VERSION "created by canmatrix"

NS_ :

BS_:

BU_:

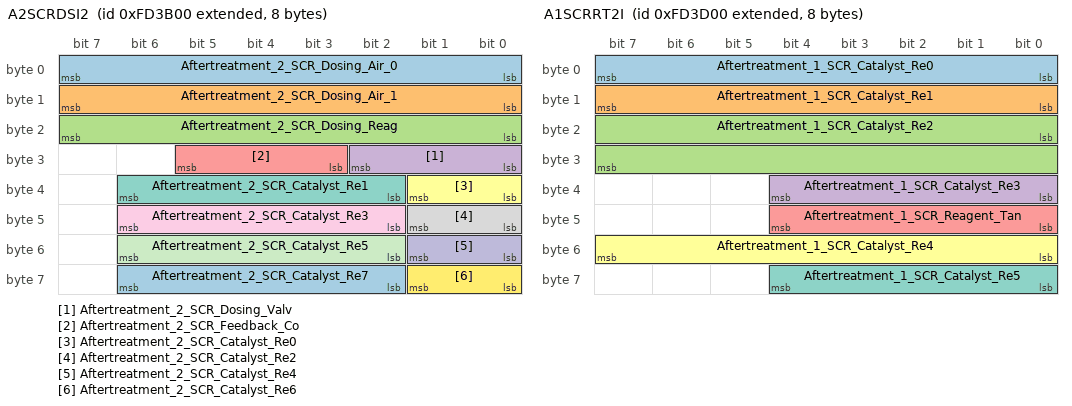
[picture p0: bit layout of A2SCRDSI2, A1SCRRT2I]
BO_ 2164079360 A2SCRDSI2: 8 Vector__XXX
 SG_ Aftertreatment_2_SCR_Dosing_Air_0 : 0|8@1+ (1,0) [0|255] "" Vector__XXX
 SG_ Aftertreatment_2_SCR_Dosing_Air_1 : 8|8@1+ (1,0) [0|255] "" Vector__XXX
 SG_ Aftertreatment_2_SCR_Dosing_Reag : 16|8@1+ (1,0) [0|255] "" Vector__XXX
 SG_ Aftertreatment_2_SCR_Dosing_Valv : 24|3@1+ (1,0) [0|7] "" Vector__XXX
 SG_ Aftertreatment_2_SCR_Feedback_Co : 27|3@1+ (1,0) [0|7] "" Vector__XXX
 SG_ Aftertreatment_2_SCR_Catalyst_Re0 : 32|2@1+ (1,0) [0|3] "" Vector__XXX
 SG_ Aftertreatment_2_SCR_Catalyst_Re1 : 34|5@1+ (1,0) [0|31] "" Vector__XXX
 SG_ Aftertreatment_2_SCR_Catalyst_Re2 : 40|2@1+ (1,0) [0|3] "" Vector__XXX
 SG_ Aftertreatment_2_SCR_Catalyst_Re3 : 42|5@1+ (1,0) [0|31] "" Vector__XXX
 SG_ Aftertreatment_2_SCR_Catalyst_Re4 : 48|2@1+ (1,0) [0|3] "" Vector__XXX
 SG_ Aftertreatment_2_SCR_Catalyst_Re5 : 50|5@1+ (1,0) [0|31] "" Vector__XXX
 SG_ Aftertreatment_2_SCR_Catalyst_Re6 : 56|2@1+ (1,0) [0|3] "" Vector__XXX
 SG_ Aftertreatment_2_SCR_Catalyst_Re7 : 58|5@1+ (1,0) [0|31] "" Vector__XXX

BO_ 2164079616 A1SCRRSI: 8 Vector__XXX
 SG_ Aftertreatment_1_SCR_Catalyst_Re0 : 0|16@1+ (1,0) [0|65535] "" Vector__XXX
 SG_ Aftertreatment_1_SCR_Catalyst_Re1 : 16|8@1+ (1,0) [0|255] "" Vector__XXX
 SG_ Aftertreatment_1_SCR_Catalyst_Re2 : 24|8@1+ (1,0) [0|255] "" Vector__XXX

BO_ 2164079872 A1SCRRT2I: 8 Vector__XXX
 SG_ Aftertreatment_1_SCR_Catalyst_Re0 : 0|8@1+ (1,0) [0|255] "" Vector__XXX
 SG_ Aftertreatment_1_SCR_Catalyst_Re1 : 8|8@1+ (1,0) [0|255] "" Vector__XXX
 SG_ Aftertreatment_1_SCR_Catalyst_Re2 : 16|16@1+ (1,0) [0|65535] "" Vector__XXX
 SG_ Aftertreatment_1_SCR_Catalyst_Re3 : 32|5@1+ (1,0) [0|31] "" Vector__XXX
 SG_ Aftertreatment_1_SCR_Reagent_Tan : 40|5@1+ (1,0) [0|31] "" Vector__XXX
 SG_ Aftertreatment_1_SCR_Catalyst_Re4 : 48|8@1+ (1,0) [0|255] "" Vector__XXX
 SG_ Aftertreatment_1_SCR_Catalyst_Re5 : 56|5@1+ (1,0) [0|31] "" Vector__XXX

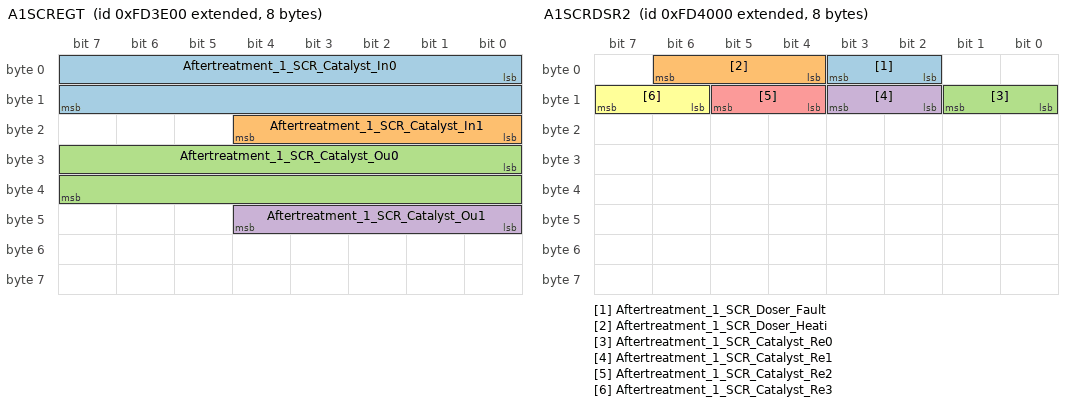
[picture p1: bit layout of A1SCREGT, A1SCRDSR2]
BO_ 2164080128 A1SCREGT: 8 Vector__XXX
 SG_ Aftertreatment_1_SCR_Catalyst_In0 : 0|16@1+ (1,0) [0|65535] "" Vector__XXX
 SG_ Aftertreatment_1_SCR_Catalyst_In1 : 16|5@1+ (1,0) [0|31] "" Vector__XXX
 SG_ Aftertreatment_1_SCR_Catalyst_Ou0 : 24|16@1+ (1,0) [0|65535] "" Vector__XXX
 SG_ Aftertreatment_1_SCR_Catalyst_Ou1 : 40|5@1+ (1,0) [0|31] "" Vector__XXX

BO_ 2164080384 A1SCREGP: 8 Vector__XXX
 SG_ Aftertreatment_1_SCR_Catalyst_Ex0 : 0|16@1+ (1,0) [0|65535] "" Vector__XXX
 SG_ Aftertreatment_1_SCR_Catalyst_Ex1 : 16|5@1+ (1,0) [0|31] "" Vector__XXX

BO_ 2164080640 A1SCRDSR2: 8 Vector__XXX
 SG_ Aftertreatment_1_SCR_Doser_Fault : 2|2@1+ (1,0) [0|3] "" Vector__XXX
 SG_ Aftertreatment_1_SCR_Doser_Heati : 4|3@1+ (1,0) [0|7] "" Vector__XXX
 SG_ Aftertreatment_1_SCR_Catalyst_Re0 : 8|2@1+ (1,0) [0|3] "" Vector__XXX
 SG_ Aftertreatment_1_SCR_Catalyst_Re1 : 10|2@1+ (1,0) [0|3] "" Vector__XXX
 SG_ Aftertreatment_1_SCR_Catalyst_Re2 : 12|2@1+ (1,0) [0|3] "" Vector__XXX
 SG_ Aftertreatment_1_SCR_Catalyst_Re3 : 14|2@1+ (1,0) [0|3] "" Vector__XXX

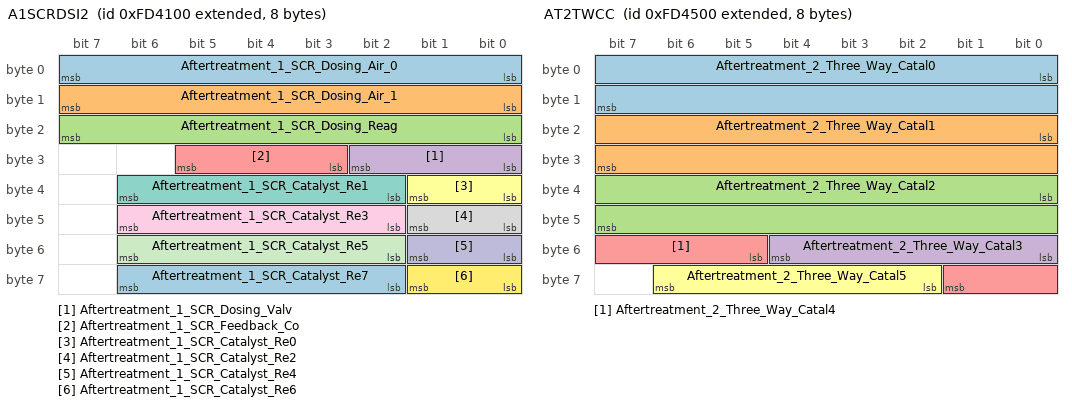
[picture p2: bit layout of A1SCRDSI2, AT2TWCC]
BO_ 2164080896 A1SCRDSI2: 8 Vector__XXX
 SG_ Aftertreatment_1_SCR_Dosing_Air_0 : 0|8@1+ (1,0) [0|255] "" Vector__XXX
 SG_ Aftertreatment_1_SCR_Dosing_Air_1 : 8|8@1+ (1,0) [0|255] "" Vector__XXX
 SG_ Aftertreatment_1_SCR_Dosing_Reag : 16|8@1+ (1,0) [0|255] "" Vector__XXX
 SG_ Aftertreatment_1_SCR_Dosing_Valv : 24|3@1+ (1,0) [0|7] "" Vector__XXX
 SG_ Aftertreatment_1_SCR_Feedback_Co : 27|3@1+ (1,0) [0|7] "" Vector__XXX
 SG_ Aftertreatment_1_SCR_Catalyst_Re0 : 32|2@1+ (1,0) [0|3] "" Vector__XXX
 SG_ Aftertreatment_1_SCR_Catalyst_Re1 : 34|5@1+ (1,0) [0|31] "" Vector__XXX
 SG_ Aftertreatment_1_SCR_Catalyst_Re2 : 40|2@1+ (1,0) [0|3] "" Vector__XXX
 SG_ Aftertreatment_1_SCR_Catalyst_Re3 : 42|5@1+ (1,0) [0|31] "" Vector__XXX
 SG_ Aftertreatment_1_SCR_Catalyst_Re4 : 48|2@1+ (1,0) [0|3] "" Vector__XXX
 SG_ Aftertreatment_1_SCR_Catalyst_Re5 : 50|5@1+ (1,0) [0|31] "" Vector__XXX
 SG_ Aftertreatment_1_SCR_Catalyst_Re6 : 56|2@1+ (1,0) [0|3] "" Vector__XXX
 SG_ Aftertreatment_1_SCR_Catalyst_Re7 : 58|5@1+ (1,0) [0|31] "" Vector__XXX

BO_ 2164081664 AT2FC2: 8 Vector__XXX
 SG_ Aftertreatment_2_Fuel_Pressure_2 : 0|16@1+ (1,0) [0|65535] "" Vector__XXX

BO_ 2164081920 AT2TWCC: 8 Vector__XXX
 SG_ Aftertreatment_2_Three_Way_Catal0 : 0|16@1+ (1,0) [0|65535] "" Vector__XXX
 SG_ Aftertreatment_2_Three_Way_Catal1 : 16|16@1+ (1,0) [0|65535] "" Vector__XXX
 SG_ Aftertreatment_2_Three_Way_Catal2 : 32|16@1+ (1,0) [0|65535] "" Vector__XXX
 SG_ Aftertreatment_2_Three_Way_Catal3 : 48|5@1+ (1,0) [0|31] "" Vector__XXX
 SG_ Aftertreatment_2_Three_Way_Catal4 : 53|5@1+ (1,0) [0|31] "" Vector__XXX
 SG_ Aftertreatment_2_Three_Way_Catal5 : 58|5@1+ (1,0) [0|31] "" Vector__XXX

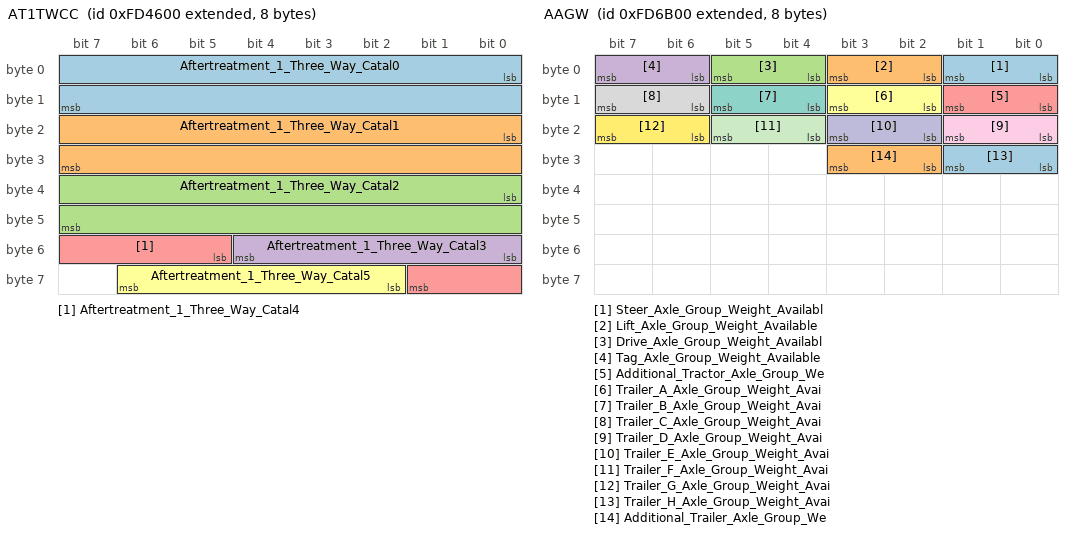
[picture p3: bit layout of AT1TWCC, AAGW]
BO_ 2164082176 AT1TWCC: 8 Vector__XXX
 SG_ Aftertreatment_1_Three_Way_Catal0 : 0|16@1+ (1,0) [0|65535] "" Vector__XXX
 SG_ Aftertreatment_1_Three_Way_Catal1 : 16|16@1+ (1,0) [0|65535] "" Vector__XXX
 SG_ Aftertreatment_1_Three_Way_Catal2 : 32|16@1+ (1,0) [0|65535] "" Vector__XXX
 SG_ Aftertreatment_1_Three_Way_Catal3 : 48|5@1+ (1,0) [0|31] "" Vector__XXX
 SG_ Aftertreatment_1_Three_Way_Catal4 : 53|5@1+ (1,0) [0|31] "" Vector__XXX
 SG_ Aftertreatment_1_Three_Way_Catal5 : 58|5@1+ (1,0) [0|31] "" Vector__XXX

BO_ 2164082432 TML: 8 Vector__XXX
 SG_ Transmission_Mode_Label : 0|200@1+ (1,0) [0|1.606938044258990275541962092E+060] "" Vector__XXX

BO_ 2164082688 O2FT2: 8 Vector__XXX
 SG_ Long_term_Fuel_Trim___Bank_2 : 0|16@1+ (1,0) [0|65535] "" Vector__XXX
 SG_ Short_term_Fuel_Trim___Bank_2 : 16|16@1+ (1,0) [0|65535] "" Vector__XXX
 SG_ Engine_Exhaust_Gas_Oxygen_Sensor : 32|4@1+ (1,0) [0|15] "" Vector__XXX

BO_ 2164082944 O2FT1: 8 Vector__XXX
 SG_ Long_term_Fuel_Trim___Bank_1 : 0|16@1+ (1,0) [0|65535] "" Vector__XXX
 SG_ Short_term_Fuel_Trim___Bank_1 : 16|16@1+ (1,0) [0|65535] "" Vector__XXX
 SG_ Engine_Exhaust_Gas_Oxygen_Sensor : 32|4@1+ (1,0) [0|15] "" Vector__XXX

BO_ 2164084992 ACCVC: 8 Vector__XXX
 SG_ Aftercooler_Coolant_Thermostat_M : 0|2@1+ (1,0) [0|3] "" Vector__XXX
 SG_ Desired_Aftercooler_Coolant_Inle : 8|8@1+ (1,0) [0|255] "" Vector__XXX
 SG_ Desired_Aftercooler_Coolant_Ther : 16|8@1+ (1,0) [0|255] "" Vector__XXX

BO_ 2164085248 ECCVC: 8 Vector__XXX
 SG_ Engine_Coolant_Thermostat_Mode : 0|2@1+ (1,0) [0|3] "" Vector__XXX
 SG_ Desired_Engine_Coolant_Pump_Outl : 8|8@1+ (1,0) [0|255] "" Vector__XXX
 SG_ Desired_Engine_Coolant_Thermosta : 16|8@1+ (1,0) [0|255] "" Vector__XXX

BO_ 2164085504 EAI: 8 Vector__XXX
 SG_ Engine_Exhaust_Gas_Temperature_A0 : 0|16@1+ (1,0) [0|65535] "" Vector__XXX
 SG_ Engine_Exhaust_Gas_Temperature_A1 : 16|16@1+ (1,0) [0|65535] "" Vector__XXX
 SG_ Engine_Exhaust_Gas_Temperature_A2 : 32|16@1+ (1,0) [0|65535] "" Vector__XXX

BO_ 2164090112 AT1FC2: 8 Vector__XXX
 SG_ Aftertreatment_1_Fuel_Pressure_2 : 0|16@1+ (1,0) [0|65535] "" Vector__XXX

BO_ 2164090368 ET4: 8 Vector__XXX
 SG_ Engine_Coolant_Temperature_2 : 0|8@1+ (1,0) [0|255] "" Vector__XXX
 SG_ Engine_Coolant_Pump_Outlet_Tempe : 8|8@1+ (1,0) [0|255] "" Vector__XXX
 SG_ Engine_Coolant_Thermostat_Openin : 16|8@1+ (1,0) [0|255] "" Vector__XXX
 SG_ Engine_Exhaust_Valve_Actuation_S : 24|16@1+ (1,0) [0|65535] "" Vector__XXX

BO_ 2164090624 ZNVW: 8 Vector__XXX
 SG_ Zero_Net_Vehicle_Weight_Change : 0|2@1+ (1,0) [0|3] "" Vector__XXX

BO_ 2164090880 GCVW: 8 Vector__XXX
 SG_ Gross_Combination_Weight : 0|24@1+ (1,0) [0|16777215] "" Vector__XXX
 SG_ Net_Vehicle_Weight_Change : 24|24@1+ (1,0) [0|16777215] "" Vector__XXX

BO_ 2164091136 AGCW: 8 Vector__XXX
 SG_ Axle_Group_Location : 0|4@1+ (1,0) [0|15] "" Vector__XXX
 SG_ Axle_Group_Empty_Weight_Calibrat : 8|16@1+ (1,0) [0|65535] "" Vector__XXX
 SG_ Axle_Group_Full_Weight_Calibrati : 24|16@1+ (1,0) [0|65535] "" Vector__XXX

BO_ 2164091392 AGW: 8 Vector__XXX
 SG_ Axle_Group_Location : 0|4@1+ (1,0) [0|15] "" Vector__XXX
 SG_ Axle_Group_Weight : 8|16@1+ (1,0) [0|65535] "" Vector__XXX

BO_ 2164091648 AAGW: 8 Vector__XXX
 SG_ Steer_Axle_Group_Weight_Availabl : 0|2@1+ (1,0) [0|3] "" Vector__XXX
 SG_ Lift_Axle_Group_Weight_Available : 2|2@1+ (1,0) [0|3] "" Vector__XXX
 SG_ Drive_Axle_Group_Weight_Availabl : 4|2@1+ (1,0) [0|3] "" Vector__XXX
 SG_ Tag_Axle_Group_Weight_Available : 6|2@1+ (1,0) [0|3] "" Vector__XXX
 SG_ Additional_Tractor_Axle_Group_We : 8|2@1+ (1,0) [0|3] "" Vector__XXX
 SG_ Trailer_A_Axle_Group_Weight_Avai : 10|2@1+ (1,0) [0|3] "" Vector__XXX
 SG_ Trailer_B_Axle_Group_Weight_Avai : 12|2@1+ (1,0) [0|3] "" Vector__XXX
 SG_ Trailer_C_Axle_Group_Weight_Avai : 14|2@1+ (1,0) [0|3] "" Vector__XXX
 SG_ Trailer_D_Axle_Group_Weight_Avai : 16|2@1+ (1,0) [0|3] "" Vector__XXX
 SG_ Trailer_E_Axle_Group_Weight_Avai : 18|2@1+ (1,0) [0|3] "" Vector__XXX
 SG_ Trailer_F_Axle_Group_Weight_Avai : 20|2@1+ (1,0) [0|3] "" Vector__XXX
 SG_ Trailer_G_Axle_Group_Weight_Avai : 22|2@1+ (1,0) [0|3] "" Vector__XXX
 SG_ Trailer_H_Axle_Group_Weight_Avai : 24|2@1+ (1,0) [0|3] "" Vector__XXX
 SG_ Additional_Trailer_Axle_Group_We : 26|2@1+ (1,0) [0|3] "" Vector__XXX

BO_ 2164091904 AT2AC2: 8 Vector__XXX
 SG_ Aftertreatment_2_Secondary_Air_D : 0|16@1+ (1,0) [0|65535] "" Vector__XXX
 SG_ Aftertreatment_2_Secondary_Air_T : 16|16@1+ (1,0) [0|65535] "" Vector__XXX
 SG_ Aftertreatment_2_Secondary_Air_M : 32|16@1+ (1,0) [0|65535] "" Vector__XXX
 SG_ Aftertreatment_2_Secondary_Air_P : 48|16@1+ (1,0) [0|65535] "" Vector__XXX

BO_ 2164092160 AT1AC2: 8 Vector__XXX
 SG_ Aftertreatment_1_Secondary_Air_D : 0|16@1+ (1,0) [0|65535] "" Vector__XXX
 SG_ Aftertreatment_1_Secondary_Air_T : 16|16@1+ (1,0) [0|65535] "" Vector__XXX
 SG_ Aftertreatment_1_Secondary_Air_M : 32|16@1+ (1,0) [0|65535] "" Vector__XXX
 SG_ Aftertreatment_1_Secondary_Air_P : 48|16@1+ (1,0) [0|65535] "" Vector__XXX

BO_ 2164092416 SCR1: 8 Vector__XXX
 SG_ Aftertreatment_1_SCR_Average_Cat : 0|16@1+ (1,0) [0|65535] "" Vector__XXX
 SG_ Aftertreatment_1_SCR_Commanded_C : 16|16@1+ (1,0) [0|65535] "" Vector__XXX
 SG_ Aftertreatment_1_SCR_Catalyst_Co : 32|8@1+ (1,0) [0|255] "" Vector__XXX

BO_ 2164092672 EEC8: 8 Vector__XXX
 SG_ Engine_Exhaust_Gas_Recirculation : 0|16@1+ (1,0) [0|65535] "" Vector__XXX

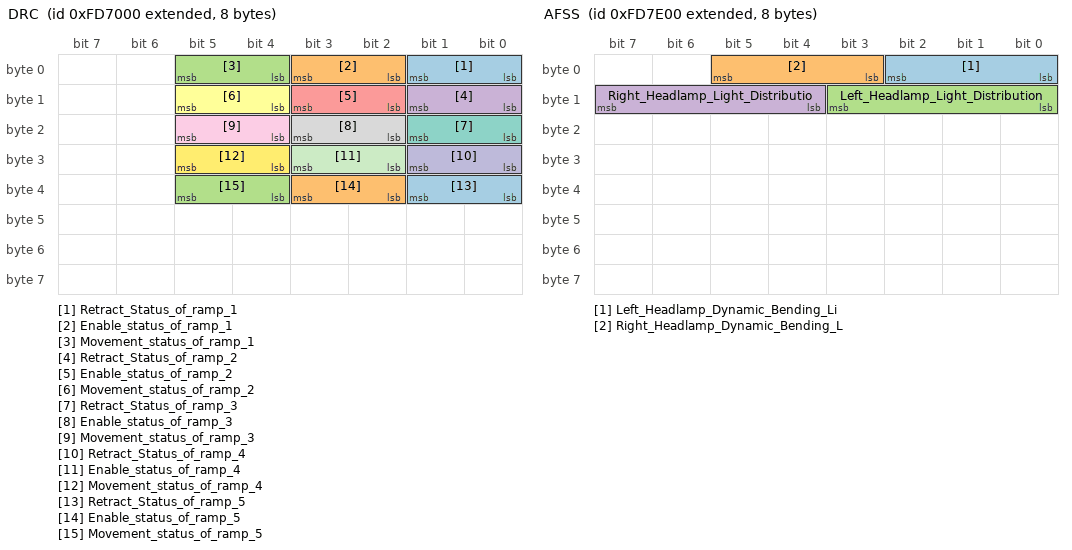
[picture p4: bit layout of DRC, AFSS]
BO_ 2164092928 DRC: 8 Vector__XXX
 SG_ Retract_Status_of_ramp_1 : 0|2@1+ (1,0) [0|3] "" Vector__XXX
 SG_ Enable_status_of_ramp_1 : 2|2@1+ (1,0) [0|3] "" Vector__XXX
 SG_ Movement_status_of_ramp_1 : 4|2@1+ (1,0) [0|3] "" Vector__XXX
 SG_ Retract_Status_of_ramp_2 : 8|2@1+ (1,0) [0|3] "" Vector__XXX
 SG_ Enable_status_of_ramp_2 : 10|2@1+ (1,0) [0|3] "" Vector__XXX
 SG_ Movement_status_of_ramp_2 : 12|2@1+ (1,0) [0|3] "" Vector__XXX
 SG_ Retract_Status_of_ramp_3 : 16|2@1+ (1,0) [0|3] "" Vector__XXX
 SG_ Enable_status_of_ramp_3 : 18|2@1+ (1,0) [0|3] "" Vector__XXX
 SG_ Movement_status_of_ramp_3 : 20|2@1+ (1,0) [0|3] "" Vector__XXX
 SG_ Retract_Status_of_ramp_4 : 24|2@1+ (1,0) [0|3] "" Vector__XXX
 SG_ Enable_status_of_ramp_4 : 26|2@1+ (1,0) [0|3] "" Vector__XXX
 SG_ Movement_status_of_ramp_4 : 28|2@1+ (1,0) [0|3] "" Vector__XXX
 SG_ Retract_Status_of_ramp_5 : 32|2@1+ (1,0) [0|3] "" Vector__XXX
 SG_ Enable_status_of_ramp_5 : 34|2@1+ (1,0) [0|3] "" Vector__XXX
 SG_ Movement_status_of_ramp_5 : 36|2@1+ (1,0) [0|3] "" Vector__XXX

BO_ 2164093184 BSA: 8 Vector__XXX
 SG_ Tractor_Brake_Stroke_Axle_1_Left : 0|3@1+ (1,0) [0|7] "" Vector__XXX
 SG_ Tractor_Brake_Stroke_Axle_1_Righ : 3|3@1+ (1,0) [0|7] "" Vector__XXX
 SG_ Tractor_Brake_Stroke_Axle_2_Left : 6|3@1+ (1,0) [0|7] "" Vector__XXX
 SG_ Tractor_Brake_Stroke_Axle_2_Righ : 9|3@1+ (1,0) [0|7] "" Vector__XXX
 SG_ Tractor_Brake_Stroke_Axle_3_Left : 12|3@1+ (1,0) [0|7] "" Vector__XXX
 SG_ Tractor_Brake_Stroke_Axle_3_Righ : 15|3@1+ (1,0) [0|7] "" Vector__XXX
 SG_ Tractor_Brake_Stroke_Axle_4_Left : 18|3@1+ (1,0) [0|7] "" Vector__XXX
 SG_ Tractor_Brake_Stroke_Axle_4_Righ : 21|3@1+ (1,0) [0|7] "" Vector__XXX
 SG_ Tractor_Brake_Stroke_Axle_5_Left : 24|3@1+ (1,0) [0|7] "" Vector__XXX
 SG_ Tractor_Brake_Stroke_Axle_5_Righ : 27|3@1+ (1,0) [0|7] "" Vector__XXX
 SG_ Trailer_Brake_Stroke_Axle_1_Left : 30|3@1+ (1,0) [0|7] "" Vector__XXX
 SG_ Trailer_Brake_Stroke_Axle_1_Righ : 33|3@1+ (1,0) [0|7] "" Vector__XXX
 SG_ Trailer_Brake_Stroke_Axle_2_Left : 36|3@1+ (1,0) [0|7] "" Vector__XXX
 SG_ Trailer_Brake_Stroke_Axle_2_Righ : 39|3@1+ (1,0) [0|7] "" Vector__XXX
 SG_ Trailer_Brake_Stroke_Axle_3_Left : 42|3@1+ (1,0) [0|7] "" Vector__XXX
 SG_ Trailer_Brake_Stroke_Axle_3_Righ : 45|3@1+ (1,0) [0|7] "" Vector__XXX
 SG_ Trailer_Brake_Stroke_Axle_4_Left : 48|3@1+ (1,0) [0|7] "" Vector__XXX
 SG_ Trailer_Brake_Stroke_Axle_4_Righ : 51|3@1+ (1,0) [0|7] "" Vector__XXX
 SG_ Trailer_Brake_Stroke_Axle_5_Left : 54|3@1+ (1,0) [0|7] "" Vector__XXX
 SG_ Trailer_Brake_Stroke_Axle_5_Righ : 57|3@1+ (1,0) [0|7] "" Vector__XXX

BO_ 2164093440 ESV6: 8 Vector__XXX
 SG_ Engine_Spark_Plug_21 : 0|16@1+ (1,0) [0|65535] "" Vector__XXX
 SG_ Engine_Spark_Plug_22 : 16|16@1+ (1,0) [0|65535] "" Vector__XXX
 SG_ Engine_Spark_Plug_23 : 32|16@1+ (1,0) [0|65535] "" Vector__XXX
 SG_ Engine_Spark_Plug_24 : 48|16@1+ (1,0) [0|65535] "" Vector__XXX

BO_ 2164093696 ESV5: 8 Vector__XXX
 SG_ Engine_Spark_Plug_17 : 0|16@1+ (1,0) [0|65535] "" Vector__XXX
 SG_ Engine_Spark_Plug_18 : 16|16@1+ (1,0) [0|65535] "" Vector__XXX
 SG_ Engine_Spark_Plug_19 : 32|16@1+ (1,0) [0|65535] "" Vector__XXX
 SG_ Engine_Spark_Plug_20 : 48|16@1+ (1,0) [0|65535] "" Vector__XXX

BO_ 2164093952 ESV4: 8 Vector__XXX
 SG_ Engine_Spark_Plug_13 : 0|16@1+ (1,0) [0|65535] "" Vector__XXX
 SG_ Engine_Spark_Plug_14 : 16|16@1+ (1,0) [0|65535] "" Vector__XXX
 SG_ Engine_Spark_Plug_15 : 32|16@1+ (1,0) [0|65535] "" Vector__XXX
 SG_ Engine_Spark_Plug_16 : 48|16@1+ (1,0) [0|65535] "" Vector__XXX

BO_ 2164094208 ESV3: 8 Vector__XXX
 SG_ Engine_Spark_Plug_9 : 0|16@1+ (1,0) [0|65535] "" Vector__XXX
 SG_ Engine_Spark_Plug_10 : 16|16@1+ (1,0) [0|65535] "" Vector__XXX
 SG_ Engine_Spark_Plug_11 : 32|16@1+ (1,0) [0|65535] "" Vector__XXX
 SG_ Engine_Spark_Plug_12 : 48|16@1+ (1,0) [0|65535] "" Vector__XXX

BO_ 2164094464 ESV2: 8 Vector__XXX
 SG_ Engine_Spark_Plug_5 : 0|16@1+ (1,0) [0|65535] "" Vector__XXX
 SG_ Engine_Spark_Plug_6 : 16|16@1+ (1,0) [0|65535] "" Vector__XXX
 SG_ Engine_Spark_Plug_7 : 32|16@1+ (1,0) [0|65535] "" Vector__XXX
 SG_ Engine_Spark_Plug_8 : 48|16@1+ (1,0) [0|65535] "" Vector__XXX

BO_ 2164094720 ESV1: 8 Vector__XXX
 SG_ Engine_Spark_Plug_1 : 0|16@1+ (1,0) [0|65535] "" Vector__XXX
 SG_ Engine_Spark_Plug_2 : 16|16@1+ (1,0) [0|65535] "" Vector__XXX
 SG_ Engine_Spark_Plug_3 : 32|16@1+ (1,0) [0|65535] "" Vector__XXX
 SG_ Engine_Spark_Plug_4 : 48|16@1+ (1,0) [0|65535] "" Vector__XXX

BO_ 2164094976 AT2TI: 32 Vector__XXX
 SG_ Aftertreatment_2_Trip_Fuel_Used : 0|32@1+ (1,0) [0|4294967295] "" Vector__XXX
 SG_ Aftertreatment_2_Trip_Active_Reg : 32|32@1+ (1,0) [0|4294967295] "" Vector__XXX
 SG_ Aftertreatment_2_Trip_Disabled_T : 64|32@1+ (1,0) [0|4294967295] "" Vector__XXX
 SG_ Aftertreatment_2_Trip_Number_of_0 : 96|32@1+ (1,0) [0|4294967295] "" Vector__XXX
 SG_ Aftertreatment_2_Trip_Passive_Re : 128|32@1+ (1,0) [0|4294967295] "" Vector__XXX
 SG_ Aftertreatment_2_Trip_Number_of_1 : 160|32@1+ (1,0) [0|4294967295] "" Vector__XXX
 SG_ Aftertreatment_2_Trip_Number_of_2 : 192|32@1+ (1,0) [0|4294967295] "" Vector__XXX
 SG_ Aftertreatment_2_Trip_Number_of_3 : 224|32@1+ (1,0) [0|4294967295] "" Vector__XXX

BO_ 2164095232 AT1TI: 32 Vector__XXX
 SG_ Aftertreatment_1_Trip_Fuel_Used : 0|32@1+ (1,0) [0|4294967295] "" Vector__XXX
 SG_ Aftertreatment_1_Trip_Active_Reg : 32|32@1+ (1,0) [0|4294967295] "" Vector__XXX
 SG_ Aftertreatment_1_Trip_Disabled_T : 64|32@1+ (1,0) [0|4294967295] "" Vector__XXX
 SG_ Aftertreatment_1_Trip_Number_of_0 : 96|32@1+ (1,0) [0|4294967295] "" Vector__XXX
 SG_ Aftertreatment_1_Trip_Passive_Re : 128|32@1+ (1,0) [0|4294967295] "" Vector__XXX
 SG_ Aftertreatment_1_Trip_Number_of_1 : 160|32@1+ (1,0) [0|4294967295] "" Vector__XXX
 SG_ Aftertreatment_1_Trip_Number_of_2 : 192|32@1+ (1,0) [0|4294967295] "" Vector__XXX
 SG_ Aftertreatment_1_Trip_Number_of_3 : 224|32@1+ (1,0) [0|4294967295] "" Vector__XXX

BO_ 2164095488 AT2S: 8 Vector__XXX
 SG_ Diesel_Particulate_Filter_2_Soot : 0|8@1+ (1,0) [0|255] "" Vector__XXX
 SG_ Diesel_Particulate_Filter_2_Ash_ : 8|8@1+ (1,0) [0|255] "" Vector__XXX
 SG_ Diesel_Particulate_Filter_2_Time : 16|32@1+ (1,0) [0|4294967295] "" Vector__XXX

BO_ 2164095744 AT1S: 8 Vector__XXX
 SG_ Diesel_Particulate_Filter_1_Soot : 0|8@1+ (1,0) [0|255] "" Vector__XXX
 SG_ Diesel_Particulate_Filter_1_Ash_ : 8|8@1+ (1,0) [0|255] "" Vector__XXX
 SG_ Diesel_Particulate_Filter_1_Time : 16|32@1+ (1,0) [0|4294967295] "" Vector__XXX

BO_ 2164096000 DPFC1: 8 Vector__XXX
 SG_ Diesel_Particulate_Filter_Lamp_C : 0|3@1+ (1,0) [0|7] "" Vector__XXX
 SG_ Diesel_Particulate_Filter_Passiv : 8|2@1+ (1,0) [0|3] "" Vector__XXX
 SG_ Diesel_Particulate_Filter_Active0 : 10|2@1+ (1,0) [0|3] "" Vector__XXX
 SG_ Diesel_Particulate_Filter_Status : 12|3@1+ (1,0) [0|7] "" Vector__XXX
 SG_ Diesel_Particulate_Filter_Active1 : 16|2@1+ (1,0) [0|3] "" Vector__XXX
 SG_ Diesel_Particulate_Filter_Active2 : 18|2@1+ (1,0) [0|3] "" Vector__XXX
 SG_ Diesel_Particulate_Filter_Active3 : 20|2@1+ (1,0) [0|3] "" Vector__XXX
 SG_ Diesel_Particulate_Filter_Active4 : 22|2@1+ (1,0) [0|3] "" Vector__XXX
 SG_ Diesel_Particulate_Filter_Active5 : 24|2@1+ (1,0) [0|3] "" Vector__XXX
 SG_ Diesel_Particulate_Filter_Active6 : 26|2@1+ (1,0) [0|3] "" Vector__XXX
 SG_ Diesel_Particulate_Filter_Active7 : 28|2@1+ (1,0) [0|3] "" Vector__XXX
 SG_ Diesel_Particulate_Filter_Active8 : 30|2@1+ (1,0) [0|3] "" Vector__XXX
 SG_ Diesel_Particulate_Filter_Active9 : 32|2@1+ (1,0) [0|3] "" Vector__XXX
 SG_ Diesel_Particulate_Filter_Active10 : 34|2@1+ (1,0) [0|3] "" Vector__XXX
 SG_ Diesel_Particulate_Filter_Active11 : 36|2@1+ (1,0) [0|3] "" Vector__XXX
 SG_ Diesel_Particulate_Filter_Active12 : 38|2@1+ (1,0) [0|3] "" Vector__XXX
 SG_ Diesel_Particulate_Filter_Active13 : 40|2@1+ (1,0) [0|3] "" Vector__XXX
 SG_ Diesel_Particulate_Filter_Active14 : 42|2@1+ (1,0) [0|3] "" Vector__XXX
 SG_ Diesel_Particulate_Filter_Active15 : 44|2@1+ (1,0) [0|3] "" Vector__XXX
 SG_ Diesel_Particulate_Filter_Active16 : 46|2@1+ (1,0) [0|3] "" Vector__XXX
 SG_ Diesel_Particulate_Filter_Automa : 48|2@1+ (1,0) [0|3] "" Vector__XXX
 SG_ Exhaust_System_High_Temperature_ : 50|3@1+ (1,0) [0|7] "" Vector__XXX
 SG_ Diesel_Particulate_Filter_Active17 : 53|3@1+ (1,0) [0|7] "" Vector__XXX

BO_ 2164096512 AFSS: 8 Vector__XXX
 SG_ Left_Headlamp_Dynamic_Bending_Li : 0|3@1+ (1,0) [0|7] "" Vector__XXX
 SG_ Right_Headlamp_Dynamic_Bending_L : 3|3@1+ (1,0) [0|7] "" Vector__XXX
 SG_ Left_Headlamp_Light_Distribution : 8|4@1+ (1,0) [0|15] "" Vector__XXX
 SG_ Right_Headlamp_Light_Distributio : 12|4@1+ (1,0) [0|15] "" Vector__XXX

BO_ 2164096768 EC2: 8 Vector__XXX
 SG_ Maximum_Crank_Attempts_per_Start : 0|8@1+ (1,0) [0|255] "" Vector__XXX

BO_ 2164097280 EGRBV: 8 Vector__XXX
 SG_ EGR_Cooler_Bypass_Actuator_Posti : 0|8@1+ (1,0) [0|255] "" Vector__XXX

BO_ 2164097792 TCI: 8 Vector__XXX
 SG_ Transfer_case_status : 0|3@1+ (1,0) [0|7] "" Vector__XXX

BO_ 2164098048 EFL_P9: 8 Vector__XXX
 SG_ Engine_Intake_Valve_Actuation_Oi0 : 0|16@1+ (1,0) [0|65535] "" Vector__XXX
 SG_ Engine_Intake_Valve_Actuation_Oi1 : 16|16@1+ (1,0) [0|65535] "" Vector__XXX
 SG_ Engine_Intake_Valve_Actuation_Oi2 : 32|16@1+ (1,0) [0|65535] "" Vector__XXX
 SG_ Engine_Intake_Valve_Actuation_Oi3 : 48|16@1+ (1,0) [0|65535] "" Vector__XXX

BO_ 2164098304 EFL_P8: 8 Vector__XXX
 SG_ Engine_Intake_Valve_Actuation_Oi0 : 0|16@1+ (1,0) [0|65535] "" Vector__XXX
 SG_ Engine_Intake_Valve_Actuation_Oi1 : 16|16@1+ (1,0) [0|65535] "" Vector__XXX
 SG_ Engine_Intake_Valve_Actuation_Oi2 : 32|16@1+ (1,0) [0|65535] "" Vector__XXX
 SG_ Engine_Intake_Valve_Actuation_Oi3 : 48|16@1+ (1,0) [0|65535] "" Vector__XXX

BO_ 2164098560 EFL_P7: 8 Vector__XXX
 SG_ Engine_Intake_Valve_Actuation_Oi0 : 0|16@1+ (1,0) [0|65535] "" Vector__XXX
 SG_ Engine_Intake_Valve_Actuation_Oi1 : 16|16@1+ (1,0) [0|65535] "" Vector__XXX
 SG_ Engine_Intake_Valve_Actuation_Oi2 : 32|16@1+ (1,0) [0|65535] "" Vector__XXX
 SG_ Engine_Intake_Valve_Actuation_Oi3 : 48|16@1+ (1,0) [0|65535] "" Vector__XXX

BO_ 2164098816 EFL_P6: 8 Vector__XXX
 SG_ Engine_Intake_Valve_Actuation_Oi0 : 0|16@1+ (1,0) [0|65535] "" Vector__XXX
 SG_ Engine_Intake_Valve_Actuation_Oi1 : 16|16@1+ (1,0) [0|65535] "" Vector__XXX
 SG_ Engine_Intake_Valve_Actuation_Oi2 : 32|16@1+ (1,0) [0|65535] "" Vector__XXX
 SG_ Engine_Intake_Valve_Actuation_Oi3 : 48|16@1+ (1,0) [0|65535] "" Vector__XXX

BO_ 2164099072 EFL_P5: 8 Vector__XXX
 SG_ Engine_Intake_Valve_Actuation_Oi0 : 0|16@1+ (1,0) [0|65535] "" Vector__XXX
 SG_ Engine_Intake_Valve_Actuation_Oi1 : 16|16@1+ (1,0) [0|65535] "" Vector__XXX
 SG_ Engine_Intake_Valve_Actuation_Oi2 : 32|16@1+ (1,0) [0|65535] "" Vector__XXX
 SG_ Engine_Intake_Valve_Actuation_Oi3 : 48|16@1+ (1,0) [0|65535] "" Vector__XXX

BO_ 2164099328 VDS2: 8 Vector__XXX
 SG_ Vehicle_Roll : 0|16@1+ (1,0) [0|65535] "" Vector__XXX

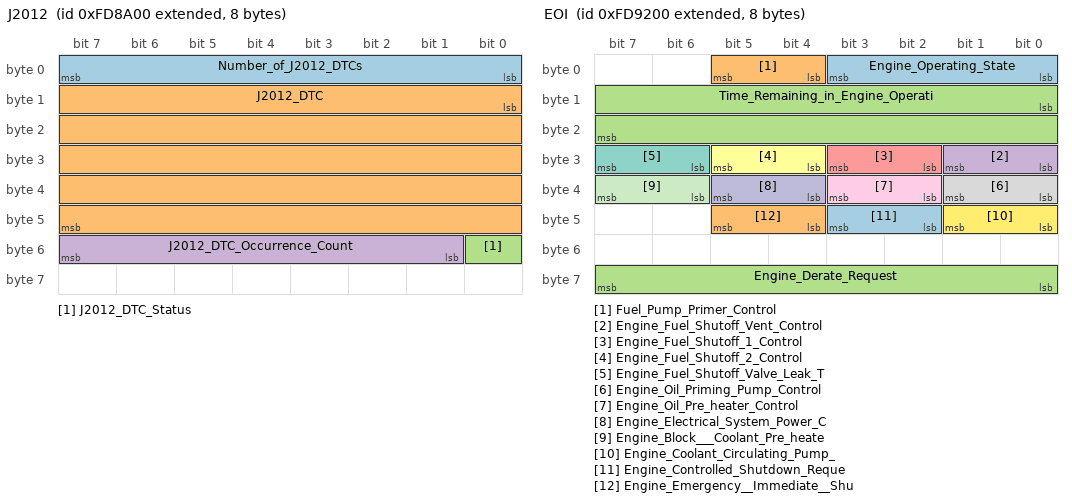
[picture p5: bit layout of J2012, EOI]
BO_ 2164099584 J2012: 8 Vector__XXX
 SG_ Number_of_J2012_DTCs : 0|8@1+ (1,0) [0|255] "" Vector__XXX
 SG_ J2012_DTC : 8|40@1+ (1,0) [0|1099511627775] "" Vector__XXX
 SG_ J2012_DTC_Status : 48|1@1+ (1,0) [0|1] "" Vector__XXX
 SG_ J2012_DTC_Occurrence_Count : 49|7@1+ (1,0) [0|127] "" Vector__XXX

BO_ 2164099840 AT2GP: 8 Vector__XXX
 SG_ Diesel_Particulate_Filter_Intake : 0|16@1+ (1,0) [0|65535] "" Vector__XXX
 SG_ Diesel_Particulate_Filter_Outlet : 16|16@1+ (1,0) [0|65535] "" Vector__XXX

BO_ 2164100096 AT1GP: 8 Vector__XXX
 SG_ Diesel_Particulate_Filter_Intake : 0|16@1+ (1,0) [0|65535] "" Vector__XXX
 SG_ Diesel_Particulate_Filter_Outlet : 16|16@1+ (1,0) [0|65535] "" Vector__XXX

BO_ 2164101120 AETC: 8 Vector__XXX
 SG_ AETC_Data_Collection_Standard : 0|4@1+ (1,0) [0|15] "" Vector__XXX
 SG_ Number_of_AETC_data_points : 4|4@1+ (1,0) [0|15] "" Vector__XXX
 SG_ AETC_Speed_Value : 0|16@1+ (1,0) [0|65535] "" Vector__XXX
 SG_ AETC_Torque_value : 0|16@1+ (1,0) [0|65535] "" Vector__XXX

BO_ 2164101632 EOI: 8 Vector__XXX
 SG_ Engine_Operating_State : 0|4@1+ (1,0) [0|15] "" Vector__XXX
 SG_ Fuel_Pump_Primer_Control : 4|2@1+ (1,0) [0|3] "" Vector__XXX
 SG_ Time_Remaining_in_Engine_Operati : 8|16@1+ (1,0) [0|65535] "" Vector__XXX
 SG_ Engine_Fuel_Shutoff_Vent_Control : 24|2@1+ (1,0) [0|3] "" Vector__XXX
 SG_ Engine_Fuel_Shutoff_1_Control : 26|2@1+ (1,0) [0|3] "" Vector__XXX
 SG_ Engine_Fuel_Shutoff_2_Control : 28|2@1+ (1,0) [0|3] "" Vector__XXX
 SG_ Engine_Fuel_Shutoff_Valve_Leak_T : 30|2@1+ (1,0) [0|3] "" Vector__XXX
 SG_ Engine_Oil_Priming_Pump_Control : 32|2@1+ (1,0) [0|3] "" Vector__XXX
 SG_ Engine_Oil_Pre_heater_Control : 34|2@1+ (1,0) [0|3] "" Vector__XXX
 SG_ Engine_Electrical_System_Power_C : 36|2@1+ (1,0) [0|3] "" Vector__XXX
 SG_ Engine_Block___Coolant_Pre_heate : 38|2@1+ (1,0) [0|3] "" Vector__XXX
 SG_ Engine_Coolant_Circulating_Pump_ : 40|2@1+ (1,0) [0|3] "" Vector__XXX
 SG_ Engine_Controlled_Shutdown_Reque : 42|2@1+ (1,0) [0|3] "" Vector__XXX
 SG_ Engine_Emergency__Immediate__Shu : 44|2@1+ (1,0) [0|3] "" Vector__XXX
 SG_ Engine_Derate_Request : 56|8@1+ (1,0) [0|255] "" Vector__XXX

BO_ 2164102144 EEC7: 8 Vector__XXX
 SG_ Engine_Exhaust_Gas_Recirculation0 : 0|16@1+ (1,0) [0|65535] "" Vector__XXX
 SG_ Engine_Exhaust_Gas_Recirculation1 : 16|16@1+ (1,0) [0|65535] "" Vector__XXX

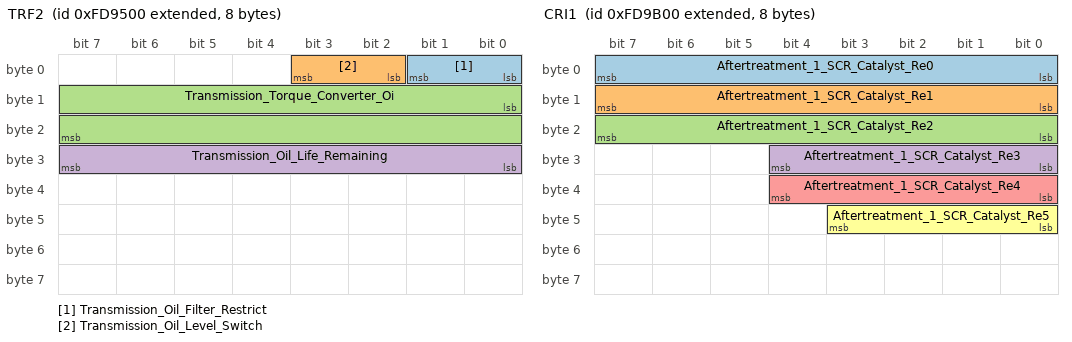
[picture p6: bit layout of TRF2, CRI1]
BO_ 2164102400 TRF2: 8 Vector__XXX
 SG_ Transmission_Oil_Filter_Restrict : 0|2@1+ (1,0) [0|3] "" Vector__XXX
 SG_ Transmission_Oil_Level_Switch : 2|2@1+ (1,0) [0|3] "" Vector__XXX
 SG_ Transmission_Torque_Converter_Oi : 8|16@1+ (1,0) [0|65535] "" Vector__XXX
 SG_ Transmission_Oil_Life_Remaining : 24|8@1+ (1,0) [0|255] "" Vector__XXX

BO_ 2164103168 AT1HI: 32 Vector__XXX
 SG_ Aftertreatment_1_Total_Fuel_Used : 0|32@1+ (1,0) [0|4294967295] "" Vector__XXX
 SG_ Aftertreatment_1_Total_Regenerat : 32|32@1+ (1,0) [0|4294967295] "" Vector__XXX
 SG_ Aftertreatment_1_Total_Disabled_ : 64|32@1+ (1,0) [0|4294967295] "" Vector__XXX
 SG_ Aftertreatment_1_Total_Number_of0 : 96|32@1+ (1,0) [0|4294967295] "" Vector__XXX
 SG_ Aftertreatment_1_Total_Passive_R : 128|32@1+ (1,0) [0|4294967295] "" Vector__XXX
 SG_ Aftertreatment_1_Total_Number_of1 : 160|32@1+ (1,0) [0|4294967295] "" Vector__XXX
 SG_ Aftertreatment_1_Total_Number_of2 : 192|32@1+ (1,0) [0|4294967295] "" Vector__XXX
 SG_ Aftertreatment_1_Total_Number_of3 : 224|32@1+ (1,0) [0|4294967295] "" Vector__XXX

BO_ 2164103424 AT2HI: 32 Vector__XXX
 SG_ Aftertreatment_2_Total_Fuel_Used : 0|32@1+ (1,0) [0|4294967295] "" Vector__XXX
 SG_ Aftertreatment_2_Total_Regenerat : 32|32@1+ (1,0) [0|4294967295] "" Vector__XXX
 SG_ Aftertreatment_2_Total_Disabled_ : 64|32@1+ (1,0) [0|4294967295] "" Vector__XXX
 SG_ Aftertreatment_2_Total_Number_of0 : 96|32@1+ (1,0) [0|4294967295] "" Vector__XXX
 SG_ Aftertreatment_2_Total_Passive_R : 128|32@1+ (1,0) [0|4294967295] "" Vector__XXX
 SG_ Aftertreatment_2_Total_Number_of1 : 160|32@1+ (1,0) [0|4294967295] "" Vector__XXX
 SG_ Aftertreatment_2_Total_Number_of2 : 192|32@1+ (1,0) [0|4294967295] "" Vector__XXX
 SG_ Aftertreatment_2_Total_Number_of3 : 224|32@1+ (1,0) [0|4294967295] "" Vector__XXX

BO_ 2164103936 CRI1: 8 Vector__XXX
 SG_ Aftertreatment_1_SCR_Catalyst_Re0 : 0|8@1+ (1,0) [0|255] "" Vector__XXX
 SG_ Aftertreatment_1_SCR_Catalyst_Re1 : 8|8@1+ (1,0) [0|255] "" Vector__XXX
 SG_ Aftertreatment_1_SCR_Catalyst_Re2 : 16|8@1+ (1,0) [0|255] "" Vector__XXX
 SG_ Aftertreatment_1_SCR_Catalyst_Re3 : 24|5@1+ (1,0) [0|31] "" Vector__XXX
 SG_ Aftertreatment_1_SCR_Catalyst_Re4 : 32|5@1+ (1,0) [0|31] "" Vector__XXX
 SG_ Aftertreatment_1_SCR_Catalyst_Re5 : 40|4@1+ (1,0) [0|15] "" Vector__XXX

BO_ 2164104192 SEP2: 8 Vector__XXX
 SG_ Sensor_supply_voltage_5 : 0|16@1+ (1,0) [0|65535] "" Vector__XXX
 SG_ Sensor_supply_voltage_6 : 16|16@1+ (1,0) [0|65535] "" Vector__XXX

BO_ 2164104448 SEP1: 8 Vector__XXX
 SG_ Sensor_supply_voltage_1 : 0|16@1+ (1,0) [0|65535] "" Vector__XXX
 SG_ Sensor_supply_voltage_2 : 16|16@1+ (1,0) [0|65535] "" Vector__XXX
 SG_ Sensor_supply_voltage_3 : 32|16@1+ (1,0) [0|65535] "" Vector__XXX
 SG_ Sensor_supply_voltage_4 : 48|16@1+ (1,0) [0|65535] "" Vector__XXX

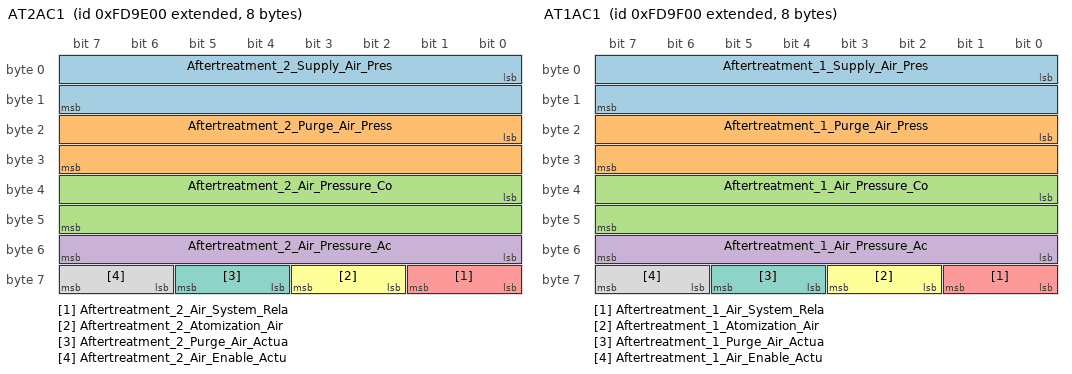
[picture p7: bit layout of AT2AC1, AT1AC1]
BO_ 2164104704 AT2AC1: 8 Vector__XXX
 SG_ Aftertreatment_2_Supply_Air_Pres : 0|16@1+ (1,0) [0|65535] "" Vector__XXX
 SG_ Aftertreatment_2_Purge_Air_Press : 16|16@1+ (1,0) [0|65535] "" Vector__XXX
 SG_ Aftertreatment_2_Air_Pressure_Co : 32|16@1+ (1,0) [0|65535] "" Vector__XXX
 SG_ Aftertreatment_2_Air_Pressure_Ac : 48|8@1+ (1,0) [0|255] "" Vector__XXX
 SG_ Aftertreatment_2_Air_System_Rela : 56|2@1+ (1,0) [0|3] "" Vector__XXX
 SG_ Aftertreatment_2_Atomization_Air : 58|2@1+ (1,0) [0|3] "" Vector__XXX
 SG_ Aftertreatment_2_Purge_Air_Actua : 60|2@1+ (1,0) [0|3] "" Vector__XXX
 SG_ Aftertreatment_2_Air_Enable_Actu : 62|2@1+ (1,0) [0|3] "" Vector__XXX

BO_ 2164104960 AT1AC1: 8 Vector__XXX
 SG_ Aftertreatment_1_Supply_Air_Pres : 0|16@1+ (1,0) [0|65535] "" Vector__XXX
 SG_ Aftertreatment_1_Purge_Air_Press : 16|16@1+ (1,0) [0|65535] "" Vector__XXX
 SG_ Aftertreatment_1_Air_Pressure_Co : 32|16@1+ (1,0) [0|65535] "" Vector__XXX
 SG_ Aftertreatment_1_Air_Pressure_Ac : 48|8@1+ (1,0) [0|255] "" Vector__XXX
 SG_ Aftertreatment_1_Air_System_Rela : 56|2@1+ (1,0) [0|3] "" Vector__XXX
 SG_ Aftertreatment_1_Atomization_Air : 58|2@1+ (1,0) [0|3] "" Vector__XXX
 SG_ Aftertreatment_1_Purge_Air_Actua : 60|2@1+ (1,0) [0|3] "" Vector__XXX
 SG_ Aftertreatment_1_Air_Enable_Actu : 62|2@1+ (1,0) [0|3] "" Vector__XXX

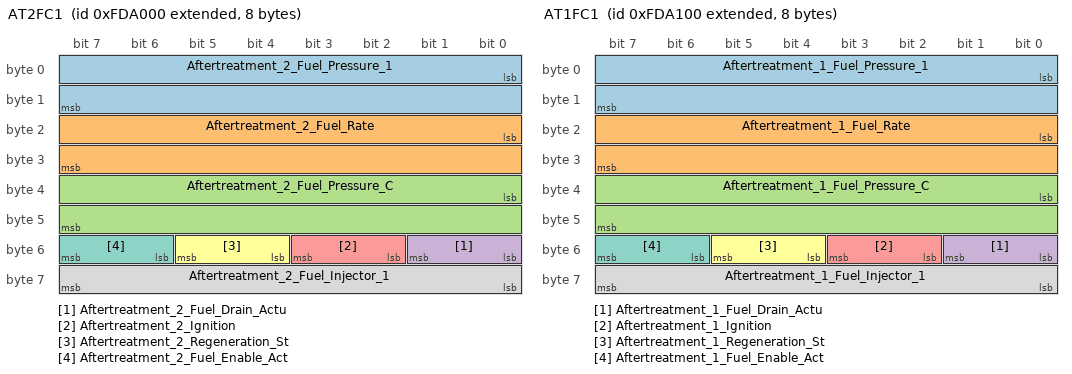
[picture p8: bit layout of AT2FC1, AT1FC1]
BO_ 2164105216 AT2FC1: 8 Vector__XXX
 SG_ Aftertreatment_2_Fuel_Pressure_1 : 0|16@1+ (1,0) [0|65535] "" Vector__XXX
 SG_ Aftertreatment_2_Fuel_Rate : 16|16@1+ (1,0) [0|65535] "" Vector__XXX
 SG_ Aftertreatment_2_Fuel_Pressure_C : 32|16@1+ (1,0) [0|65535] "" Vector__XXX
 SG_ Aftertreatment_2_Fuel_Drain_Actu : 48|2@1+ (1,0) [0|3] "" Vector__XXX
 SG_ Aftertreatment_2_Ignition : 50|2@1+ (1,0) [0|3] "" Vector__XXX
 SG_ Aftertreatment_2_Regeneration_St : 52|2@1+ (1,0) [0|3] "" Vector__XXX
 SG_ Aftertreatment_2_Fuel_Enable_Act : 54|2@1+ (1,0) [0|3] "" Vector__XXX
 SG_ Aftertreatment_2_Fuel_Injector_1 : 56|8@1+ (1,0) [0|255] "" Vector__XXX

BO_ 2164105472 AT1FC1: 8 Vector__XXX
 SG_ Aftertreatment_1_Fuel_Pressure_1 : 0|16@1+ (1,0) [0|65535] "" Vector__XXX
 SG_ Aftertreatment_1_Fuel_Rate : 16|16@1+ (1,0) [0|65535] "" Vector__XXX
 SG_ Aftertreatment_1_Fuel_Pressure_C : 32|16@1+ (1,0) [0|65535] "" Vector__XXX
 SG_ Aftertreatment_1_Fuel_Drain_Actu : 48|2@1+ (1,0) [0|3] "" Vector__XXX
 SG_ Aftertreatment_1_Ignition : 50|2@1+ (1,0) [0|3] "" Vector__XXX
 SG_ Aftertreatment_1_Regeneration_St : 52|2@1+ (1,0) [0|3] "" Vector__XXX
 SG_ Aftertreatment_1_Fuel_Enable_Act : 54|2@1+ (1,0) [0|3] "" Vector__XXX
 SG_ Aftertreatment_1_Fuel_Injector_1 : 56|8@1+ (1,0) [0|255] "" Vector__XXX

BO_ 2164105728 GFI3: 8 Vector__XXX
 SG_ Engine_Fuel_Valve_2_Inlet_Absolu : 0|16@1+ (1,0) [0|65535] "" Vector__XXX
 SG_ Engine_Gas_2_Mass_Flow_Rate : 16|16@1+ (1,0) [0|65535] "" Vector__XXX
 SG_ Engine_Fuel_Temperature_2 : 32|8@1+ (1,0) [0|255] "" Vector__XXX
 SG_ Engine_Fuel_Valve_2_Outlet_Abso : 48|16@1+ (1,0) [0|65535] "" Vector__XXX

BO_ 2164105984 EEC6: 8 Vector__XXX
 SG_ Engine_Turbocharger_Compressor_C : 0|16@1+ (1,0) [0|65535] "" Vector__XXX
 SG_ Engine_Variable_Geometry_Turboch : 16|8@1+ (1,0) [0|255] "" Vector__XXX
 SG_ Engine_Turbocharger_Compressor_B : 24|8@1+ (1,0) [0|255] "" Vector__XXX

BO_ 2164106240 PTODE: 8 Vector__XXX
 SG_ Enable_Switch___Transfer_case_ou : 0|2@1+ (1,0) [0|3] "" Vector__XXX
 SG_ Enable_Switch___Transmission_out : 2|2@1+ (1,0) [0|3] "" Vector__XXX
 SG_ Enable_Switch___Transmission_inp : 4|2@1+ (1,0) [0|3] "" Vector__XXX
 SG_ Enable_Switch___Transmission_inp : 6|2@1+ (1,0) [0|3] "" Vector__XXX
 SG_ Enable_Switch___PTO_Engine_Flywh : 8|2@1+ (1,0) [0|3] "" Vector__XXX
 SG_ Enable_Switch___PTO_Engine_Acces : 10|2@1+ (1,0) [0|3] "" Vector__XXX
 SG_ Enable_Switch___PTO_Engine_Acces : 12|2@1+ (1,0) [0|3] "" Vector__XXX
 SG_ Engagement_Consent___Transfer_ca : 16|2@1+ (1,0) [0|3] "" Vector__XXX
 SG_ Engagement_Consent___Transmissio0 : 18|2@1+ (1,0) [0|3] "" Vector__XXX
 SG_ Engagement_Consent___Transmissio1 : 20|2@1+ (1,0) [0|3] "" Vector__XXX
 SG_ Engagement_Consent___Transmissio2 : 22|2@1+ (1,0) [0|3] "" Vector__XXX
 SG_ Engagement_Consent___PTO_Engine_0 : 24|2@1+ (1,0) [0|3] "" Vector__XXX
 SG_ Engagement_Consent___PTO_Engine_1 : 26|2@1+ (1,0) [0|3] "" Vector__XXX
 SG_ Engagement_Consent___PTO_Engine_2 : 28|2@1+ (1,0) [0|3] "" Vector__XXX
 SG_ Engagement_Status___Transfer_cas : 32|2@1+ (1,0) [0|3] "" Vector__XXX
 SG_ Engagement_Status___Transmission0 : 34|2@1+ (1,0) [0|3] "" Vector__XXX
 SG_ Engagement_Status___Transmission1 : 36|2@1+ (1,0) [0|3] "" Vector__XXX
 SG_ Engagement_Status___Transmission2 : 38|2@1+ (1,0) [0|3] "" Vector__XXX
 SG_ Engagement_Status___PTO_Engine_F : 40|2@1+ (1,0) [0|3] "" Vector__XXX
 SG_ Engagement_Status___PTO_Engine_A : 42|2@1+ (1,0) [0|3] "" Vector__XXX
 SG_ Engagement_Status___PTO_Engine_A : 44|2@1+ (1,0) [0|3] "" Vector__XXX
 SG_ At_least_one_PTO_engaged : 48|2@1+ (1,0) [0|3] "" Vector__XXX

BO_ 2164106496 DC2: 8 Vector__XXX
 SG_ Lock_Status_of_Door_1 : 0|2@1+ (1,0) [0|3] "" Vector__XXX
 SG_ Open_Status_of_Door_1 : 2|2@1+ (1,0) [0|3] "" Vector__XXX
 SG_ Enable_Status_of_Door_1 : 4|2@1+ (1,0) [0|3] "" Vector__XXX
 SG_ Lock_Status_of_Door_2 : 6|2@1+ (1,0) [0|3] "" Vector__XXX
 SG_ Open_Status_of_Door_2 : 8|2@1+ (1,0) [0|3] "" Vector__XXX
 SG_ Enable_Status_of_Door_2 : 10|2@1+ (1,0) [0|3] "" Vector__XXX
 SG_ Lock_Status_of_Door_3 : 12|2@1+ (1,0) [0|3] "" Vector__XXX
 SG_ Open_Status_of_Door_3 : 14|2@1+ (1,0) [0|3] "" Vector__XXX
 SG_ Enable_Status_of_Door_3 : 16|2@1+ (1,0) [0|3] "" Vector__XXX
 SG_ Lock_Status_of_Door_4 : 18|2@1+ (1,0) [0|3] "" Vector__XXX
 SG_ Open_Status_of_Door_4 : 20|2@1+ (1,0) [0|3] "" Vector__XXX
 SG_ Enable_Status_of_Door_4 : 22|2@1+ (1,0) [0|3] "" Vector__XXX
 SG_ Lock_Status_of_Door_5 : 24|2@1+ (1,0) [0|3] "" Vector__XXX
 SG_ Open_Status_of_Door_5 : 26|2@1+ (1,0) [0|3] "" Vector__XXX
 SG_ Enable_Status_of_Door_5 : 28|2@1+ (1,0) [0|3] "" Vector__XXX
 SG_ Lock_Status_of_Door_6 : 30|2@1+ (1,0) [0|3] "" Vector__XXX
 SG_ Open_Status_of_Door_6 : 32|2@1+ (1,0) [0|3] "" Vector__XXX
 SG_ Enable_Status_of_Door_6 : 34|2@1+ (1,0) [0|3] "" Vector__XXX
 SG_ Lock_Status_of_Door_7 : 36|2@1+ (1,0) [0|3] "" Vector__XXX
 SG_ Open_Status_of_Door_7 : 38|2@1+ (1,0) [0|3] "" Vector__XXX
 SG_ Enable_Status_of_Door_7 : 40|2@1+ (1,0) [0|3] "" Vector__XXX
 SG_ Lock_Status_of_Door_8 : 42|2@1+ (1,0) [0|3] "" Vector__XXX
 SG_ Open_Status_of_Door_8 : 44|2@1+ (1,0) [0|3] "" Vector__XXX
 SG_ Enable_Status_of_Door_8 : 46|2@1+ (1,0) [0|3] "" Vector__XXX
 SG_ Lock_Status_of_Door_9 : 48|2@1+ (1,0) [0|3] "" Vector__XXX
 SG_ Open_Status_of_Door_9 : 50|2@1+ (1,0) [0|3] "" Vector__XXX
 SG_ Enable_Status_of_Door_9 : 52|2@1+ (1,0) [0|3] "" Vector__XXX
 SG_ Lock_Status_of_Door_10 : 54|2@1+ (1,0) [0|3] "" Vector__XXX
 SG_ Open_Status_of_Door_10 : 56|2@1+ (1,0) [0|3] "" Vector__XXX
 SG_ Enable_Status_of_Door_10 : 58|2@1+ (1,0) [0|3] "" Vector__XXX

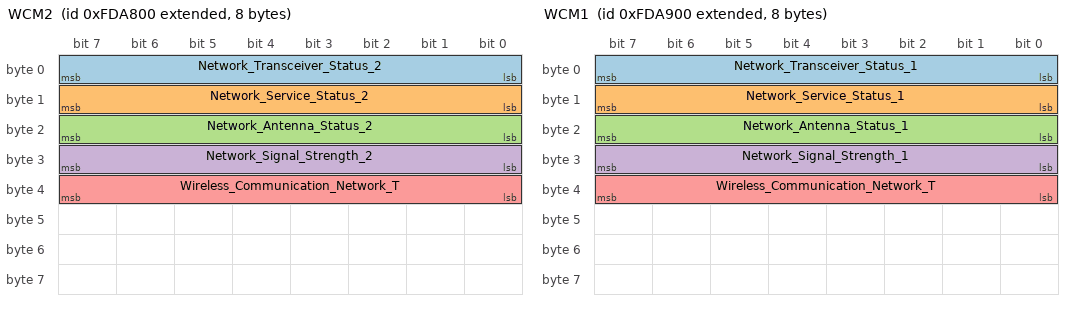
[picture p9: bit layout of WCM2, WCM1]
BO_ 2164107264 WCM2: 8 Vector__XXX
 SG_ Network_Transceiver_Status_2 : 0|8@1+ (1,0) [0|255] "" Vector__XXX
 SG_ Network_Service_Status_2 : 8|8@1+ (1,0) [0|255] "" Vector__XXX
 SG_ Network_Antenna_Status_2 : 16|8@1+ (1,0) [0|255] "" Vector__XXX
 SG_ Network_Signal_Strength_2 : 24|8@1+ (1,0) [0|255] "" Vector__XXX
 SG_ Wireless_Communication_Network_T : 32|8@1+ (1,0) [0|255] "" Vector__XXX

BO_ 2164107520 WCM1: 8 Vector__XXX
 SG_ Network_Transceiver_Status_1 : 0|8@1+ (1,0) [0|255] "" Vector__XXX
 SG_ Network_Service_Status_1 : 8|8@1+ (1,0) [0|255] "" Vector__XXX
 SG_ Network_Antenna_Status_1 : 16|8@1+ (1,0) [0|255] "" Vector__XXX
 SG_ Network_Signal_Strength_1 : 24|8@1+ (1,0) [0|255] "" Vector__XXX
 SG_ Wireless_Communication_Network_T : 32|8@1+ (1,0) [0|255] "" Vector__XXX

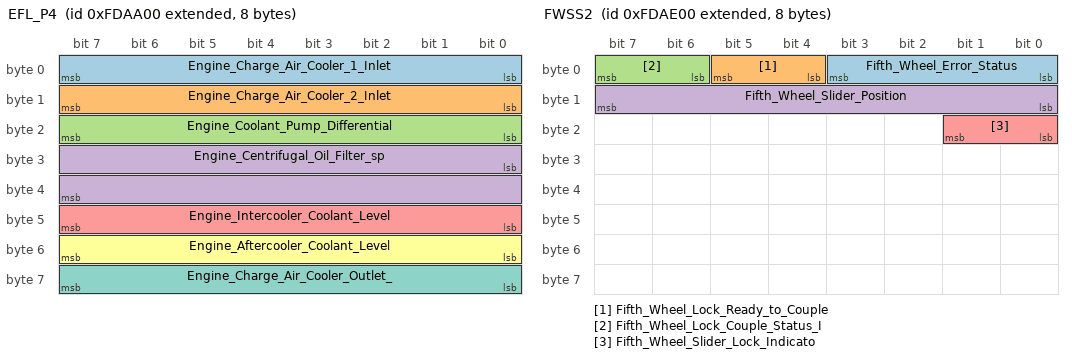
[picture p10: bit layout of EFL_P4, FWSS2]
BO_ 2164107776 EFL_P4: 8 Vector__XXX
 SG_ Engine_Charge_Air_Cooler_1_Inlet : 0|8@1+ (1,0) [0|255] "" Vector__XXX
 SG_ Engine_Charge_Air_Cooler_2_Inlet : 8|8@1+ (1,0) [0|255] "" Vector__XXX
 SG_ Engine_Coolant_Pump_Differential : 16|8@1+ (1,0) [0|255] "" Vector__XXX
 SG_ Engine_Centrifugal_Oil_Filter_sp : 24|16@1+ (1,0) [0|65535] "" Vector__XXX
 SG_ Engine_Intercooler_Coolant_Level : 40|8@1+ (1,0) [0|255] "" Vector__XXX
 SG_ Engine_Aftercooler_Coolant_Level : 48|8@1+ (1,0) [0|255] "" Vector__XXX
 SG_ Engine_Charge_Air_Cooler_Outlet_ : 56|8@1+ (1,0) [0|255] "" Vector__XXX

BO_ 2164108800 FWSS2: 8 Vector__XXX
 SG_ Fifth_Wheel_Error_Status : 0|4@1+ (1,0) [0|15] "" Vector__XXX
 SG_ Fifth_Wheel_Lock_Ready_to_Couple : 4|2@1+ (1,0) [0|3] "" Vector__XXX
 SG_ Fifth_Wheel_Lock_Couple_Status_I : 6|2@1+ (1,0) [0|3] "" Vector__XXX
 SG_ Fifth_Wheel_Slider_Position : 8|8@1+ (1,0) [0|255] "" Vector__XXX
 SG_ Fifth_Wheel_Slider_Lock_Indicato : 16|2@1+ (1,0) [0|3] "" Vector__XXX

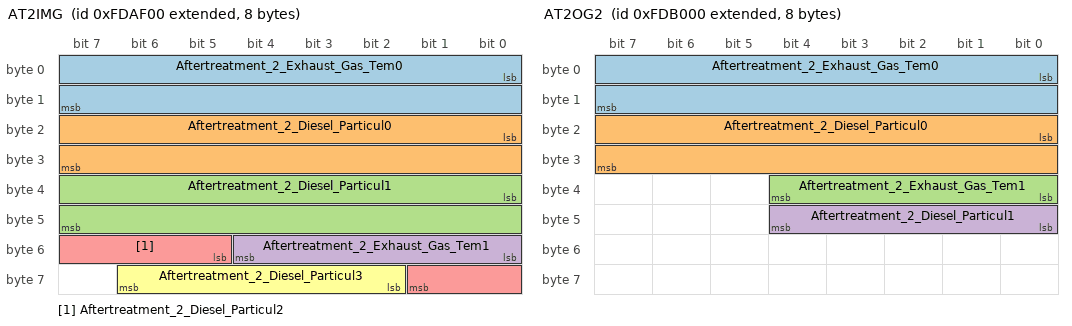
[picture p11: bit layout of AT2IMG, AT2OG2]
BO_ 2164109056 AT2IMG: 8 Vector__XXX
 SG_ Aftertreatment_2_Exhaust_Gas_Tem0 : 0|16@1+ (1,0) [0|65535] "" Vector__XXX
 SG_ Aftertreatment_2_Diesel_Particul0 : 16|16@1+ (1,0) [0|65535] "" Vector__XXX
 SG_ Aftertreatment_2_Diesel_Particul1 : 32|16@1+ (1,0) [0|65535] "" Vector__XXX
 SG_ Aftertreatment_2_Exhaust_Gas_Tem1 : 48|5@1+ (1,0) [0|31] "" Vector__XXX
 SG_ Aftertreatment_2_Diesel_Particul2 : 53|5@1+ (1,0) [0|31] "" Vector__XXX
 SG_ Aftertreatment_2_Diesel_Particul3 : 58|5@1+ (1,0) [0|31] "" Vector__XXX

BO_ 2164109312 AT2OG2: 8 Vector__XXX
 SG_ Aftertreatment_2_Exhaust_Gas_Tem0 : 0|16@1+ (1,0) [0|65535] "" Vector__XXX
 SG_ Aftertreatment_2_Diesel_Particul0 : 16|16@1+ (1,0) [0|65535] "" Vector__XXX
 SG_ Aftertreatment_2_Exhaust_Gas_Tem1 : 32|5@1+ (1,0) [0|31] "" Vector__XXX
 SG_ Aftertreatment_2_Diesel_Particul1 : 40|5@1+ (1,0) [0|31] "" Vector__XXX

BO_ 2164109568 AT2IG2: 8 Vector__XXX
 SG_ Aftertreatment_2_Exhaust_Gas_Tem0 : 0|16@1+ (1,0) [0|65535] "" Vector__XXX
 SG_ Aftertreatment_2_Diesel_Particul0 : 16|16@1+ (1,0) [0|65535] "" Vector__XXX
 SG_ Aftertreatment_2_Exhaust_Gas_Tem1 : 32|5@1+ (1,0) [0|31] "" Vector__XXX
 SG_ Aftertreatment_2_Diesel_Particul1 : 40|5@1+ (1,0) [0|31] "" Vector__XXX

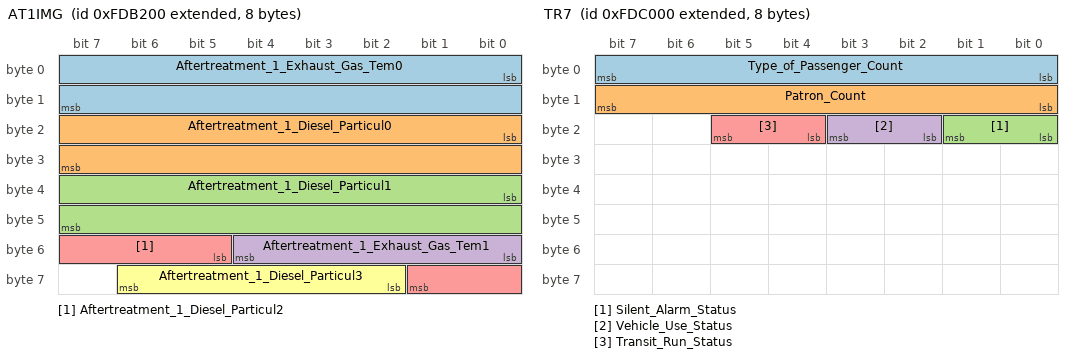
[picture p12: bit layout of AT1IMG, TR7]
BO_ 2164109824 AT1IMG: 8 Vector__XXX
 SG_ Aftertreatment_1_Exhaust_Gas_Tem0 : 0|16@1+ (1,0) [0|65535] "" Vector__XXX
 SG_ Aftertreatment_1_Diesel_Particul0 : 16|16@1+ (1,0) [0|65535] "" Vector__XXX
 SG_ Aftertreatment_1_Diesel_Particul1 : 32|16@1+ (1,0) [0|65535] "" Vector__XXX
 SG_ Aftertreatment_1_Exhaust_Gas_Tem1 : 48|5@1+ (1,0) [0|31] "" Vector__XXX
 SG_ Aftertreatment_1_Diesel_Particul2 : 53|5@1+ (1,0) [0|31] "" Vector__XXX
 SG_ Aftertreatment_1_Diesel_Particul3 : 58|5@1+ (1,0) [0|31] "" Vector__XXX

BO_ 2164110080 AT1OG2: 8 Vector__XXX
 SG_ Aftertreatment_1_Exhaust_Gas_Tem0 : 0|16@1+ (1,0) [0|65535] "" Vector__XXX
 SG_ Aftertreatment_1_Diesel_Particul0 : 16|16@1+ (1,0) [0|65535] "" Vector__XXX
 SG_ Aftertreatment_1_Exhaust_Gas_Tem1 : 32|5@1+ (1,0) [0|31] "" Vector__XXX
 SG_ Aftertreatment_1_Diesel_Particul1 : 40|5@1+ (1,0) [0|31] "" Vector__XXX

BO_ 2164110336 AT1IG2: 8 Vector__XXX
 SG_ Aftertreatment_1_Exhaust_Gas_Tem0 : 0|16@1+ (1,0) [0|65535] "" Vector__XXX
 SG_ Aftertreatment_1_Diesel_Particul0 : 16|16@1+ (1,0) [0|65535] "" Vector__XXX
 SG_ Aftertreatment_1_Exhaust_Gas_Tem1 : 32|5@1+ (1,0) [0|31] "" Vector__XXX
 SG_ Aftertreatment_1_Diesel_Particul1 : 40|5@1+ (1,0) [0|31] "" Vector__XXX

BO_ 2164111616 TPRI: 8 Vector__XXX
 SG_ Tire_Location : 0|8@1+ (1,0) [0|255] "" Vector__XXX
 SG_ Reference_Tire_Pressure : 8|8@1+ (1,0) [0|255] "" Vector__XXX

BO_ 2164111872 TR6: 8 Vector__XXX
 SG_ Farebox_Emergency_Status : 0|2@1+ (1,0) [0|3] "" Vector__XXX
 SG_ Farebox_Alarm_Identifier : 8|7@1+ (1,0) [0|127] "" Vector__XXX

BO_ 2164112128 TR5: 8 Vector__XXX
 SG_ Transaction_Type : 0|4@1+ (1,0) [0|15] "" Vector__XXX
 SG_ Passenger_Type : 4|4@1+ (1,0) [0|15] "" Vector__XXX
 SG_ Type_of_Fare : 8|4@1+ (1,0) [0|15] "" Vector__XXX
 SG_ Payment_Details : 12|4@1+ (1,0) [0|15] "" Vector__XXX
 SG_ Fare_Validity : 16|4@1+ (1,0) [0|15] "" Vector__XXX
 SG_ Pass_Category : 20|4@1+ (1,0) [0|15] "" Vector__XXX
 SG_ Initial_Fare_Agency : 24|5@1+ (1,0) [0|31] "" Vector__XXX
 SG_ Type_of_Service : 32|3@1+ (1,0) [0|7] "" Vector__XXX
 SG_ Transfer_Type : 35|5@1+ (1,0) [0|31] "" Vector__XXX
 SG_ Route_Number : 0|12@1+ (1,0) [0|4095] "" Vector__XXX
 SG_ Transfer_Sold : 56|8@1+ (1,0) [0|255] "" Vector__XXX

BO_ 2164112384 TR4: 15 Vector__XXX
 SG_ Farebox_Service_Status : 0|2@1+ (1,0) [0|3] "" Vector__XXX
 SG_ Trip_Status : 2|3@1+ (1,0) [0|7] "" Vector__XXX
 SG_ Trip_Direction : 8|4@1+ (1,0) [0|15] "" Vector__XXX
 SG_ Fare_Presets : 16|8@1+ (1,0) [0|255] "" Vector__XXX
 SG_ Trip_Number : 24|16@1+ (1,0) [0|65535] "" Vector__XXX
 SG_ Pattern_Number_ : 40|16@1+ (1,0) [0|65535] "" Vector__XXX
 SG_ Assigned_Route : 56|16@1+ (1,0) [0|65535] "" Vector__XXX
 SG_ Assigned_Run : 72|16@1+ (1,0) [0|65535] "" Vector__XXX
 SG_ Assigned_Block : 88|16@1+ (1,0) [0|65535] "" Vector__XXX
 SG_ Driver_s_farebox_security_code : 104|16@1+ (1,0) [0|65535] "" Vector__XXX

BO_ 2164112640 TR3: 8 Vector__XXX
 SG_ Range_Code_Enable : 2|2@1+ (1,0) [0|3] "" Vector__XXX
 SG_ Transit_Route_ID_Usage : 4|2@1+ (1,0) [0|3] "" Vector__XXX
 SG_ Intersection_Preemption_Request_ : 6|2@1+ (1,0) [0|3] "" Vector__XXX
 SG_ Priority_of_Response_Sent_by_Emi : 8|4@1+ (1,0) [0|15] "" Vector__XXX
 SG_ Transit_Door_Enable : 12|2@1+ (1,0) [0|3] "" Vector__XXX
 SG_ Strobe_Activation_Control_Status : 14|2@1+ (1,0) [0|3] "" Vector__XXX
 SG_ Vehicle_ID : 0|16@1+ (1,0) [0|65535] "" Vector__XXX

BO_ 2164112896 TR1: 8 Vector__XXX
 SG_ Agency : 0|8@1+ (1,0) [0|255] "" Vector__XXX
 SG_ Number_of_bytes_in_the_Transit_A0 : 8|8@1+ (1,0) [0|255] "" Vector__XXX
 SG_ Number_of_bytes_in_the_Transit_A1 : 16|8@1+ (1,0) [0|255] "" Vector__XXX
 SG_ Number_of_bytes_in_the_Transit_A2 : 24|8@1+ (1,0) [0|255] "" Vector__XXX
 SG_ Transit_Assigned_Route_Identity : 32|800@1+ (1,0) [0|6.668014432879854274079851791E+240] "" Vector__XXX
 SG_ Transit_Assigned_Run_Identity : 0|800@1+ (1,0) [0|6.668014432879854274079851791E+240] "" Vector__XXX
 SG_ Transit_Assigned_Block_Identity : 0|800@1+ (1,0) [0|6.668014432879854274079851791E+240] "" Vector__XXX

BO_ 2164113152 TR2: 8 Vector__XXX
 SG_ Number_of_bytes_in_the_Milepost_ : 0|8@1+ (1,0) [0|255] "" Vector__XXX
 SG_ Milepost_Identification : 8|800@1+ (1,0) [0|6.668014432879854274079851791E+240] "" Vector__XXX

BO_ 2164113408 TR7: 8 Vector__XXX
 SG_ Type_of_Passenger_Count : 0|8@1+ (1,0) [0|255] "" Vector__XXX
 SG_ Patron_Count : 8|8@1+ (1,0) [0|255] "" Vector__XXX
 SG_ Silent_Alarm_Status : 16|2@1+ (1,0) [0|3] "" Vector__XXX
 SG_ Vehicle_Use_Status : 18|2@1+ (1,0) [0|3] "" Vector__XXX
 SG_ Transit_Run_Status : 20|2@1+ (1,0) [0|3] "" Vector__XXX

BO_ 2164113664 EFL_P3: 8 Vector__XXX
 SG_ Engine_Intake_Valve_Actuation_Sy : 0|16@1+ (1,0) [0|65535] "" Vector__XXX
 SG_ Engine_Exhaust_Gas_Recirculation : 16|8@1+ (1,0) [0|255] "" Vector__XXX
 SG_ Engine_Exhaust_Valve_Actuation_S : 24|16@1+ (1,0) [0|65535] "" Vector__XXX

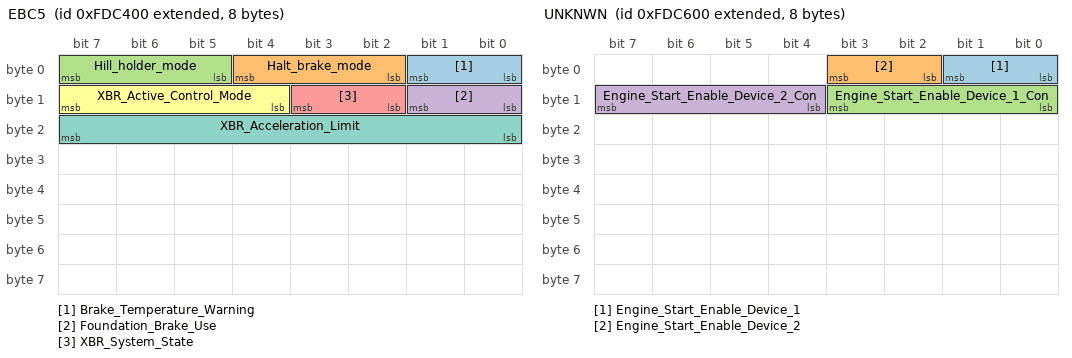
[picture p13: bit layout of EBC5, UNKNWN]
BO_ 2164114432 EBC5: 8 Vector__XXX
 SG_ Brake_Temperature_Warning : 0|2@1+ (1,0) [0|3] "" Vector__XXX
 SG_ Halt_brake_mode : 2|3@1+ (1,0) [0|7] "" Vector__XXX
 SG_ Hill_holder_mode : 5|3@1+ (1,0) [0|7] "" Vector__XXX
 SG_ Foundation_Brake_Use : 8|2@1+ (1,0) [0|3] "" Vector__XXX
 SG_ XBR_System_State : 10|2@1+ (1,0) [0|3] "" Vector__XXX
 SG_ XBR_Active_Control_Mode : 12|4@1+ (1,0) [0|15] "" Vector__XXX
 SG_ XBR_Acceleration_Limit : 16|8@1+ (1,0) [0|255] "" Vector__XXX

BO_ 2164114688 ECUID: 8 Vector__XXX
 SG_ ECU_Part_Number : 0|1600@1+ (1,0) [0|4.446241647709404462001681407E+481] "" Vector__XXX
 SG_ ECU_Serial_Number : 0|1600@1+ (1,0) [0|4.446241647709404462001681407E+481] "" Vector__XXX
 SG_ ECU_Location : 0|1600@1+ (1,0) [0|4.446241647709404462001681407E+481] "" Vector__XXX
 SG_ ECU_Type : 0|1600@1+ (1,0) [0|4.446241647709404462001681407E+481] "" Vector__XXX
 SG_ ECU_Manufacturer_Name : 0|1600@1+ (1,0) [0|4.446241647709404462001681407E+481] "" Vector__XXX

BO_ 2164114944 UNKNWN: 8 Vector__XXX
 SG_ Engine_Start_Enable_Device_1 : 0|2@1+ (1,0) [0|3] "" Vector__XXX
 SG_ Engine_Start_Enable_Device_2 : 2|2@1+ (1,0) [0|3] "" Vector__XXX
 SG_ Engine_Start_Enable_Device_1_Con : 8|4@1+ (1,0) [0|15] "" Vector__XXX
 SG_ Engine_Start_Enable_Device_2_Con : 12|4@1+ (1,0) [0|15] "" Vector__XXX

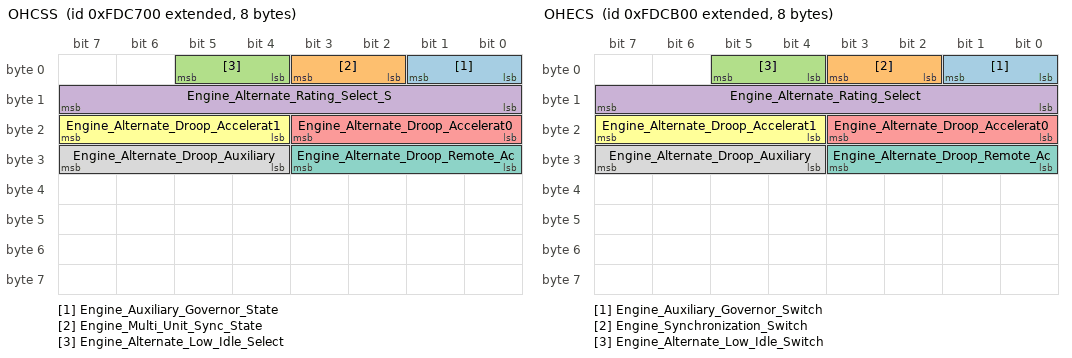
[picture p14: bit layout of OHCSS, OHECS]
BO_ 2164115200 OHCSS: 8 Vector__XXX
 SG_ Engine_Auxiliary_Governor_State : 0|2@1+ (1,0) [0|3] "" Vector__XXX
 SG_ Engine_Multi_Unit_Sync_State : 2|2@1+ (1,0) [0|3] "" Vector__XXX
 SG_ Engine_Alternate_Low_Idle_Select : 4|2@1+ (1,0) [0|3] "" Vector__XXX
 SG_ Engine_Alternate_Rating_Select_S : 8|8@1+ (1,0) [0|255] "" Vector__XXX
 SG_ Engine_Alternate_Droop_Accelerat0 : 16|4@1+ (1,0) [0|15] "" Vector__XXX
 SG_ Engine_Alternate_Droop_Accelerat1 : 20|4@1+ (1,0) [0|15] "" Vector__XXX
 SG_ Engine_Alternate_Droop_Remote_Ac : 24|4@1+ (1,0) [0|15] "" Vector__XXX
 SG_ Engine_Alternate_Droop_Auxiliary : 28|4@1+ (1,0) [0|15] "" Vector__XXX

BO_ 2164115456 ISCS: 8 Vector__XXX
 SG_ Engine_Operator_Primary_Intermed : 0|4@1+ (1,0) [0|15] "" Vector__XXX

BO_ 2164115712 CMI: 8 Vector__XXX
 SG_ Total_Count_of_Configuration_Cha : 0|16@1+ (1,0) [0|65535] "" Vector__XXX

BO_ 2164115968 ISC: 8 Vector__XXX
 SG_ Engine_Operator_Primary_Intermed : 0|4@1+ (1,0) [0|15] "" Vector__XXX

BO_ 2164116224 OHECS: 8 Vector__XXX
 SG_ Engine_Auxiliary_Governor_Switch : 0|2@1+ (1,0) [0|3] "" Vector__XXX
 SG_ Engine_Synchronization_Switch : 2|2@1+ (1,0) [0|3] "" Vector__XXX
 SG_ Engine_Alternate_Low_Idle_Switch : 4|2@1+ (1,0) [0|3] "" Vector__XXX
 SG_ Engine_Alternate_Rating_Select : 8|8@1+ (1,0) [0|255] "" Vector__XXX
 SG_ Engine_Alternate_Droop_Accelerat0 : 16|4@1+ (1,0) [0|15] "" Vector__XXX
 SG_ Engine_Alternate_Droop_Accelerat1 : 20|4@1+ (1,0) [0|15] "" Vector__XXX
 SG_ Engine_Alternate_Droop_Remote_Ac : 24|4@1+ (1,0) [0|15] "" Vector__XXX
 SG_ Engine_Alternate_Droop_Auxiliary : 28|4@1+ (1,0) [0|15] "" Vector__XXX

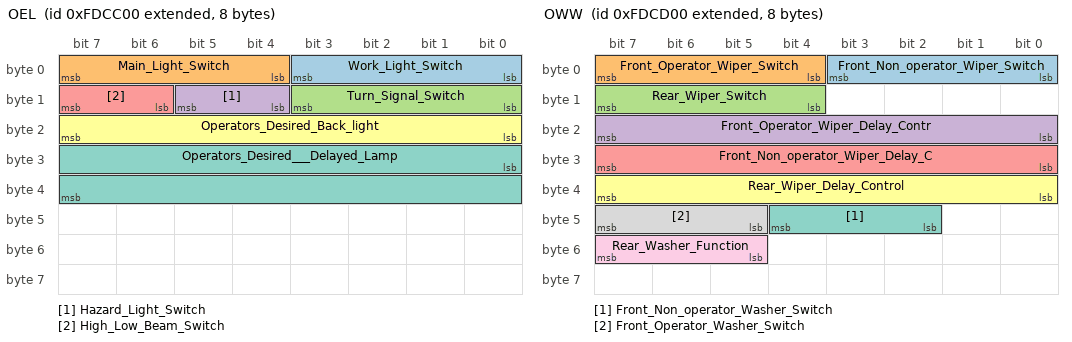
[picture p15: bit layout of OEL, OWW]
BO_ 2164116480 OEL: 8 Vector__XXX
 SG_ Work_Light_Switch : 0|4@1+ (1,0) [0|15] "" Vector__XXX
 SG_ Main_Light_Switch : 4|4@1+ (1,0) [0|15] "" Vector__XXX
 SG_ Turn_Signal_Switch : 8|4@1+ (1,0) [0|15] "" Vector__XXX
 SG_ Hazard_Light_Switch : 12|2@1+ (1,0) [0|3] "" Vector__XXX
 SG_ High_Low_Beam_Switch : 14|2@1+ (1,0) [0|3] "" Vector__XXX
 SG_ Operators_Desired_Back_light : 16|8@1+ (1,0) [0|255] "" Vector__XXX
 SG_ Operators_Desired___Delayed_Lamp : 24|16@1+ (1,0) [0|65535] "" Vector__XXX

BO_ 2164116736 OWW: 8 Vector__XXX
 SG_ Front_Non_operator_Wiper_Switch : 0|4@1+ (1,0) [0|15] "" Vector__XXX
 SG_ Front_Operator_Wiper_Switch : 4|4@1+ (1,0) [0|15] "" Vector__XXX
 SG_ Rear_Wiper_Switch : 12|4@1+ (1,0) [0|15] "" Vector__XXX
 SG_ Front_Operator_Wiper_Delay_Contr : 16|8@1+ (1,0) [0|255] "" Vector__XXX
 SG_ Front_Non_operator_Wiper_Delay_C : 24|8@1+ (1,0) [0|255] "" Vector__XXX
 SG_ Rear_Wiper_Delay_Control : 32|8@1+ (1,0) [0|255] "" Vector__XXX
 SG_ Front_Non_operator_Washer_Switch : 42|3@1+ (1,0) [0|7] "" Vector__XXX
 SG_ Front_Operator_Washer_Switch : 45|3@1+ (1,0) [0|7] "" Vector__XXX
 SG_ Rear_Washer_Function : 53|3@1+ (1,0) [0|7] "" Vector__XXX

BO_ 2164117504 IC2: 8 Vector__XXX
 SG_ Engine_Air_Filter_2_Differential : 0|8@1+ (1,0) [0|255] "" Vector__XXX
 SG_ Engine_Air_Filter_3_Differential : 8|8@1+ (1,0) [0|255] "" Vector__XXX
 SG_ Engine_Air_Filter_4_Differential : 16|8@1+ (1,0) [0|255] "" Vector__XXX
 SG_ Engine_Intake_Manifold__2_Pressu : 24|8@1+ (1,0) [0|255] "" Vector__XXX
 SG_ Engine_Intake_Manifold__1_Absolu : 32|8@1+ (1,0) [0|255] "" Vector__XXX

BO_ 2164117760 FMS: 8 Vector__XXX
 SG_ FMS_standard_Diagnostics_Support : 0|2@1+ (1,0) [0|3] "" Vector__XXX
 SG_ FMS_standard_Requests_Supported : 2|2@1+ (1,0) [0|3] "" Vector__XXX
 SG_ FMS_standard_SW_version_supporte : 8|32@1+ (1,0) [0|4294967295] "" Vector__XXX

BO_ 2164118016 EP: 8 Vector__XXX
 SG_ Keep_Alive_Battery_Consumption : 0|16@1+ (1,0) [0|65535] "" Vector__XXX
 SG_ Data_Memory_Usage : 16|8@1+ (1,0) [0|255] "" Vector__XXX

BO_ 2164118272 TCI6: 8 Vector__XXX
 SG_ Engine_Turbocharger_1_Compressor : 0|16@1+ (1,0) [0|65535] "" Vector__XXX
 SG_ Engine_Turbocharger_2_Compressor : 16|16@1+ (1,0) [0|65535] "" Vector__XXX
 SG_ Engine_Turbocharger_3_Compressor : 32|16@1+ (1,0) [0|65535] "" Vector__XXX
 SG_ Engine_Turbocharger_4_Compressor : 48|16@1+ (1,0) [0|65535] "" Vector__XXX

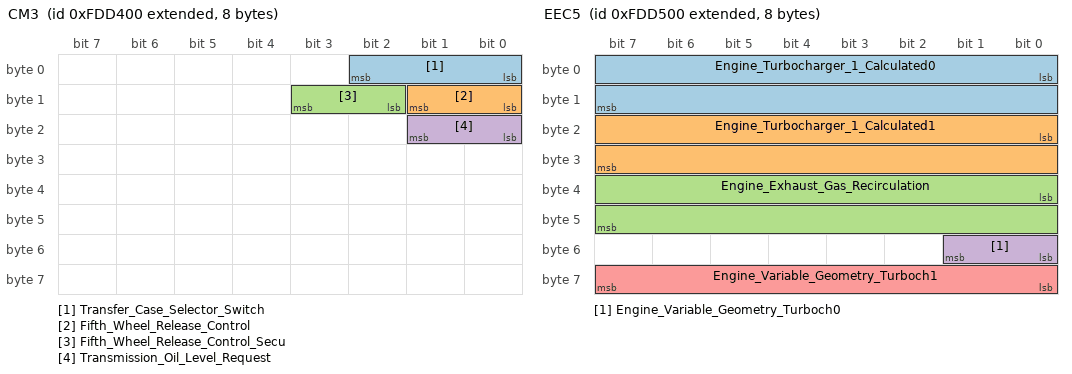
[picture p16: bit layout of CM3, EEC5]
BO_ 2164118528 CM3: 8 Vector__XXX
 SG_ Transfer_Case_Selector_Switch : 0|3@1+ (1,0) [0|7] "" Vector__XXX
 SG_ Fifth_Wheel_Release_Control : 8|2@1+ (1,0) [0|3] "" Vector__XXX
 SG_ Fifth_Wheel_Release_Control_Secu : 10|2@1+ (1,0) [0|3] "" Vector__XXX
 SG_ Transmission_Oil_Level_Request : 16|2@1+ (1,0) [0|3] "" Vector__XXX

BO_ 2164118784 EEC5: 8 Vector__XXX
 SG_ Engine_Turbocharger_1_Calculated0 : 0|16@1+ (1,0) [0|65535] "" Vector__XXX
 SG_ Engine_Turbocharger_1_Calculated1 : 16|16@1+ (1,0) [0|65535] "" Vector__XXX
 SG_ Engine_Exhaust_Gas_Recirculation : 32|16@1+ (1,0) [0|65535] "" Vector__XXX
 SG_ Engine_Variable_Geometry_Turboch0 : 48|2@1+ (1,0) [0|3] "" Vector__XXX
 SG_ Engine_Variable_Geometry_Turboch1 : 56|8@1+ (1,0) [0|255] "" Vector__XXX

BO_ 2164119040 BJM1: 8 Vector__XXX
 SG_ Joystick_1_X_Axis_Neutral_Positi : 0|2@1+ (1,0) [0|3] "" Vector__XXX
 SG_ Joystick_1_X_Axis_Lever_Left_Neg : 2|2@1+ (1,0) [0|3] "" Vector__XXX
 SG_ Joystick_1_X_Axis_Lever_Right_Po : 4|2@1+ (1,0) [0|3] "" Vector__XXX
 SG_ Joystick_1_X_Axis_Position : 6|10@1+ (1,0) [0|1023] "" Vector__XXX
 SG_ Joystick_1_Y_Axis_Neutral_Positi : 16|2@1+ (1,0) [0|3] "" Vector__XXX
 SG_ Joystick_1_Y_Axis_Lever_Back_Neg : 18|2@1+ (1,0) [0|3] "" Vector__XXX
 SG_ Joystick_1_Y_Axis_Lever_Forward_ : 20|2@1+ (1,0) [0|3] "" Vector__XXX
 SG_ Joystick_1_Y_Axis_Position : 22|10@1+ (1,0) [0|1023] "" Vector__XXX
 SG_ Joystick_1_Y_Axis_Detent_Positio : 36|2@1+ (1,0) [0|3] "" Vector__XXX
 SG_ Joystick_1_X_Axis_Detent_Positio : 38|2@1+ (1,0) [0|3] "" Vector__XXX
 SG_ Joystick_1_Button_4_Pressed_Stat : 40|2@1+ (1,0) [0|3] "" Vector__XXX
 SG_ Joystick_1_Button_3_Pressed_Stat : 42|2@1+ (1,0) [0|3] "" Vector__XXX
 SG_ Joystick_1_Button_2_Pressed_Stat : 44|2@1+ (1,0) [0|3] "" Vector__XXX
 SG_ Joystick_1_Button_1_Pressed_Stat : 46|2@1+ (1,0) [0|3] "" Vector__XXX
 SG_ Joystick_1_Button_8_Pressed_Stat : 48|2@1+ (1,0) [0|3] "" Vector__XXX
 SG_ Joystick_1_Button_7_Pressed_Stat : 50|2@1+ (1,0) [0|3] "" Vector__XXX
 SG_ Joystick_1_Button_6_Pressed_Stat : 52|2@1+ (1,0) [0|3] "" Vector__XXX
 SG_ Joystick_1_Button_5_Pressed_Stat : 54|2@1+ (1,0) [0|3] "" Vector__XXX
 SG_ Joystick_1_Button_12_Pressed_Sta : 56|2@1+ (1,0) [0|3] "" Vector__XXX
 SG_ Joystick_1_Button_11_Pressed_Sta : 58|2@1+ (1,0) [0|3] "" Vector__XXX
 SG_ Joystick_1_Button_10_Pressed_Sta : 60|2@1+ (1,0) [0|3] "" Vector__XXX
 SG_ Joystick_1_Button_9_Pressed_Stat : 62|2@1+ (1,0) [0|3] "" Vector__XXX

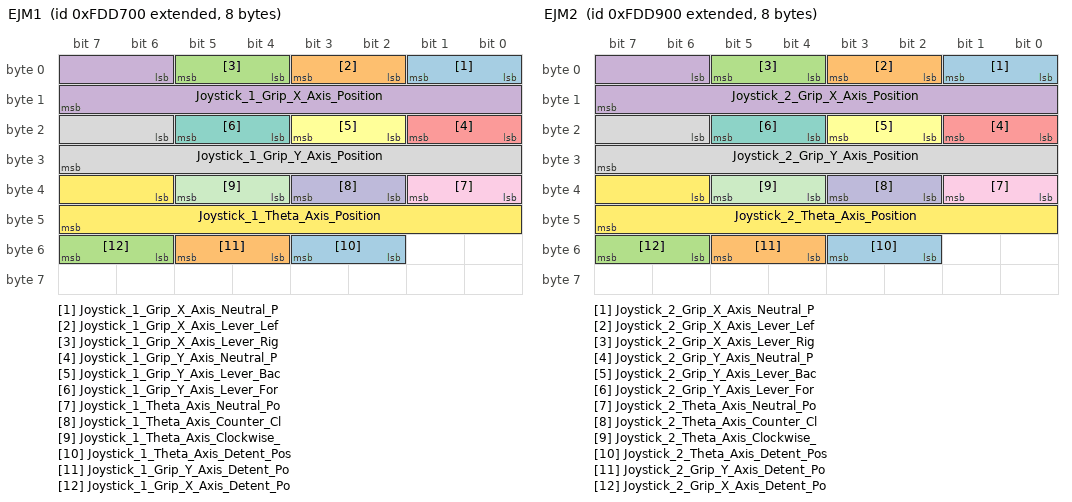
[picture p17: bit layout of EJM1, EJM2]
BO_ 2164119296 EJM1: 8 Vector__XXX
 SG_ Joystick_1_Grip_X_Axis_Neutral_P : 0|2@1+ (1,0) [0|3] "" Vector__XXX
 SG_ Joystick_1_Grip_X_Axis_Lever_Lef : 2|2@1+ (1,0) [0|3] "" Vector__XXX
 SG_ Joystick_1_Grip_X_Axis_Lever_Rig : 4|2@1+ (1,0) [0|3] "" Vector__XXX
 SG_ Joystick_1_Grip_X_Axis_Position : 6|10@1+ (1,0) [0|1023] "" Vector__XXX
 SG_ Joystick_1_Grip_Y_Axis_Neutral_P : 16|2@1+ (1,0) [0|3] "" Vector__XXX
 SG_ Joystick_1_Grip_Y_Axis_Lever_Bac : 18|2@1+ (1,0) [0|3] "" Vector__XXX
 SG_ Joystick_1_Grip_Y_Axis_Lever_For : 20|2@1+ (1,0) [0|3] "" Vector__XXX
 SG_ Joystick_1_Grip_Y_Axis_Position : 22|10@1+ (1,0) [0|1023] "" Vector__XXX
 SG_ Joystick_1_Theta_Axis_Neutral_Po : 32|2@1+ (1,0) [0|3] "" Vector__XXX
 SG_ Joystick_1_Theta_Axis_Counter_Cl : 34|2@1+ (1,0) [0|3] "" Vector__XXX
 SG_ Joystick_1_Theta_Axis_Clockwise_ : 36|2@1+ (1,0) [0|3] "" Vector__XXX
 SG_ Joystick_1_Theta_Axis_Position : 38|10@1+ (1,0) [0|1023] "" Vector__XXX
 SG_ Joystick_1_Theta_Axis_Detent_Pos : 50|2@1+ (1,0) [0|3] "" Vector__XXX
 SG_ Joystick_1_Grip_Y_Axis_Detent_Po : 52|2@1+ (1,0) [0|3] "" Vector__XXX
 SG_ Joystick_1_Grip_X_Axis_Detent_Po : 54|2@1+ (1,0) [0|3] "" Vector__XXX

BO_ 2164119552 BJM2: 8 Vector__XXX
 SG_ Joystick_2_X_Axis_Neutral_Positi : 0|2@1+ (1,0) [0|3] "" Vector__XXX
 SG_ Joystick_2_X_Axis_Lever_Left_Neg : 2|2@1+ (1,0) [0|3] "" Vector__XXX
 SG_ Joystick_2_X_Axis_Lever_Right_Po : 4|2@1+ (1,0) [0|3] "" Vector__XXX
 SG_ Joystick_2_X_Axis_Position : 6|10@1+ (1,0) [0|1023] "" Vector__XXX
 SG_ Joystick_2_Y_Axis_Neutral_Positi : 16|2@1+ (1,0) [0|3] "" Vector__XXX
 SG_ Joystick_2_Y_Axis_Lever_Back_Neg : 18|2@1+ (1,0) [0|3] "" Vector__XXX
 SG_ Joystick_2_Y_Axis_Lever_Forward_ : 20|2@1+ (1,0) [0|3] "" Vector__XXX
 SG_ Joystick_2_Y_Axis_Position : 22|10@1+ (1,0) [0|1023] "" Vector__XXX
 SG_ Joystick_2_Y_Axis_Detent_Positio : 36|2@1+ (1,0) [0|3] "" Vector__XXX
 SG_ Joystick_2_X_Axis_Detent_Positio : 38|2@1+ (1,0) [0|3] "" Vector__XXX
 SG_ Joystick_2_Button_4_Pressed_Stat : 40|2@1+ (1,0) [0|3] "" Vector__XXX
 SG_ Joystick_2_Button_3_Pressed_Stat : 42|2@1+ (1,0) [0|3] "" Vector__XXX
 SG_ Joystick_2_Button_2_Pressed_Stat : 44|2@1+ (1,0) [0|3] "" Vector__XXX
 SG_ Joystick_2_Button_1_Pressed_Stat : 46|2@1+ (1,0) [0|3] "" Vector__XXX
 SG_ Joystick_2_Button_8_Pressed_Stat : 48|2@1+ (1,0) [0|3] "" Vector__XXX
 SG_ Joystick_2_Button_7_Pressed_Stat : 50|2@1+ (1,0) [0|3] "" Vector__XXX
 SG_ Joystick_2_Button_6_Pressed_Stat : 52|2@1+ (1,0) [0|3] "" Vector__XXX
 SG_ Joystick_2_Button_5_Pressed_Stat : 54|2@1+ (1,0) [0|3] "" Vector__XXX
 SG_ Joystick_2_Button_12_Pressed_Sta : 56|2@1+ (1,0) [0|3] "" Vector__XXX
 SG_ Joystick_2_Button_11_Pressed_Sta : 58|2@1+ (1,0) [0|3] "" Vector__XXX
 SG_ Joystick_2_Button_10_Pressed_Sta : 60|2@1+ (1,0) [0|3] "" Vector__XXX
 SG_ Joystick_2_Button_9_Pressed_Stat : 62|2@1+ (1,0) [0|3] "" Vector__XXX

BO_ 2164119808 EJM2: 8 Vector__XXX
 SG_ Joystick_2_Grip_X_Axis_Neutral_P : 0|2@1+ (1,0) [0|3] "" Vector__XXX
 SG_ Joystick_2_Grip_X_Axis_Lever_Lef : 2|2@1+ (1,0) [0|3] "" Vector__XXX
 SG_ Joystick_2_Grip_X_Axis_Lever_Rig : 4|2@1+ (1,0) [0|3] "" Vector__XXX
 SG_ Joystick_2_Grip_X_Axis_Position : 6|10@1+ (1,0) [0|1023] "" Vector__XXX
 SG_ Joystick_2_Grip_Y_Axis_Neutral_P : 16|2@1+ (1,0) [0|3] "" Vector__XXX
 SG_ Joystick_2_Grip_Y_Axis_Lever_Bac : 18|2@1+ (1,0) [0|3] "" Vector__XXX
 SG_ Joystick_2_Grip_Y_Axis_Lever_For : 20|2@1+ (1,0) [0|3] "" Vector__XXX
 SG_ Joystick_2_Grip_Y_Axis_Position : 22|10@1+ (1,0) [0|1023] "" Vector__XXX
 SG_ Joystick_2_Theta_Axis_Neutral_Po : 32|2@1+ (1,0) [0|3] "" Vector__XXX
 SG_ Joystick_2_Theta_Axis_Counter_Cl : 34|2@1+ (1,0) [0|3] "" Vector__XXX
 SG_ Joystick_2_Theta_Axis_Clockwise_ : 36|2@1+ (1,0) [0|3] "" Vector__XXX
 SG_ Joystick_2_Theta_Axis_Position : 38|10@1+ (1,0) [0|1023] "" Vector__XXX
 SG_ Joystick_2_Theta_Axis_Detent_Pos : 50|2@1+ (1,0) [0|3] "" Vector__XXX
 SG_ Joystick_2_Grip_Y_Axis_Detent_Po : 52|2@1+ (1,0) [0|3] "" Vector__XXX
 SG_ Joystick_2_Grip_X_Axis_Detent_Po : 54|2@1+ (1,0) [0|3] "" Vector__XXX

BO_ 2164120064 BJM3: 8 Vector__XXX
 SG_ Joystick_3_X_Axis_Neutral_Positi : 0|2@1+ (1,0) [0|3] "" Vector__XXX
 SG_ Joystick_3_X_Axis_Lever_Left_Neg : 2|2@1+ (1,0) [0|3] "" Vector__XXX
 SG_ Joystick_3_X_Axis_Lever_Right_Po : 4|2@1+ (1,0) [0|3] "" Vector__XXX
 SG_ Joystick_3_X_Axis_Position : 6|10@1+ (1,0) [0|1023] "" Vector__XXX
 SG_ Joystick_3_Y_Axis_Neutral_Positi : 16|2@1+ (1,0) [0|3] "" Vector__XXX
 SG_ Joystick_3_Y_Axis_Lever_Back_Neg : 18|2@1+ (1,0) [0|3] "" Vector__XXX
 SG_ Joystick_3_Y_Axis_Lever_Forward_ : 20|2@1+ (1,0) [0|3] "" Vector__XXX
 SG_ Joystick_3_Y_Axis_Position : 22|10@1+ (1,0) [0|1023] "" Vector__XXX
 SG_ Joystick_3_Y_Axis_Detent_Positio : 36|2@1+ (1,0) [0|3] "" Vector__XXX
 SG_ Joystick_3_X_Axis_Detent_Positio : 38|2@1+ (1,0) [0|3] "" Vector__XXX
 SG_ Joystick_3_Button_4_Pressed_Stat : 40|2@1+ (1,0) [0|3] "" Vector__XXX
 SG_ Joystick_3_Button_3_Pressed_Stat : 42|2@1+ (1,0) [0|3] "" Vector__XXX
 SG_ Joystick_3_Button_2_Pressed_Stat : 44|2@1+ (1,0) [0|3] "" Vector__XXX
 SG_ Joystick_3_Button_1_Pressed_Stat : 46|2@1+ (1,0) [0|3] "" Vector__XXX
 SG_ Joystick_3_Button_8_Pressed_Stat : 48|2@1+ (1,0) [0|3] "" Vector__XXX
 SG_ Joystick_3_Button_7_Pressed_Stat : 50|2@1+ (1,0) [0|3] "" Vector__XXX
 SG_ Joystick_3_Button_6_Pressed_Stat : 52|2@1+ (1,0) [0|3] "" Vector__XXX
 SG_ Joystick_3_Button_5_Pressed_Stat : 54|2@1+ (1,0) [0|3] "" Vector__XXX
 SG_ Joystick_3_Button_12_Pressed_Sta : 56|2@1+ (1,0) [0|3] "" Vector__XXX
 SG_ Joystick_3_Button_11_Pressed_Sta : 58|2@1+ (1,0) [0|3] "" Vector__XXX
 SG_ Joystick_3_Button_10_Pressed_Sta : 60|2@1+ (1,0) [0|3] "" Vector__XXX
 SG_ Joystick_3_Button_9_Pressed_Stat : 62|2@1+ (1,0) [0|3] "" Vector__XXX

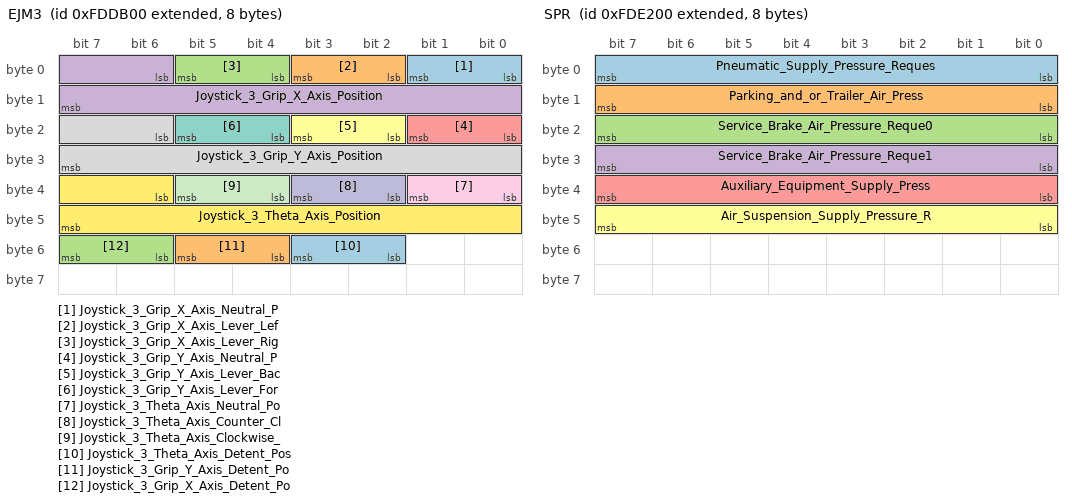
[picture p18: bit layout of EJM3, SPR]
BO_ 2164120320 EJM3: 8 Vector__XXX
 SG_ Joystick_3_Grip_X_Axis_Neutral_P : 0|2@1+ (1,0) [0|3] "" Vector__XXX
 SG_ Joystick_3_Grip_X_Axis_Lever_Lef : 2|2@1+ (1,0) [0|3] "" Vector__XXX
 SG_ Joystick_3_Grip_X_Axis_Lever_Rig : 4|2@1+ (1,0) [0|3] "" Vector__XXX
 SG_ Joystick_3_Grip_X_Axis_Position : 6|10@1+ (1,0) [0|1023] "" Vector__XXX
 SG_ Joystick_3_Grip_Y_Axis_Neutral_P : 16|2@1+ (1,0) [0|3] "" Vector__XXX
 SG_ Joystick_3_Grip_Y_Axis_Lever_Bac : 18|2@1+ (1,0) [0|3] "" Vector__XXX
 SG_ Joystick_3_Grip_Y_Axis_Lever_For : 20|2@1+ (1,0) [0|3] "" Vector__XXX
 SG_ Joystick_3_Grip_Y_Axis_Position : 22|10@1+ (1,0) [0|1023] "" Vector__XXX
 SG_ Joystick_3_Theta_Axis_Neutral_Po : 32|2@1+ (1,0) [0|3] "" Vector__XXX
 SG_ Joystick_3_Theta_Axis_Counter_Cl : 34|2@1+ (1,0) [0|3] "" Vector__XXX
 SG_ Joystick_3_Theta_Axis_Clockwise_ : 36|2@1+ (1,0) [0|3] "" Vector__XXX
 SG_ Joystick_3_Theta_Axis_Position : 38|10@1+ (1,0) [0|1023] "" Vector__XXX
 SG_ Joystick_3_Theta_Axis_Detent_Pos : 50|2@1+ (1,0) [0|3] "" Vector__XXX
 SG_ Joystick_3_Grip_Y_Axis_Detent_Po : 52|2@1+ (1,0) [0|3] "" Vector__XXX
 SG_ Joystick_3_Grip_X_Axis_Detent_Po : 54|2@1+ (1,0) [0|3] "" Vector__XXX

BO_ 2164120576 MCI: 8 Vector__XXX
 SG_ Engine_Throttle_Synchronization_ : 0|4@1+ (1,0) [0|15] "" Vector__XXX
 SG_ Trolling_Mode_Status : 4|2@1+ (1,0) [0|3] "" Vector__XXX
 SG_ Slow_Vessel_Mode_Status : 6|2@1+ (1,0) [0|3] "" Vector__XXX

BO_ 2164121344 FWD: 8 Vector__XXX
 SG_ Front_Wheel_Drive_Actuator_Statu : 0|2@1+ (1,0) [0|3] "" Vector__XXX

BO_ 2164121600 AMB2: 8 Vector__XXX
 SG_ Solar_Intensity_Percent : 0|8@1+ (1,0) [0|255] "" Vector__XXX
 SG_ Solar_Sensor_Maximum : 8|8@1+ (1,0) [0|255] "" Vector__XXX
 SG_ Specific_Humidity : 16|16@1+ (1,0) [0|65535] "" Vector__XXX

BO_ 2164121856 CACI: 8 Vector__XXX
 SG_ Cab_A_C_Refrigerant_Compressor_O : 0|8@1+ (1,0) [0|255] "" Vector__XXX

BO_ 2164122112 SPR: 8 Vector__XXX
 SG_ Pneumatic_Supply_Pressure_Reques : 0|8@1+ (1,0) [0|255] "" Vector__XXX
 SG_ Parking_and_or_Trailer_Air_Press : 8|8@1+ (1,0) [0|255] "" Vector__XXX
 SG_ Service_Brake_Air_Pressure_Reque0 : 16|8@1+ (1,0) [0|255] "" Vector__XXX
 SG_ Service_Brake_Air_Pressure_Reque1 : 24|8@1+ (1,0) [0|255] "" Vector__XXX
 SG_ Auxiliary_Equipment_Supply_Press : 32|8@1+ (1,0) [0|255] "" Vector__XXX
 SG_ Air_Suspension_Supply_Pressure_R : 40|8@1+ (1,0) [0|255] "" Vector__XXX

BO_ 2164122368 EOAC: 8 Vector__XXX
 SG_ Travel_Velocity_Control_Position : 0|8@1+ (1,0) [0|255] "" Vector__XXX

BO_ 2164122624 EPD: 8 Vector__XXX
 SG_ Payload_Percentage : 0|8@1+ (1,0) [0|255] "" Vector__XXX

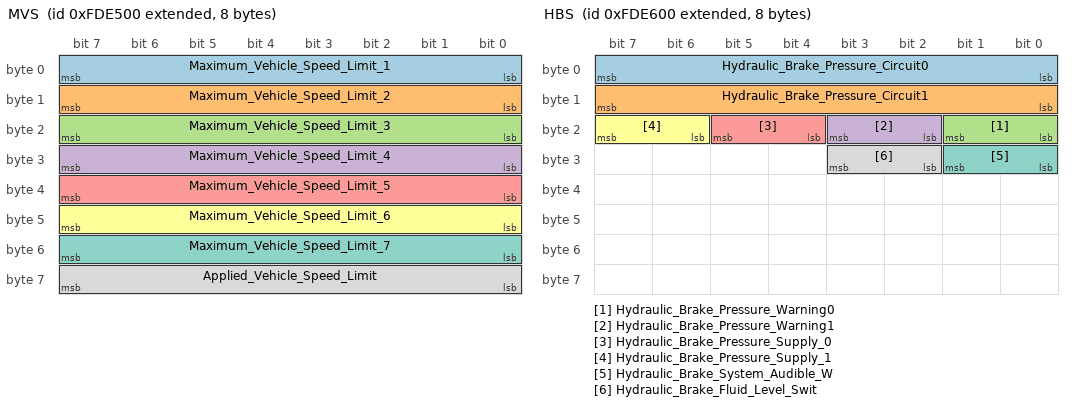
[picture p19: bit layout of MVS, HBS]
BO_ 2164122880 MVS: 8 Vector__XXX
 SG_ Maximum_Vehicle_Speed_Limit_1 : 0|8@1+ (1,0) [0|255] "" Vector__XXX
 SG_ Maximum_Vehicle_Speed_Limit_2 : 8|8@1+ (1,0) [0|255] "" Vector__XXX
 SG_ Maximum_Vehicle_Speed_Limit_3 : 16|8@1+ (1,0) [0|255] "" Vector__XXX
 SG_ Maximum_Vehicle_Speed_Limit_4 : 24|8@1+ (1,0) [0|255] "" Vector__XXX
 SG_ Maximum_Vehicle_Speed_Limit_5 : 32|8@1+ (1,0) [0|255] "" Vector__XXX
 SG_ Maximum_Vehicle_Speed_Limit_6 : 40|8@1+ (1,0) [0|255] "" Vector__XXX
 SG_ Maximum_Vehicle_Speed_Limit_7 : 48|8@1+ (1,0) [0|255] "" Vector__XXX
 SG_ Applied_Vehicle_Speed_Limit : 56|8@1+ (1,0) [0|255] "" Vector__XXX

BO_ 2164123136 HBS: 8 Vector__XXX
 SG_ Hydraulic_Brake_Pressure_Circuit0 : 0|8@1+ (1,0) [0|255] "" Vector__XXX
 SG_ Hydraulic_Brake_Pressure_Circuit1 : 8|8@1+ (1,0) [0|255] "" Vector__XXX
 SG_ Hydraulic_Brake_Pressure_Warning0 : 16|2@1+ (1,0) [0|3] "" Vector__XXX
 SG_ Hydraulic_Brake_Pressure_Warning1 : 18|2@1+ (1,0) [0|3] "" Vector__XXX
 SG_ Hydraulic_Brake_Pressure_Supply_0 : 20|2@1+ (1,0) [0|3] "" Vector__XXX
 SG_ Hydraulic_Brake_Pressure_Supply_1 : 22|2@1+ (1,0) [0|3] "" Vector__XXX
 SG_ Hydraulic_Brake_System_Audible_W : 24|2@1+ (1,0) [0|3] "" Vector__XXX
 SG_ Hydraulic_Brake_Fluid_Level_Swit : 26|2@1+ (1,0) [0|3] "" Vector__XXX

BO_ 2164131584 ET: 8 Vector__XXX
 SG_ Engine_Exhaust_Gas_Temperature__ : 0|16@1+ (1,0) [0|65535] "" Vector__XXX
 SG_ Engine_Exhaust_Gas_Temperature__ : 16|16@1+ (1,0) [0|65535] "" Vector__XXX

BO_ 2164146176 LD: 8 Vector__XXX
 SG_ Running_Light : 0|2@1+ (1,0) [0|3] "" Vector__XXX
 SG_ Alternate_Beam_Head_Light_Data : 2|2@1+ (1,0) [0|3] "" Vector__XXX
 SG_ Low_Beam_Head_Light_Data : 4|2@1+ (1,0) [0|3] "" Vector__XXX
 SG_ High_Beam_Head_Light_Data : 6|2@1+ (1,0) [0|3] "" Vector__XXX
 SG_ Tractor_Front_Fog_Lights : 8|2@1+ (1,0) [0|3] "" Vector__XXX
 SG_ Rotating_Beacon_Light : 10|2@1+ (1,0) [0|3] "" Vector__XXX
 SG_ Right_Turn_Signal_Lights : 12|2@1+ (1,0) [0|3] "" Vector__XXX
 SG_ Left_Turn_Signal_Lights : 14|2@1+ (1,0) [0|3] "" Vector__XXX
 SG_ Back_Up_Light_and_Alarm_Horn : 16|2@1+ (1,0) [0|3] "" Vector__XXX
 SG_ Center_Stop_Light : 18|2@1+ (1,0) [0|3] "" Vector__XXX
 SG_ Right_Stop_Light : 20|2@1+ (1,0) [0|3] "" Vector__XXX
 SG_ Left_Stop_Light : 22|2@1+ (1,0) [0|3] "" Vector__XXX
 SG_ Implement_Clearance_Light : 24|2@1+ (1,0) [0|3] "" Vector__XXX
 SG_ Tractor_Clearance_Light : 26|2@1+ (1,0) [0|3] "" Vector__XXX
 SG_ Implement_Marker_Light : 28|2@1+ (1,0) [0|3] "" Vector__XXX
 SG_ Tractor_Marker_Light : 30|2@1+ (1,0) [0|3] "" Vector__XXX
 SG_ Rear_Fog_Lights : 32|2@1+ (1,0) [0|3] "" Vector__XXX
 SG_ Tractor_Underside_Mounted_Work_L : 34|2@1+ (1,0) [0|3] "" Vector__XXX
 SG_ Tractor_Rear_Low_Mounted_Work_Li : 36|2@1+ (1,0) [0|3] "" Vector__XXX
 SG_ Tractor_Rear_High_Mounted_Work_L : 38|2@1+ (1,0) [0|3] "" Vector__XXX
 SG_ Tractor_Side_Low_Mounted_Work_Li : 40|2@1+ (1,0) [0|3] "" Vector__XXX
 SG_ Tractor_Side_High_Mounted_Work_L : 42|2@1+ (1,0) [0|3] "" Vector__XXX
 SG_ Tractor_Front_Low_Mounted_Work_L : 44|2@1+ (1,0) [0|3] "" Vector__XXX
 SG_ Tractor_Front_High_Mounted_Work_ : 46|2@1+ (1,0) [0|3] "" Vector__XXX
 SG_ Implement_OEM_Option_2_Light : 48|2@1+ (1,0) [0|3] "" Vector__XXX
 SG_ Implement_OEM_Option_1_Light : 50|2@1+ (1,0) [0|3] "" Vector__XXX
 SG_ Implement_Right_Facing_Work_Ligh : 52|2@1+ (1,0) [0|3] "" Vector__XXX
 SG_ Implement_Left_Facing_Work_Light : 54|2@1+ (1,0) [0|3] "" Vector__XXX
 SG_ Implement_Right_Forward_Work_Lig : 58|2@1+ (1,0) [0|3] "" Vector__XXX
 SG_ Implement_Left_Forward_Work_Ligh : 60|2@1+ (1,0) [0|3] "" Vector__XXX
 SG_ Implement_Rear_Work_Light : 62|2@1+ (1,0) [0|3] "" Vector__XXX

BA_DEF_ BO_ "VFrameFormat" ENUM "StandardCAN","ExtendedCAN","StandardCAN_FD","ExtendedCAN_FD","J1939PG";
BA_DEF_ SG_ "SPN" INT 0 524287;
BA_DEF_ SG_ "SystemSignalLongSymbol" STRING;
BA_ "VFrameFormat" BO_ 2164079360 4;
BA_ "VFrameFormat" BO_ 2164079616 4;
BA_ "VFrameFormat" BO_ 2164079872 4;
BA_ "VFrameFormat" BO_ 2164080128 4;
BA_ "VFrameFormat" BO_ 2164080384 4;
BA_ "VFrameFormat" BO_ 2164080640 4;
BA_ "VFrameFormat" BO_ 2164080896 4;
BA_ "VFrameFormat" BO_ 2164081664 4;
BA_ "VFrameFormat" BO_ 2164081920 4;
BA_ "VFrameFormat" BO_ 2164082176 4;
BA_ "VFrameFormat" BO_ 2164082432 4;
BA_ "VFrameFormat" BO_ 2164082688 4;
BA_ "VFrameFormat" BO_ 2164082944 4;
BA_ "VFrameFormat" BO_ 2164084992 4;
BA_ "VFrameFormat" BO_ 2164085248 4;
BA_ "VFrameFormat" BO_ 2164085504 4;
BA_ "VFrameFormat" BO_ 2164090112 4;
BA_ "VFrameFormat" BO_ 2164090368 4;
BA_ "VFrameFormat" BO_ 2164090624 4;
BA_ "VFrameFormat" BO_ 2164090880 4;
BA_ "VFrameFormat" BO_ 2164091136 4;
BA_ "VFrameFormat" BO_ 2164091392 4;
BA_ "VFrameFormat" BO_ 2164091648 4;
BA_ "VFrameFormat" BO_ 2164091904 4;
BA_ "VFrameFormat" BO_ 2164092160 4;
BA_ "VFrameFormat" BO_ 2164092416 4;
BA_ "VFrameFormat" BO_ 2164092672 4;
BA_ "VFrameFormat" BO_ 2164092928 4;
BA_ "VFrameFormat" BO_ 2164093184 4;
BA_ "VFrameFormat" BO_ 2164093440 4;
BA_ "VFrameFormat" BO_ 2164093696 4;
BA_ "VFrameFormat" BO_ 2164093952 4;
BA_ "VFrameFormat" BO_ 2164094208 4;
BA_ "VFrameFormat" BO_ 2164094464 4;
BA_ "VFrameFormat" BO_ 2164094720 4;
BA_ "VFrameFormat" BO_ 2164094976 4;
BA_ "VFrameFormat" BO_ 2164095232 4;
BA_ "VFrameFormat" BO_ 2164095488 4;
BA_ "VFrameFormat" BO_ 2164095744 4;
BA_ "VFrameFormat" BO_ 2164096000 4;
BA_ "VFrameFormat" BO_ 2164096512 4;
BA_ "VFrameFormat" BO_ 2164096768 4;
BA_ "VFrameFormat" BO_ 2164097280 4;
BA_ "VFrameFormat" BO_ 2164097792 4;
BA_ "VFrameFormat" BO_ 2164098048 4;
BA_ "VFrameFormat" BO_ 2164098304 4;
BA_ "VFrameFormat" BO_ 2164098560 4;
BA_ "VFrameFormat" BO_ 2164098816 4;
BA_ "VFrameFormat" BO_ 2164099072 4;
BA_ "VFrameFormat" BO_ 2164099328 4;
BA_ "VFrameFormat" BO_ 2164099584 4;
BA_ "VFrameFormat" BO_ 2164099840 4;
BA_ "VFrameFormat" BO_ 2164100096 4;
BA_ "VFrameFormat" BO_ 2164101120 4;
BA_ "VFrameFormat" BO_ 2164101632 4;
BA_ "VFrameFormat" BO_ 2164102144 4;
BA_ "VFrameFormat" BO_ 2164102400 4;
BA_ "VFrameFormat" BO_ 2164103168 4;
BA_ "VFrameFormat" BO_ 2164103424 4;
BA_ "VFrameFormat" BO_ 2164103936 4;
BA_ "VFrameFormat" BO_ 2164104192 4;
BA_ "VFrameFormat" BO_ 2164104448 4;
BA_ "VFrameFormat" BO_ 2164104704 4;
BA_ "VFrameFormat" BO_ 2164104960 4;
BA_ "VFrameFormat" BO_ 2164105216 4;
BA_ "VFrameFormat" BO_ 2164105472 4;
BA_ "VFrameFormat" BO_ 2164105728 4;
BA_ "VFrameFormat" BO_ 2164105984 4;
BA_ "VFrameFormat" BO_ 2164106240 4;
BA_ "VFrameFormat" BO_ 2164106496 4;
BA_ "VFrameFormat" BO_ 2164107264 4;
BA_ "VFrameFormat" BO_ 2164107520 4;
BA_ "VFrameFormat" BO_ 2164107776 4;
BA_ "VFrameFormat" BO_ 2164108800 4;
BA_ "VFrameFormat" BO_ 2164109056 4;
BA_ "VFrameFormat" BO_ 2164109312 4;
BA_ "VFrameFormat" BO_ 2164109568 4;
BA_ "VFrameFormat" BO_ 2164109824 4;
BA_ "VFrameFormat" BO_ 2164110080 4;
BA_ "VFrameFormat" BO_ 2164110336 4;
BA_ "VFrameFormat" BO_ 2164111616 4;
BA_ "VFrameFormat" BO_ 2164111872 4;
BA_ "VFrameFormat" BO_ 2164112128 4;
BA_ "VFrameFormat" BO_ 2164112384 4;
BA_ "VFrameFormat" BO_ 2164112640 4;
BA_ "VFrameFormat" BO_ 2164112896 4;
BA_ "VFrameFormat" BO_ 2164113152 4;
BA_ "VFrameFormat" BO_ 2164113408 4;
BA_ "VFrameFormat" BO_ 2164113664 4;
BA_ "VFrameFormat" BO_ 2164114432 4;
BA_ "VFrameFormat" BO_ 2164114688 4;
BA_ "VFrameFormat" BO_ 2164114944 4;
BA_ "VFrameFormat" BO_ 2164115200 4;
BA_ "VFrameFormat" BO_ 2164115456 4;
BA_ "VFrameFormat" BO_ 2164115712 4;
BA_ "VFrameFormat" BO_ 2164115968 4;
BA_ "VFrameFormat" BO_ 2164116224 4;
BA_ "VFrameFormat" BO_ 2164116480 4;
BA_ "VFrameFormat" BO_ 2164116736 4;
BA_ "VFrameFormat" BO_ 2164117504 4;
BA_ "VFrameFormat" BO_ 2164117760 4;
BA_ "VFrameFormat" BO_ 2164118016 4;
BA_ "VFrameFormat" BO_ 2164118272 4;
BA_ "VFrameFormat" BO_ 2164118528 4;
BA_ "VFrameFormat" BO_ 2164118784 4;
BA_ "VFrameFormat" BO_ 2164119040 4;
BA_ "VFrameFormat" BO_ 2164119296 4;
BA_ "VFrameFormat" BO_ 2164119552 4;
BA_ "VFrameFormat" BO_ 2164119808 4;
BA_ "VFrameFormat" BO_ 2164120064 4;
BA_ "VFrameFormat" BO_ 2164120320 4;
BA_ "VFrameFormat" BO_ 2164120576 4;
BA_ "VFrameFormat" BO_ 2164121344 4;
BA_ "VFrameFormat" BO_ 2164121600 4;
BA_ "VFrameFormat" BO_ 2164121856 4;
BA_ "VFrameFormat" BO_ 2164122112 4;
BA_ "VFrameFormat" BO_ 2164122368 4;
BA_ "VFrameFormat" BO_ 2164122624 4;
BA_ "VFrameFormat" BO_ 2164122880 4;
BA_ "VFrameFormat" BO_ 2164123136 4;
BA_ "VFrameFormat" BO_ 2164131584 4;
BA_ "VFrameFormat" BO_ 2164146176 4;
BA_ "SPN" SG_ 2164079360 Aftertreatment_2_SCR_Dosing_Air_0 4388;
BA_ "SystemSignalLongSymbol" SG_ 2164079360 Aftertreatment_2_SCR_Dosing_Air_0 "Aftertreatment 2 SCR Dosing Air Assist Absolute Pressure";
BA_ "SPN" SG_ 2164079360 Aftertreatment_2_SCR_Dosing_Air_1 4389;
BA_ "SystemSignalLongSymbol" SG_ 2164079360 Aftertreatment_2_SCR_Dosing_Air_1 "Aftertreatment 2 SCR Dosing Air Assist Valve (measured, 0 = closed)";
BA_ "SPN" SG_ 2164079360 Aftertreatment_2_SCR_Dosing_Reag 4390;
BA_ "SystemSignalLongSymbol" SG_ 2164079360 Aftertreatment_2_SCR_Dosing_Reag "Aftertreatment 2 SCR Dosing Reagent Temperature (closest to dosing valve)";
BA_ "SPN" SG_ 2164079360 Aftertreatment_2_SCR_Dosing_Valv 4391;
BA_ "SystemSignalLongSymbol" SG_ 2164079360 Aftertreatment_2_SCR_Dosing_Valv "Aftertreatment 2 SCR Dosing Valve Exhaust Temp. Reduction Request";
BA_ "SPN" SG_ 2164079360 Aftertreatment_2_SCR_Feedback_Co 4392;
BA_ "SystemSignalLongSymbol" SG_ 2164079360 Aftertreatment_2_SCR_Feedback_Co "Aftertreatment 2 SCR Feedback Control Status (Open/Closed Loop)";
BA_ "SPN" SG_ 2164079360 Aftertreatment_2_SCR_Catalyst_Re0 4393;
BA_ "SystemSignalLongSymbol" SG_ 2164079360 Aftertreatment_2_SCR_Catalyst_Re0 "Aftertreatment 2 SCR Catalyst Reagent Line Heater 1 state";
BA_ "SPN" SG_ 2164079360 Aftertreatment_2_SCR_Catalyst_Re1 4394;
BA_ "SystemSignalLongSymbol" SG_ 2164079360 Aftertreatment_2_SCR_Catalyst_Re1 "Aftertreatment 2 SCR Catalyst Reagent Line Heater 1 Preliminary FMI";
BA_ "SPN" SG_ 2164079360 Aftertreatment_2_SCR_Catalyst_Re2 4395;
BA_ "SystemSignalLongSymbol" SG_ 2164079360 Aftertreatment_2_SCR_Catalyst_Re2 "Aftertreatment 2 SCR Catalyst Reagent Line Heater 2 state";
BA_ "SPN" SG_ 2164079360 Aftertreatment_2_SCR_Catalyst_Re3 4396;
BA_ "SystemSignalLongSymbol" SG_ 2164079360 Aftertreatment_2_SCR_Catalyst_Re3 "Aftertreatment 2 SCR Catalyst Reagent Line Heater 2 Preliminary FMI";
BA_ "SPN" SG_ 2164079360 Aftertreatment_2_SCR_Catalyst_Re4 4397;
BA_ "SystemSignalLongSymbol" SG_ 2164079360 Aftertreatment_2_SCR_Catalyst_Re4 "Aftertreatment 2 SCR Catalyst Reagent Line Heater 3 state";
BA_ "SPN" SG_ 2164079360 Aftertreatment_2_SCR_Catalyst_Re5 4398;
BA_ "SystemSignalLongSymbol" SG_ 2164079360 Aftertreatment_2_SCR_Catalyst_Re5 "Aftertreatment 2 SCR Catalyst Reagent Line Heater 3 Preliminary FMI";
BA_ "SPN" SG_ 2164079360 Aftertreatment_2_SCR_Catalyst_Re6 4399;
BA_ "SystemSignalLongSymbol" SG_ 2164079360 Aftertreatment_2_SCR_Catalyst_Re6 "Aftertreatment 2 SCR Catalyst Reagent Line Heater 4 state";
BA_ "SPN" SG_ 2164079360 Aftertreatment_2_SCR_Catalyst_Re7 4400;
BA_ "SystemSignalLongSymbol" SG_ 2164079360 Aftertreatment_2_SCR_Catalyst_Re7 "Aftertreatment 2 SCR Catalyst Reagent Line Heater 4 Preliminary FMI";
BA_ "SPN" SG_ 2164079616 Aftertreatment_1_SCR_Catalyst_Re0 4374;
BA_ "SystemSignalLongSymbol" SG_ 2164079616 Aftertreatment_1_SCR_Catalyst_Re0 "Aftertreatment 1 SCR Catalyst Reagent Pump Motor Speed (feedback on pump speed)";
BA_ "SPN" SG_ 2164079616 Aftertreatment_1_SCR_Catalyst_Re1 4375;
BA_ "SystemSignalLongSymbol" SG_ 2164079616 Aftertreatment_1_SCR_Catalyst_Re1 "Aftertreatment 1 SCR Catalyst Reagent Pump Drive Percentage (Command to pump)";
BA_ "SPN" SG_ 2164079616 Aftertreatment_1_SCR_Catalyst_Re2 4376;
BA_ "SystemSignalLongSymbol" SG_ 2164079616 Aftertreatment_1_SCR_Catalyst_Re2 "Aftertreatment 1 SCR Catalyst Reagent Return Valve (Directional command for return)";
BA_ "SPN" SG_ 2164079872 Aftertreatment_1_SCR_Catalyst_Re0 4367;
BA_ "SystemSignalLongSymbol" SG_ 2164079872 Aftertreatment_1_SCR_Catalyst_Re0 "Aftertreatment 1 SCR Catalyst Reagent Tank 2 Level";
BA_ "SPN" SG_ 2164079872 Aftertreatment_1_SCR_Catalyst_Re1 4368;
BA_ "SystemSignalLongSymbol" SG_ 2164079872 Aftertreatment_1_SCR_Catalyst_Re1 "Aftertreatment 1 SCR Catalyst Reagent Tank 2 Temperature";
BA_ "SPN" SG_ 2164079872 Aftertreatment_1_SCR_Catalyst_Re2 4369;
BA_ "SystemSignalLongSymbol" SG_ 2164079872 Aftertreatment_1_SCR_Catalyst_Re2 "Aftertreatment 1 SCR Catalyst Reagent Tank 2 Level 2";
BA_ "SPN" SG_ 2164079872 Aftertreatment_1_SCR_Catalyst_Re3 4370;
BA_ "SystemSignalLongSymbol" SG_ 2164079872 Aftertreatment_1_SCR_Catalyst_Re3 "Aftertreatment 1 SCR Catalyst Reagent Tank 2 Level Preliminary FMI";
BA_ "SPN" SG_ 2164079872 Aftertreatment_1_SCR_Reagent_Tan 4371;
BA_ "SystemSignalLongSymbol" SG_ 2164079872 Aftertreatment_1_SCR_Reagent_Tan "Aftertreatment 1 SCR Reagent Tank 2 Temperature Preliminary FMI";
BA_ "SPN" SG_ 2164079872 Aftertreatment_1_SCR_Catalyst_Re4 4372;
BA_ "SystemSignalLongSymbol" SG_ 2164079872 Aftertreatment_1_SCR_Catalyst_Re4 "Aftertreatment 1 SCR Catalyst Reagent Tank 2 Heater (light-off)";
BA_ "SPN" SG_ 2164079872 Aftertreatment_1_SCR_Catalyst_Re5 4373;
BA_ "SystemSignalLongSymbol" SG_ 2164079872 Aftertreatment_1_SCR_Catalyst_Re5 "Aftertreatment 1 SCR Catalyst Reagent Tank 2 Heater Preliminary FMI";
BA_ "SPN" SG_ 2164080128 Aftertreatment_1_SCR_Catalyst_In0 4360;
BA_ "SystemSignalLongSymbol" SG_ 2164080128 Aftertreatment_1_SCR_Catalyst_In0 "Aftertreatment 1 SCR Catalyst Intake Gas Temperature";
BA_ "SPN" SG_ 2164080128 Aftertreatment_1_SCR_Catalyst_In1 4361;
BA_ "SystemSignalLongSymbol" SG_ 2164080128 Aftertreatment_1_SCR_Catalyst_In1 "Aftertreatment 1 SCR Catalyst Intake Gas Temperature Preliminary FMI";
BA_ "SPN" SG_ 2164080128 Aftertreatment_1_SCR_Catalyst_Ou0 4363;
BA_ "SystemSignalLongSymbol" SG_ 2164080128 Aftertreatment_1_SCR_Catalyst_Ou0 "Aftertreatment 1 SCR Catalyst Outlet Gas Temperature";
BA_ "SPN" SG_ 2164080128 Aftertreatment_1_SCR_Catalyst_Ou1 4362;
BA_ "SystemSignalLongSymbol" SG_ 2164080128 Aftertreatment_1_SCR_Catalyst_Ou1 "Aftertreatment 1 SCR Catalyst Outlet Gas Temperature Preliminary FMI";
BA_ "SPN" SG_ 2164080384 Aftertreatment_1_SCR_Catalyst_Ex0 4358;
BA_ "SystemSignalLongSymbol" SG_ 2164080384 Aftertreatment_1_SCR_Catalyst_Ex0 "Aftertreatment 1 SCR Catalyst Exhaust Gas Differential Pressure";
BA_ "SPN" SG_ 2164080384 Aftertreatment_1_SCR_Catalyst_Ex1 4359;
BA_ "SystemSignalLongSymbol" SG_ 2164080384 Aftertreatment_1_SCR_Catalyst_Ex1 "Aftertreatment 1 SCR Catalyst Exhaust Gas Differential Pressure Preliminary FMI";
BA_ "SPN" SG_ 2164080640 Aftertreatment_1_SCR_Doser_Fault 4352;
BA_ "SystemSignalLongSymbol" SG_ 2164080640 Aftertreatment_1_SCR_Doser_Fault "Aftertreatment 1 SCR Doser Fault Suppression Request";
BA_ "SPN" SG_ 2164080640 Aftertreatment_1_SCR_Doser_Heati 4353;
BA_ "SystemSignalLongSymbol" SG_ 2164080640 Aftertreatment_1_SCR_Doser_Heati "Aftertreatment 1 SCR Doser Heating Mode Request";
BA_ "SPN" SG_ 2164080640 Aftertreatment_1_SCR_Catalyst_Re0 4354;
BA_ "SystemSignalLongSymbol" SG_ 2164080640 Aftertreatment_1_SCR_Catalyst_Re0 "Aftertreatment 1 SCR Catalyst Reagent Line Heater 1 (request)";
BA_ "SPN" SG_ 2164080640 Aftertreatment_1_SCR_Catalyst_Re1 4355;
BA_ "SystemSignalLongSymbol" SG_ 2164080640 Aftertreatment_1_SCR_Catalyst_Re1 "Aftertreatment 1 SCR Catalyst Reagent Line Heater 2 (request)";
BA_ "SPN" SG_ 2164080640 Aftertreatment_1_SCR_Catalyst_Re2 4356;
BA_ "SystemSignalLongSymbol" SG_ 2164080640 Aftertreatment_1_SCR_Catalyst_Re2 "Aftertreatment 1 SCR Catalyst Reagent Line Heater 3 (request)";
BA_ "SPN" SG_ 2164080640 Aftertreatment_1_SCR_Catalyst_Re3 4357;
BA_ "SystemSignalLongSymbol" SG_ 2164080640 Aftertreatment_1_SCR_Catalyst_Re3 "Aftertreatment 1 SCR Catalyst Reagent Line Heater 4 (request)";
BA_ "SPN" SG_ 2164080896 Aftertreatment_1_SCR_Dosing_Air_0 4335;
BA_ "SystemSignalLongSymbol" SG_ 2164080896 Aftertreatment_1_SCR_Dosing_Air_0 "Aftertreatment 1 SCR Dosing Air Assist Absolute Pressure";
BA_ "SPN" SG_ 2164080896 Aftertreatment_1_SCR_Dosing_Air_1 4336;
BA_ "SystemSignalLongSymbol" SG_ 2164080896 Aftertreatment_1_SCR_Dosing_Air_1 "Aftertreatment 1 SCR Dosing Air Assist Valve (measured, 0 = closed)";
BA_ "SPN" SG_ 2164080896 Aftertreatment_1_SCR_Dosing_Reag 4337;
BA_ "SystemSignalLongSymbol" SG_ 2164080896 Aftertreatment_1_SCR_Dosing_Reag "Aftertreatment 1 SCR Dosing Reagent Temperature (closest to dosing valve)";
BA_ "SPN" SG_ 2164080896 Aftertreatment_1_SCR_Dosing_Valv 4338;
BA_ "SystemSignalLongSymbol" SG_ 2164080896 Aftertreatment_1_SCR_Dosing_Valv "Aftertreatment 1 SCR Dosing Valve Exhaust Temp. Reduction Request";
BA_ "SPN" SG_ 2164080896 Aftertreatment_1_SCR_Feedback_Co 4339;
BA_ "SystemSignalLongSymbol" SG_ 2164080896 Aftertreatment_1_SCR_Feedback_Co "Aftertreatment 1 SCR Feedback Control Status (Open/Closed Loop)";
BA_ "SPN" SG_ 2164080896 Aftertreatment_1_SCR_Catalyst_Re0 4340;
BA_ "SystemSignalLongSymbol" SG_ 2164080896 Aftertreatment_1_SCR_Catalyst_Re0 "Aftertreatment 1 SCR Catalyst Reagent Line Heater 1 state";
BA_ "SPN" SG_ 2164080896 Aftertreatment_1_SCR_Catalyst_Re1 4341;
BA_ "SystemSignalLongSymbol" SG_ 2164080896 Aftertreatment_1_SCR_Catalyst_Re1 "Aftertreatment 1 SCR Catalyst Reagent Line Heater 1 Preliminary FMI";
BA_ "SPN" SG_ 2164080896 Aftertreatment_1_SCR_Catalyst_Re2 4342;
BA_ "SystemSignalLongSymbol" SG_ 2164080896 Aftertreatment_1_SCR_Catalyst_Re2 "Aftertreatment 1 SCR Catalyst Reagent Line Heater 2 state";
BA_ "SPN" SG_ 2164080896 Aftertreatment_1_SCR_Catalyst_Re3 4343;
BA_ "SystemSignalLongSymbol" SG_ 2164080896 Aftertreatment_1_SCR_Catalyst_Re3 "Aftertreatment 1 SCR Catalyst Reagent Line Heater 2 Preliminary FMI";
BA_ "SPN" SG_ 2164080896 Aftertreatment_1_SCR_Catalyst_Re4 4344;
BA_ "SystemSignalLongSymbol" SG_ 2164080896 Aftertreatment_1_SCR_Catalyst_Re4 "Aftertreatment 1 SCR Catalyst Reagent Line Heater 3 state";
BA_ "SPN" SG_ 2164080896 Aftertreatment_1_SCR_Catalyst_Re5 4345;
BA_ "SystemSignalLongSymbol" SG_ 2164080896 Aftertreatment_1_SCR_Catalyst_Re5 "Aftertreatment 1 SCR Catalyst Reagent Line Heater 3 Preliminary FMI";
BA_ "SPN" SG_ 2164080896 Aftertreatment_1_SCR_Catalyst_Re6 4346;
BA_ "SystemSignalLongSymbol" SG_ 2164080896 Aftertreatment_1_SCR_Catalyst_Re6 "Aftertreatment 1 SCR Catalyst Reagent Line Heater 4 state";
BA_ "SPN" SG_ 2164080896 Aftertreatment_1_SCR_Catalyst_Re7 4347;
BA_ "SystemSignalLongSymbol" SG_ 2164080896 Aftertreatment_1_SCR_Catalyst_Re7 "Aftertreatment 1 SCR Catalyst Reagent Line Heater 4 Preliminary FMI";
BA_ "SPN" SG_ 2164081664 Aftertreatment_2_Fuel_Pressure_2 4303;
BA_ "SPN" SG_ 2164081920 Aftertreatment_2_Three_Way_Catal0 4295;
BA_ "SystemSignalLongSymbol" SG_ 2164081920 Aftertreatment_2_Three_Way_Catal0 "Aftertreatment 2 Three Way Catalytic Converter Intake Gas Temperature";
BA_ "SPN" SG_ 2164081920 Aftertreatment_2_Three_Way_Catal1 4296;
BA_ "SystemSignalLongSymbol" SG_ 2164081920 Aftertreatment_2_Three_Way_Catal1 "Aftertreatment 2 Three Way Catalytic Converter Outlet Gas Temperature";
BA_ "SPN" SG_ 2164081920 Aftertreatment_2_Three_Way_Catal2 4297;
BA_ "SystemSignalLongSymbol" SG_ 2164081920 Aftertreatment_2_Three_Way_Catal2 "Aftertreatment 2 Three Way Catalytic Converter Differential Pressure";
BA_ "SPN" SG_ 2164081920 Aftertreatment_2_Three_Way_Catal3 4298;
BA_ "SystemSignalLongSymbol" SG_ 2164081920 Aftertreatment_2_Three_Way_Catal3 "Aftertreatment 2 Three Way Catalytic Converter Intake Gas Temperature Preliminary FMI";
BA_ "SPN" SG_ 2164081920 Aftertreatment_2_Three_Way_Catal4 4299;
BA_ "SystemSignalLongSymbol" SG_ 2164081920 Aftertreatment_2_Three_Way_Catal4 "Aftertreatment 2 Three Way Catalytic Converter Outlet Gas Temperature Preliminary FMI";
BA_ "SPN" SG_ 2164081920 Aftertreatment_2_Three_Way_Catal5 4300;
BA_ "SystemSignalLongSymbol" SG_ 2164081920 Aftertreatment_2_Three_Way_Catal5 "Aftertreatment 2 Three Way Catalytic Converter Differential Pressure Preliminary FMI";
BA_ "SPN" SG_ 2164082176 Aftertreatment_1_Three_Way_Catal0 4289;
BA_ "SystemSignalLongSymbol" SG_ 2164082176 Aftertreatment_1_Three_Way_Catal0 "Aftertreatment 1 Three Way Catalytic Converter Intake Gas Temperature";
BA_ "SPN" SG_ 2164082176 Aftertreatment_1_Three_Way_Catal1 4290;
BA_ "SystemSignalLongSymbol" SG_ 2164082176 Aftertreatment_1_Three_Way_Catal1 "Aftertreatment 1 Three Way Catalytic Converter Outlet Gas Temperature";
BA_ "SPN" SG_ 2164082176 Aftertreatment_1_Three_Way_Catal2 4291;
BA_ "SystemSignalLongSymbol" SG_ 2164082176 Aftertreatment_1_Three_Way_Catal2 "Aftertreatment 1 Three Way Catalytic Converter Differential Pressure";
BA_ "SPN" SG_ 2164082176 Aftertreatment_1_Three_Way_Catal3 4292;
BA_ "SystemSignalLongSymbol" SG_ 2164082176 Aftertreatment_1_Three_Way_Catal3 "Aftertreatment 1 Three Way Catalytic Converter Intake Gas Temperature Preliminary FMI";
BA_ "SPN" SG_ 2164082176 Aftertreatment_1_Three_Way_Catal4 4293;
BA_ "SystemSignalLongSymbol" SG_ 2164082176 Aftertreatment_1_Three_Way_Catal4 "Aftertreatment 1 Three Way Catalytic Converter Outlet Gas Temperature Preliminary FMI";
BA_ "SPN" SG_ 2164082176 Aftertreatment_1_Three_Way_Catal5 4294;
BA_ "SystemSignalLongSymbol" SG_ 2164082176 Aftertreatment_1_Three_Way_Catal5 "Aftertreatment 1 Three Way Catalytic Converter Differential Pressure Preliminary FMI";
BA_ "SPN" SG_ 2164082432 Transmission_Mode_Label 4254;
BA_ "SPN" SG_ 2164082688 Long_term_Fuel_Trim___Bank_2 4239;
BA_ "SPN" SG_ 2164082688 Short_term_Fuel_Trim___Bank_2 4238;
BA_ "SPN" SG_ 2164082688 Engine_Exhaust_Gas_Oxygen_Sensor 4241;
BA_ "SystemSignalLongSymbol" SG_ 2164082688 Engine_Exhaust_Gas_Oxygen_Sensor "Engine Exhaust Gas Oxygen Sensor Closed Loop Operation, Bank 2";
BA_ "SPN" SG_ 2164082944 Long_term_Fuel_Trim___Bank_1 4237;
BA_ "SPN" SG_ 2164082944 Short_term_Fuel_Trim___Bank_1 4236;
BA_ "SPN" SG_ 2164082944 Engine_Exhaust_Gas_Oxygen_Sensor 4240;
BA_ "SystemSignalLongSymbol" SG_ 2164082944 Engine_Exhaust_Gas_Oxygen_Sensor "Engine Exhaust Gas Oxygen Sensor Closed Loop Operation, Bank 1";
BA_ "SPN" SG_ 2164084992 Aftercooler_Coolant_Thermostat_M 4198;
BA_ "SystemSignalLongSymbol" SG_ 2164084992 Aftercooler_Coolant_Thermostat_M "Aftercooler Coolant Thermostat Mode";
BA_ "SPN" SG_ 2164084992 Desired_Aftercooler_Coolant_Inle 4199;
BA_ "SystemSignalLongSymbol" SG_ 2164084992 Desired_Aftercooler_Coolant_Inle "Desired Aftercooler Coolant Inlet Temperature";
BA_ "SPN" SG_ 2164084992 Desired_Aftercooler_Coolant_Ther 4200;
BA_ "SystemSignalLongSymbol" SG_ 2164084992 Desired_Aftercooler_Coolant_Ther "Desired Aftercooler Coolant Thermostat Opening";
BA_ "SPN" SG_ 2164085248 Engine_Coolant_Thermostat_Mode 4195;
BA_ "SPN" SG_ 2164085248 Desired_Engine_Coolant_Pump_Outl 4196;
BA_ "SystemSignalLongSymbol" SG_ 2164085248 Desired_Engine_Coolant_Pump_Outl "Desired Engine Coolant Pump Outlet Temperature";
BA_ "SPN" SG_ 2164085248 Desired_Engine_Coolant_Thermosta 4197;
BA_ "SystemSignalLongSymbol" SG_ 2164085248 Desired_Engine_Coolant_Thermosta "Desired Engine Coolant Thermostat Opening";
BA_ "SPN" SG_ 2164085504 Engine_Exhaust_Gas_Temperature_A0 4151;
BA_ "SystemSignalLongSymbol" SG_ 2164085504 Engine_Exhaust_Gas_Temperature_A0 "Engine Exhaust Gas Temperature Average";
BA_ "SPN" SG_ 2164085504 Engine_Exhaust_Gas_Temperature_A1 4153;
BA_ "SystemSignalLongSymbol" SG_ 2164085504 Engine_Exhaust_Gas_Temperature_A1 "Engine Exhaust Gas Temperature Average - Bank 1";
BA_ "SPN" SG_ 2164085504 Engine_Exhaust_Gas_Temperature_A2 4152;
BA_ "SystemSignalLongSymbol" SG_ 2164085504 Engine_Exhaust_Gas_Temperature_A2 "Engine Exhaust Gas Temperature Average - Bank 2";
BA_ "SPN" SG_ 2164090112 Aftertreatment_1_Fuel_Pressure_2 4077;
BA_ "SPN" SG_ 2164090368 Engine_Coolant_Temperature_2 4076;
BA_ "SPN" SG_ 2164090368 Engine_Coolant_Pump_Outlet_Tempe 4193;
BA_ "SystemSignalLongSymbol" SG_ 2164090368 Engine_Coolant_Pump_Outlet_Tempe "Engine Coolant Pump Outlet Temperature";
BA_ "SPN" SG_ 2164090368 Engine_Coolant_Thermostat_Openin 4194;
BA_ "SystemSignalLongSymbol" SG_ 2164090368 Engine_Coolant_Thermostat_Openin "Engine Coolant Thermostat Opening";
BA_ "SPN" SG_ 2164090368 Engine_Exhaust_Valve_Actuation_S 4288;
BA_ "SystemSignalLongSymbol" SG_ 2164090368 Engine_Exhaust_Valve_Actuation_S "Engine Exhaust Valve Actuation System Oil Temperature";
BA_ "SPN" SG_ 2164090624 Zero_Net_Vehicle_Weight_Change 4075;
BA_ "SPN" SG_ 2164090880 Gross_Combination_Weight 417;
BA_ "SPN" SG_ 2164090880 Net_Vehicle_Weight_Change 413;
BA_ "SPN" SG_ 2164091136 Axle_Group_Location 4074;
BA_ "SPN" SG_ 2164091136 Axle_Group_Empty_Weight_Calibrat 408;
BA_ "SystemSignalLongSymbol" SG_ 2164091136 Axle_Group_Empty_Weight_Calibrat "Axle Group Empty Weight Calibration";
BA_ "SPN" SG_ 2164091136 Axle_Group_Full_Weight_Calibrati 407;
BA_ "SystemSignalLongSymbol" SG_ 2164091136 Axle_Group_Full_Weight_Calibrati "Axle Group Full Weight Calibration";
BA_ "SPN" SG_ 2164091392 Axle_Group_Location 4073;
BA_ "SPN" SG_ 2164091392 Axle_Group_Weight 409;
BA_ "SPN" SG_ 2164091648 Steer_Axle_Group_Weight_Availabl 4059;
BA_ "SystemSignalLongSymbol" SG_ 2164091648 Steer_Axle_Group_Weight_Availabl "Steer Axle Group Weight Available";
BA_ "SPN" SG_ 2164091648 Lift_Axle_Group_Weight_Available 4060;
BA_ "SPN" SG_ 2164091648 Drive_Axle_Group_Weight_Availabl 4061;
BA_ "SystemSignalLongSymbol" SG_ 2164091648 Drive_Axle_Group_Weight_Availabl "Drive Axle Group Weight Available";
BA_ "SPN" SG_ 2164091648 Tag_Axle_Group_Weight_Available 4062;
BA_ "SPN" SG_ 2164091648 Additional_Tractor_Axle_Group_We 4063;
BA_ "SystemSignalLongSymbol" SG_ 2164091648 Additional_Tractor_Axle_Group_We "Additional Tractor Axle Group Weight Available";
BA_ "SPN" SG_ 2164091648 Trailer_A_Axle_Group_Weight_Avai 4064;
BA_ "SystemSignalLongSymbol" SG_ 2164091648 Trailer_A_Axle_Group_Weight_Avai "Trailer A Axle Group Weight Available";
BA_ "SPN" SG_ 2164091648 Trailer_B_Axle_Group_Weight_Avai 4065;
BA_ "SystemSignalLongSymbol" SG_ 2164091648 Trailer_B_Axle_Group_Weight_Avai "Trailer B Axle Group Weight Available";
BA_ "SPN" SG_ 2164091648 Trailer_C_Axle_Group_Weight_Avai 4066;
BA_ "SystemSignalLongSymbol" SG_ 2164091648 Trailer_C_Axle_Group_Weight_Avai "Trailer C Axle Group Weight Available";
BA_ "SPN" SG_ 2164091648 Trailer_D_Axle_Group_Weight_Avai 4067;
BA_ "SystemSignalLongSymbol" SG_ 2164091648 Trailer_D_Axle_Group_Weight_Avai "Trailer D Axle Group Weight Available";
BA_ "SPN" SG_ 2164091648 Trailer_E_Axle_Group_Weight_Avai 4068;
BA_ "SystemSignalLongSymbol" SG_ 2164091648 Trailer_E_Axle_Group_Weight_Avai "Trailer E Axle Group Weight Available";
BA_ "SPN" SG_ 2164091648 Trailer_F_Axle_Group_Weight_Avai 4069;
BA_ "SystemSignalLongSymbol" SG_ 2164091648 Trailer_F_Axle_Group_Weight_Avai "Trailer F Axle Group Weight Available";
BA_ "SPN" SG_ 2164091648 Trailer_G_Axle_Group_Weight_Avai 4070;
BA_ "SystemSignalLongSymbol" SG_ 2164091648 Trailer_G_Axle_Group_Weight_Avai "Trailer G Axle Group Weight Available";
BA_ "SPN" SG_ 2164091648 Trailer_H_Axle_Group_Weight_Avai 4071;
BA_ "SystemSignalLongSymbol" SG_ 2164091648 Trailer_H_Axle_Group_Weight_Avai "Trailer H Axle Group Weight Available";
BA_ "SPN" SG_ 2164091648 Additional_Trailer_Axle_Group_We 4072;
BA_ "SystemSignalLongSymbol" SG_ 2164091648 Additional_Trailer_Axle_Group_We "Additional Trailer Axle Group Weight Available";
BA_ "SPN" SG_ 2164091904 Aftertreatment_2_Secondary_Air_D 3833;
BA_ "SystemSignalLongSymbol" SG_ 2164091904 Aftertreatment_2_Secondary_Air_D "Aftertreatment 2 Secondary Air Differential Pressure";
BA_ "SPN" SG_ 2164091904 Aftertreatment_2_Secondary_Air_T 3834;
BA_ "SystemSignalLongSymbol" SG_ 2164091904 Aftertreatment_2_Secondary_Air_T "Aftertreatment 2 Secondary Air Temperature";
BA_ "SPN" SG_ 2164091904 Aftertreatment_2_Secondary_Air_M 3835;
BA_ "SystemSignalLongSymbol" SG_ 2164091904 Aftertreatment_2_Secondary_Air_M "Aftertreatment 2 Secondary Air Mass Flow";
BA_ "SPN" SG_ 2164091904 Aftertreatment_2_Secondary_Air_P 3838;
BA_ "SystemSignalLongSymbol" SG_ 2164091904 Aftertreatment_2_Secondary_Air_P "Aftertreatment 2 Secondary Air Pressure";
BA_ "SPN" SG_ 2164092160 Aftertreatment_1_Secondary_Air_D 3830;
BA_ "SystemSignalLongSymbol" SG_ 2164092160 Aftertreatment_1_Secondary_Air_D "Aftertreatment 1 Secondary Air Differential Pressure";
BA_ "SPN" SG_ 2164092160 Aftertreatment_1_Secondary_Air_T 3831;
BA_ "SystemSignalLongSymbol" SG_ 2164092160 Aftertreatment_1_Secondary_Air_T "Aftertreatment 1 Secondary Air Temperature";
BA_ "SPN" SG_ 2164092160 Aftertreatment_1_Secondary_Air_M 3832;
BA_ "SystemSignalLongSymbol" SG_ 2164092160 Aftertreatment_1_Secondary_Air_M "Aftertreatment 1 Secondary Air Mass Flow";
BA_ "SPN" SG_ 2164092160 Aftertreatment_1_Secondary_Air_P 3837;
BA_ "SystemSignalLongSymbol" SG_ 2164092160 Aftertreatment_1_Secondary_Air_P "Aftertreatment 1 Secondary Air Pressure";
BA_ "SPN" SG_ 2164092416 Aftertreatment_1_SCR_Average_Cat 3826;
BA_ "SystemSignalLongSymbol" SG_ 2164092416 Aftertreatment_1_SCR_Average_Cat "Aftertreatment 1 SCR Average Catalyst Reagent Consumption (15 hr avg)";
BA_ "SPN" SG_ 2164092416 Aftertreatment_1_SCR_Commanded_C 3828;
BA_ "SystemSignalLongSymbol" SG_ 2164092416 Aftertreatment_1_SCR_Commanded_C "Aftertreatment 1 SCR Commanded Catalyst Reagent Consumption (15 hr avg)";
BA_ "SPN" SG_ 2164092416 Aftertreatment_1_SCR_Catalyst_Co 4364;
BA_ "SystemSignalLongSymbol" SG_ 2164092416 Aftertreatment_1_SCR_Catalyst_Co "Aftertreatment 1 SCR Catalyst Conversion Efficiency";
BA_ "SPN" SG_ 2164092672 Engine_Exhaust_Gas_Recirculation 3821;
BA_ "SystemSignalLongSymbol" SG_ 2164092672 Engine_Exhaust_Gas_Recirculation "Engine Exhaust Gas Recirculation (EGR) Valve 2 Control";
BA_ "SPN" SG_ 2164092928 Retract_Status_of_ramp_1 3810;
BA_ "SPN" SG_ 2164092928 Enable_status_of_ramp_1 3811;
BA_ "SPN" SG_ 2164092928 Movement_status_of_ramp_1 3812;
BA_ "SPN" SG_ 2164092928 Retract_Status_of_ramp_2 3813;
BA_ "SPN" SG_ 2164092928 Enable_status_of_ramp_2 3814;
BA_ "SPN" SG_ 2164092928 Movement_status_of_ramp_2 3815;
BA_ "SPN" SG_ 2164092928 Retract_Status_of_ramp_3 3816;
BA_ "SPN" SG_ 2164092928 Enable_status_of_ramp_3 3817;
BA_ "SPN" SG_ 2164092928 Movement_status_of_ramp_3 3818;
BA_ "SPN" SG_ 2164092928 Retract_Status_of_ramp_4 4454;
BA_ "SPN" SG_ 2164092928 Enable_status_of_ramp_4 4455;
BA_ "SPN" SG_ 2164092928 Movement_status_of_ramp_4 4456;
BA_ "SPN" SG_ 2164092928 Retract_Status_of_ramp_5 4457;
BA_ "SPN" SG_ 2164092928 Enable_status_of_ramp_5 4458;
BA_ "SPN" SG_ 2164092928 Movement_status_of_ramp_5 4459;
BA_ "SPN" SG_ 2164093184 Tractor_Brake_Stroke_Axle_1_Left 3785;
BA_ "SPN" SG_ 2164093184 Tractor_Brake_Stroke_Axle_1_Righ 3786;
BA_ "SystemSignalLongSymbol" SG_ 2164093184 Tractor_Brake_Stroke_Axle_1_Righ "Tractor Brake Stroke Axle 1 Right";
BA_ "SPN" SG_ 2164093184 Tractor_Brake_Stroke_Axle_2_Left 3787;
BA_ "SPN" SG_ 2164093184 Tractor_Brake_Stroke_Axle_2_Righ 3788;
BA_ "SystemSignalLongSymbol" SG_ 2164093184 Tractor_Brake_Stroke_Axle_2_Righ "Tractor Brake Stroke Axle 2 Right";
BA_ "SPN" SG_ 2164093184 Tractor_Brake_Stroke_Axle_3_Left 3789;
BA_ "SPN" SG_ 2164093184 Tractor_Brake_Stroke_Axle_3_Righ 3790;
BA_ "SystemSignalLongSymbol" SG_ 2164093184 Tractor_Brake_Stroke_Axle_3_Righ "Tractor Brake Stroke Axle 3 Right";
BA_ "SPN" SG_ 2164093184 Tractor_Brake_Stroke_Axle_4_Left 3791;
BA_ "SPN" SG_ 2164093184 Tractor_Brake_Stroke_Axle_4_Righ 3792;
BA_ "SystemSignalLongSymbol" SG_ 2164093184 Tractor_Brake_Stroke_Axle_4_Righ "Tractor Brake Stroke Axle 4 Right";
BA_ "SPN" SG_ 2164093184 Tractor_Brake_Stroke_Axle_5_Left 3793;
BA_ "SPN" SG_ 2164093184 Tractor_Brake_Stroke_Axle_5_Righ 3794;
BA_ "SystemSignalLongSymbol" SG_ 2164093184 Tractor_Brake_Stroke_Axle_5_Righ "Tractor Brake Stroke Axle 5 Right";
BA_ "SPN" SG_ 2164093184 Trailer_Brake_Stroke_Axle_1_Left 3795;
BA_ "SPN" SG_ 2164093184 Trailer_Brake_Stroke_Axle_1_Righ 3796;
BA_ "SystemSignalLongSymbol" SG_ 2164093184 Trailer_Brake_Stroke_Axle_1_Righ "Trailer Brake Stroke Axle 1 Right";
BA_ "SPN" SG_ 2164093184 Trailer_Brake_Stroke_Axle_2_Left 3797;
BA_ "SPN" SG_ 2164093184 Trailer_Brake_Stroke_Axle_2_Righ 3798;
BA_ "SystemSignalLongSymbol" SG_ 2164093184 Trailer_Brake_Stroke_Axle_2_Righ "Trailer Brake Stroke Axle 2 Right";
BA_ "SPN" SG_ 2164093184 Trailer_Brake_Stroke_Axle_3_Left 3799;
BA_ "SPN" SG_ 2164093184 Trailer_Brake_Stroke_Axle_3_Righ 3800;
BA_ "SystemSignalLongSymbol" SG_ 2164093184 Trailer_Brake_Stroke_Axle_3_Righ "Trailer Brake Stroke Axle 3 Right";
BA_ "SPN" SG_ 2164093184 Trailer_Brake_Stroke_Axle_4_Left 3801;
BA_ "SPN" SG_ 2164093184 Trailer_Brake_Stroke_Axle_4_Righ 3802;
BA_ "SystemSignalLongSymbol" SG_ 2164093184 Trailer_Brake_Stroke_Axle_4_Righ "Trailer Brake Stroke Axle 4 Right";
BA_ "SPN" SG_ 2164093184 Trailer_Brake_Stroke_Axle_5_Left 3803;
BA_ "SPN" SG_ 2164093184 Trailer_Brake_Stroke_Axle_5_Righ 3804;
BA_ "SystemSignalLongSymbol" SG_ 2164093184 Trailer_Brake_Stroke_Axle_5_Righ "Trailer Brake Stroke Axle 5 Right";
BA_ "SPN" SG_ 2164093440 Engine_Spark_Plug_21 1314;
BA_ "SPN" SG_ 2164093440 Engine_Spark_Plug_22 1315;
BA_ "SPN" SG_ 2164093440 Engine_Spark_Plug_23 1316;
BA_ "SPN" SG_ 2164093440 Engine_Spark_Plug_24 1317;
BA_ "SPN" SG_ 2164093696 Engine_Spark_Plug_17 1310;
BA_ "SPN" SG_ 2164093696 Engine_Spark_Plug_18 1311;
BA_ "SPN" SG_ 2164093696 Engine_Spark_Plug_19 1312;
BA_ "SPN" SG_ 2164093696 Engine_Spark_Plug_20 1313;
BA_ "SPN" SG_ 2164093952 Engine_Spark_Plug_13 1306;
BA_ "SPN" SG_ 2164093952 Engine_Spark_Plug_14 1307;
BA_ "SPN" SG_ 2164093952 Engine_Spark_Plug_15 1308;
BA_ "SPN" SG_ 2164093952 Engine_Spark_Plug_16 1309;
BA_ "SPN" SG_ 2164094208 Engine_Spark_Plug_9 1302;
BA_ "SPN" SG_ 2164094208 Engine_Spark_Plug_10 1303;
BA_ "SPN" SG_ 2164094208 Engine_Spark_Plug_11 1304;
BA_ "SPN" SG_ 2164094208 Engine_Spark_Plug_12 1305;
BA_ "SPN" SG_ 2164094464 Engine_Spark_Plug_5 1298;
BA_ "SPN" SG_ 2164094464 Engine_Spark_Plug_6 1299;
BA_ "SPN" SG_ 2164094464 Engine_Spark_Plug_7 1300;
BA_ "SPN" SG_ 2164094464 Engine_Spark_Plug_8 1301;
BA_ "SPN" SG_ 2164094720 Engine_Spark_Plug_1 1294;
BA_ "SPN" SG_ 2164094720 Engine_Spark_Plug_2 1295;
BA_ "SPN" SG_ 2164094720 Engine_Spark_Plug_3 1296;
BA_ "SPN" SG_ 2164094720 Engine_Spark_Plug_4 1297;
BA_ "SPN" SG_ 2164094976 Aftertreatment_2_Trip_Fuel_Used 3741;
BA_ "SPN" SG_ 2164094976 Aftertreatment_2_Trip_Active_Reg 3742;
BA_ "SystemSignalLongSymbol" SG_ 2164094976 Aftertreatment_2_Trip_Active_Reg "Aftertreatment 2 Trip Active Regeneration Time";
BA_ "SPN" SG_ 2164094976 Aftertreatment_2_Trip_Disabled_T 3743;
BA_ "SystemSignalLongSymbol" SG_ 2164094976 Aftertreatment_2_Trip_Disabled_T "Aftertreatment 2 Trip Disabled Time";
BA_ "SPN" SG_ 2164094976 Aftertreatment_2_Trip_Number_of_0 3744;
BA_ "SystemSignalLongSymbol" SG_ 2164094976 Aftertreatment_2_Trip_Number_of_0 "Aftertreatment 2 Trip Number of Active Regenerations";
BA_ "SPN" SG_ 2164094976 Aftertreatment_2_Trip_Passive_Re 3745;
BA_ "SystemSignalLongSymbol" SG_ 2164094976 Aftertreatment_2_Trip_Passive_Re "Aftertreatment 2 Trip Passive Regeneration Time";
BA_ "SPN" SG_ 2164094976 Aftertreatment_2_Trip_Number_of_1 3746;
BA_ "SystemSignalLongSymbol" SG_ 2164094976 Aftertreatment_2_Trip_Number_of_1 "Aftertreatment 2 Trip Number of Passive Regenerations";
BA_ "SPN" SG_ 2164094976 Aftertreatment_2_Trip_Number_of_2 3747;
BA_ "SystemSignalLongSymbol" SG_ 2164094976 Aftertreatment_2_Trip_Number_of_2 "Aftertreatment 2 Trip Number of Active Regeneration Inhibit Requests";
BA_ "SPN" SG_ 2164094976 Aftertreatment_2_Trip_Number_of_3 3748;
BA_ "SystemSignalLongSymbol" SG_ 2164094976 Aftertreatment_2_Trip_Number_of_3 "Aftertreatment 2 Trip Number of Active Regeneration Manual Requests";
BA_ "SPN" SG_ 2164095232 Aftertreatment_1_Trip_Fuel_Used 3733;
BA_ "SPN" SG_ 2164095232 Aftertreatment_1_Trip_Active_Reg 3734;
BA_ "SystemSignalLongSymbol" SG_ 2164095232 Aftertreatment_1_Trip_Active_Reg "Aftertreatment 1 Trip Active Regeneration Time";
BA_ "SPN" SG_ 2164095232 Aftertreatment_1_Trip_Disabled_T 3735;
BA_ "SystemSignalLongSymbol" SG_ 2164095232 Aftertreatment_1_Trip_Disabled_T "Aftertreatment 1 Trip Disabled Time";
BA_ "SPN" SG_ 2164095232 Aftertreatment_1_Trip_Number_of_0 3736;
BA_ "SystemSignalLongSymbol" SG_ 2164095232 Aftertreatment_1_Trip_Number_of_0 "Aftertreatment 1 Trip Number of Active Regenerations";
BA_ "SPN" SG_ 2164095232 Aftertreatment_1_Trip_Passive_Re 3737;
BA_ "SystemSignalLongSymbol" SG_ 2164095232 Aftertreatment_1_Trip_Passive_Re "Aftertreatment 1 Trip Passive Regeneration Time";
BA_ "SPN" SG_ 2164095232 Aftertreatment_1_Trip_Number_of_1 3738;
BA_ "SystemSignalLongSymbol" SG_ 2164095232 Aftertreatment_1_Trip_Number_of_1 "Aftertreatment 1 Trip Number of Passive Regenerations";
BA_ "SPN" SG_ 2164095232 Aftertreatment_1_Trip_Number_of_2 3739;
BA_ "SystemSignalLongSymbol" SG_ 2164095232 Aftertreatment_1_Trip_Number_of_2 "Aftertreatment 1 Trip Number of Active Regeneration Inhibit Requests";
BA_ "SPN" SG_ 2164095232 Aftertreatment_1_Trip_Number_of_3 3740;
BA_ "SystemSignalLongSymbol" SG_ 2164095232 Aftertreatment_1_Trip_Number_of_3 "Aftertreatment 1 Trip Number of Active Regeneration Manual Requests";
BA_ "SPN" SG_ 2164095488 Diesel_Particulate_Filter_2_Soot 3722;
BA_ "SystemSignalLongSymbol" SG_ 2164095488 Diesel_Particulate_Filter_2_Soot "Diesel Particulate Filter 2 Soot Load Percent";
BA_ "SPN" SG_ 2164095488 Diesel_Particulate_Filter_2_Ash_ 3723;
BA_ "SystemSignalLongSymbol" SG_ 2164095488 Diesel_Particulate_Filter_2_Ash_ "Diesel Particulate Filter 2 Ash Load Percent";
BA_ "SPN" SG_ 2164095488 Diesel_Particulate_Filter_2_Time 3724;
BA_ "SystemSignalLongSymbol" SG_ 2164095488 Diesel_Particulate_Filter_2_Time "Diesel Particulate Filter 2 Time Since Last Active Regeneration";
BA_ "SPN" SG_ 2164095744 Diesel_Particulate_Filter_1_Soot 3719;
BA_ "SystemSignalLongSymbol" SG_ 2164095744 Diesel_Particulate_Filter_1_Soot "Diesel Particulate Filter 1 Soot Load Percent";
BA_ "SPN" SG_ 2164095744 Diesel_Particulate_Filter_1_Ash_ 3720;
BA_ "SystemSignalLongSymbol" SG_ 2164095744 Diesel_Particulate_Filter_1_Ash_ "Diesel Particulate Filter 1 Ash Load Percent";
BA_ "SPN" SG_ 2164095744 Diesel_Particulate_Filter_1_Time 3721;
BA_ "SystemSignalLongSymbol" SG_ 2164095744 Diesel_Particulate_Filter_1_Time "Diesel Particulate Filter 1 Time Since Last Active Regeneration";
BA_ "SPN" SG_ 2164096000 Diesel_Particulate_Filter_Lamp_C 3697;
BA_ "SystemSignalLongSymbol" SG_ 2164096000 Diesel_Particulate_Filter_Lamp_C "Diesel Particulate Filter Lamp Command";
BA_ "SPN" SG_ 2164096000 Diesel_Particulate_Filter_Passiv 3699;
BA_ "SystemSignalLongSymbol" SG_ 2164096000 Diesel_Particulate_Filter_Passiv "Diesel Particulate Filter Passive Regeneration Status";
BA_ "SPN" SG_ 2164096000 Diesel_Particulate_Filter_Active0 3700;
BA_ "SystemSignalLongSymbol" SG_ 2164096000 Diesel_Particulate_Filter_Active0 "Diesel Particulate Filter Active Regeneration Status";
BA_ "SPN" SG_ 2164096000 Diesel_Particulate_Filter_Status 3701;
BA_ "SPN" SG_ 2164096000 Diesel_Particulate_Filter_Active1 3702;
BA_ "SystemSignalLongSymbol" SG_ 2164096000 Diesel_Particulate_Filter_Active1 "Diesel Particulate Filter Active Regeneration Inhibited Status";
BA_ "SPN" SG_ 2164096000 Diesel_Particulate_Filter_Active2 3703;
BA_ "SystemSignalLongSymbol" SG_ 2164096000 Diesel_Particulate_Filter_Active2 "Diesel Particulate Filter Active Regeneration Inhibited Due to Inhibit Switch";
BA_ "SPN" SG_ 2164096000 Diesel_Particulate_Filter_Active3 3704;
BA_ "SystemSignalLongSymbol" SG_ 2164096000 Diesel_Particulate_Filter_Active3 "Diesel Particulate Filter Active Regeneration Inhibited Due to Clutch Disengaged";
BA_ "SPN" SG_ 2164096000 Diesel_Particulate_Filter_Active4 3705;
BA_ "SystemSignalLongSymbol" SG_ 2164096000 Diesel_Particulate_Filter_Active4 "Diesel Particulate Filter Active Regeneration Inhibited Due to Service Brake Active";
BA_ "SPN" SG_ 2164096000 Diesel_Particulate_Filter_Active5 3706;
BA_ "SystemSignalLongSymbol" SG_ 2164096000 Diesel_Particulate_Filter_Active5 "Diesel Particulate Filter Active Regeneration Inhibited Due to PTO Active";
BA_ "SPN" SG_ 2164096000 Diesel_Particulate_Filter_Active6 3707;
BA_ "SystemSignalLongSymbol" SG_ 2164096000 Diesel_Particulate_Filter_Active6 "Diesel Particulate Filter Active Regeneration Inhibited Due to Accelerator Pedal Off Idle";
BA_ "SPN" SG_ 2164096000 Diesel_Particulate_Filter_Active7 3708;
BA_ "SystemSignalLongSymbol" SG_ 2164096000 Diesel_Particulate_Filter_Active7 "Diesel Particulate Filter Active Regeneration Inhibited Due to Out of Neutral";
BA_ "SPN" SG_ 2164096000 Diesel_Particulate_Filter_Active8 3709;
BA_ "SystemSignalLongSymbol" SG_ 2164096000 Diesel_Particulate_Filter_Active8 "Diesel Particulate Filter Active Regeneration Inhibited Due to Vehicle Speed Above Allowed Speed";
BA_ "SPN" SG_ 2164096000 Diesel_Particulate_Filter_Active9 3710;
BA_ "SystemSignalLongSymbol" SG_ 2164096000 Diesel_Particulate_Filter_Active9 "Diesel Particulate Filter Active Regeneration Inhibited Due to Parking Brake Not Set";
BA_ "SPN" SG_ 2164096000 Diesel_Particulate_Filter_Active10 3711;
BA_ "SystemSignalLongSymbol" SG_ 2164096000 Diesel_Particulate_Filter_Active10 "Diesel Particulate Filter Active Regeneration Inhibited Due to Low Exhaust Gas Temperature";
BA_ "SPN" SG_ 2164096000 Diesel_Particulate_Filter_Active11 3712;
BA_ "SystemSignalLongSymbol" SG_ 2164096000 Diesel_Particulate_Filter_Active11 "Diesel Particulate Filter Active Regeneration Inhibited Due to System Fault Active";
BA_ "SPN" SG_ 2164096000 Diesel_Particulate_Filter_Active12 3713;
BA_ "SystemSignalLongSymbol" SG_ 2164096000 Diesel_Particulate_Filter_Active12 "Diesel Particulate Filter Active Regeneration Inhibited Due to System Timeout";
BA_ "SPN" SG_ 2164096000 Diesel_Particulate_Filter_Active13 3714;
BA_ "SystemSignalLongSymbol" SG_ 2164096000 Diesel_Particulate_Filter_Active13 "Diesel Particulate Filter Active Regeneration Inhibited Due to Temporary System Lockout";
BA_ "SPN" SG_ 2164096000 Diesel_Particulate_Filter_Active14 3715;
BA_ "SystemSignalLongSymbol" SG_ 2164096000 Diesel_Particulate_Filter_Active14 "Diesel Particulate Filter Active Regeneration Inhibited Due to Permanent System Lockout";
BA_ "SPN" SG_ 2164096000 Diesel_Particulate_Filter_Active15 3716;
BA_ "SystemSignalLongSymbol" SG_ 2164096000 Diesel_Particulate_Filter_Active15 "Diesel Particulate Filter Active Regeneration Inhibited Due to Engine Not Warmed Up";
BA_ "SPN" SG_ 2164096000 Diesel_Particulate_Filter_Active16 3717;
BA_ "SystemSignalLongSymbol" SG_ 2164096000 Diesel_Particulate_Filter_Active16 "Diesel Particulate Filter Active Regeneration Inhibited Due to Vehicle Speed Below Allowed Speed";
BA_ "SPN" SG_ 2164096000 Diesel_Particulate_Filter_Automa 3718;
BA_ "SystemSignalLongSymbol" SG_ 2164096000 Diesel_Particulate_Filter_Automa "Diesel Particulate Filter Automatic Active Regeneration Initiation Configuration";
BA_ "SPN" SG_ 2164096000 Exhaust_System_High_Temperature_ 3698;
BA_ "SystemSignalLongSymbol" SG_ 2164096000 Exhaust_System_High_Temperature_ "Exhaust System High Temperature Lamp Command";
BA_ "SPN" SG_ 2164096000 Diesel_Particulate_Filter_Active17 4175;
BA_ "SystemSignalLongSymbol" SG_ 2164096000 Diesel_Particulate_Filter_Active17 "Diesel Particulate Filter Active Regeneration Forced Status";
BA_ "SPN" SG_ 2164096512 Left_Headlamp_Dynamic_Bending_Li 3691;
BA_ "SystemSignalLongSymbol" SG_ 2164096512 Left_Headlamp_Dynamic_Bending_Li "Left Headlamp Dynamic Bending Light";
BA_ "SPN" SG_ 2164096512 Right_Headlamp_Dynamic_Bending_L 3692;
BA_ "SystemSignalLongSymbol" SG_ 2164096512 Right_Headlamp_Dynamic_Bending_L "Right Headlamp Dynamic Bending Light";
BA_ "SPN" SG_ 2164096512 Left_Headlamp_Light_Distribution 3693;
BA_ "SPN" SG_ 2164096512 Right_Headlamp_Light_Distributio 3694;
BA_ "SystemSignalLongSymbol" SG_ 2164096512 Right_Headlamp_Light_Distributio "Right Headlamp Light Distribution";
BA_ "SPN" SG_ 2164096768 Maximum_Crank_Attempts_per_Start 3670;
BA_ "SystemSignalLongSymbol" SG_ 2164096768 Maximum_Crank_Attempts_per_Start "Maximum Crank Attempts per Start Attempt";
BA_ "SPN" SG_ 2164097280 EGR_Cooler_Bypass_Actuator_Posti 3672;
BA_ "SystemSignalLongSymbol" SG_ 2164097280 EGR_Cooler_Bypass_Actuator_Posti "EGR Cooler Bypass Actuator Postion";
BA_ "SPN" SG_ 2164097792 Transfer_case_status 3645;
BA_ "SPN" SG_ 2164098048 Engine_Intake_Valve_Actuation_Oi0 3640;
BA_ "SystemSignalLongSymbol" SG_ 2164098048 Engine_Intake_Valve_Actuation_Oi0 "Engine Intake Valve Actuation Oil Pressure for Cylinder #17";
BA_ "SPN" SG_ 2164098048 Engine_Intake_Valve_Actuation_Oi1 3641;
BA_ "SystemSignalLongSymbol" SG_ 2164098048 Engine_Intake_Valve_Actuation_Oi1 "Engine Intake Valve Actuation Oil Pressure for Cylinder #18";
BA_ "SPN" SG_ 2164098048 Engine_Intake_Valve_Actuation_Oi2 3642;
BA_ "SystemSignalLongSymbol" SG_ 2164098048 Engine_Intake_Valve_Actuation_Oi2 "Engine Intake Valve Actuation Oil Pressure for Cylinder #19";
BA_ "SPN" SG_ 2164098048 Engine_Intake_Valve_Actuation_Oi3 3643;
BA_ "SystemSignalLongSymbol" SG_ 2164098048 Engine_Intake_Valve_Actuation_Oi3 "Engine Intake Valve Actuation Oil Pressure for Cylinder #20";
BA_ "SPN" SG_ 2164098304 Engine_Intake_Valve_Actuation_Oi0 3636;
BA_ "SystemSignalLongSymbol" SG_ 2164098304 Engine_Intake_Valve_Actuation_Oi0 "Engine Intake Valve Actuation Oil Pressure for Cylinder #13";
BA_ "SPN" SG_ 2164098304 Engine_Intake_Valve_Actuation_Oi1 3637;
BA_ "SystemSignalLongSymbol" SG_ 2164098304 Engine_Intake_Valve_Actuation_Oi1 "Engine Intake Valve Actuation Oil Pressure for Cylinder #14";
BA_ "SPN" SG_ 2164098304 Engine_Intake_Valve_Actuation_Oi2 3638;
BA_ "SystemSignalLongSymbol" SG_ 2164098304 Engine_Intake_Valve_Actuation_Oi2 "Engine Intake Valve Actuation Oil Pressure for Cylinder #15";
BA_ "SPN" SG_ 2164098304 Engine_Intake_Valve_Actuation_Oi3 3639;
BA_ "SystemSignalLongSymbol" SG_ 2164098304 Engine_Intake_Valve_Actuation_Oi3 "Engine Intake Valve Actuation Oil Pressure for Cylinder #16";
BA_ "SPN" SG_ 2164098560 Engine_Intake_Valve_Actuation_Oi0 3632;
BA_ "SystemSignalLongSymbol" SG_ 2164098560 Engine_Intake_Valve_Actuation_Oi0 "Engine Intake Valve Actuation Oil Pressure for Cylinder #9";
BA_ "SPN" SG_ 2164098560 Engine_Intake_Valve_Actuation_Oi1 3633;
BA_ "SystemSignalLongSymbol" SG_ 2164098560 Engine_Intake_Valve_Actuation_Oi1 "Engine Intake Valve Actuation Oil Pressure for Cylinder #10";
BA_ "SPN" SG_ 2164098560 Engine_Intake_Valve_Actuation_Oi2 3634;
BA_ "SystemSignalLongSymbol" SG_ 2164098560 Engine_Intake_Valve_Actuation_Oi2 "Engine Intake Valve Actuation Oil Pressure for Cylinder #11";
BA_ "SPN" SG_ 2164098560 Engine_Intake_Valve_Actuation_Oi3 3635;
BA_ "SystemSignalLongSymbol" SG_ 2164098560 Engine_Intake_Valve_Actuation_Oi3 "Engine Intake Valve Actuation Oil Pressure for Cylinder #12";
BA_ "SPN" SG_ 2164098816 Engine_Intake_Valve_Actuation_Oi0 3628;
BA_ "SystemSignalLongSymbol" SG_ 2164098816 Engine_Intake_Valve_Actuation_Oi0 "Engine Intake Valve Actuation Oil Pressure for Cylinder #5";
BA_ "SPN" SG_ 2164098816 Engine_Intake_Valve_Actuation_Oi1 3629;
BA_ "SystemSignalLongSymbol" SG_ 2164098816 Engine_Intake_Valve_Actuation_Oi1 "Engine Intake Valve Actuation Oil Pressure for Cylinder #6";
BA_ "SPN" SG_ 2164098816 Engine_Intake_Valve_Actuation_Oi2 3630;
BA_ "SystemSignalLongSymbol" SG_ 2164098816 Engine_Intake_Valve_Actuation_Oi2 "Engine Intake Valve Actuation Oil Pressure for Cylinder #7";
BA_ "SPN" SG_ 2164098816 Engine_Intake_Valve_Actuation_Oi3 3631;
BA_ "SystemSignalLongSymbol" SG_ 2164098816 Engine_Intake_Valve_Actuation_Oi3 "Engine Intake Valve Actuation Oil Pressure for Cylinder #8";
BA_ "SPN" SG_ 2164099072 Engine_Intake_Valve_Actuation_Oi0 3624;
BA_ "SystemSignalLongSymbol" SG_ 2164099072 Engine_Intake_Valve_Actuation_Oi0 "Engine Intake Valve Actuation Oil Pressure for Cylinder #1";
BA_ "SPN" SG_ 2164099072 Engine_Intake_Valve_Actuation_Oi1 3625;
BA_ "SystemSignalLongSymbol" SG_ 2164099072 Engine_Intake_Valve_Actuation_Oi1 "Engine Intake Valve Actuation Oil Pressure for Cylinder #2";
BA_ "SPN" SG_ 2164099072 Engine_Intake_Valve_Actuation_Oi2 3626;
BA_ "SystemSignalLongSymbol" SG_ 2164099072 Engine_Intake_Valve_Actuation_Oi2 "Engine Intake Valve Actuation Oil Pressure for Cylinder #3";
BA_ "SPN" SG_ 2164099072 Engine_Intake_Valve_Actuation_Oi3 3627;
BA_ "SystemSignalLongSymbol" SG_ 2164099072 Engine_Intake_Valve_Actuation_Oi3 "Engine Intake Valve Actuation Oil Pressure for Cylinder #4";
BA_ "SPN" SG_ 2164099328 Vehicle_Roll 3623;
BA_ "SPN" SG_ 2164099584 Number_of_J2012_DTCs 3619;
BA_ "SPN" SG_ 2164099584 J2012_DTC 3620;
BA_ "SPN" SG_ 2164099584 J2012_DTC_Status 3621;
BA_ "SPN" SG_ 2164099584 J2012_DTC_Occurrence_Count 3622;
BA_ "SPN" SG_ 2164099840 Diesel_Particulate_Filter_Intake 3611;
BA_ "SystemSignalLongSymbol" SG_ 2164099840 Diesel_Particulate_Filter_Intake "Diesel Particulate Filter Intake Pressure 2";
BA_ "SPN" SG_ 2164099840 Diesel_Particulate_Filter_Outlet 3612;
BA_ "SystemSignalLongSymbol" SG_ 2164099840 Diesel_Particulate_Filter_Outlet "Diesel Particulate Filter Outlet Pressure 2";
BA_ "SPN" SG_ 2164100096 Diesel_Particulate_Filter_Intake 3609;
BA_ "SystemSignalLongSymbol" SG_ 2164100096 Diesel_Particulate_Filter_Intake "Diesel Particulate Filter Intake Pressure 1";
BA_ "SPN" SG_ 2164100096 Diesel_Particulate_Filter_Outlet 3610;
BA_ "SystemSignalLongSymbol" SG_ 2164100096 Diesel_Particulate_Filter_Outlet "Diesel Particulate Filter Outlet Pressure 1";
BA_ "SPN" SG_ 2164101120 AETC_Data_Collection_Standard 3558;
BA_ "SPN" SG_ 2164101120 Number_of_AETC_data_points 3559;
BA_ "SPN" SG_ 2164101120 AETC_Speed_Value 3560;
BA_ "SPN" SG_ 2164101120 AETC_Torque_value 3561;
BA_ "SPN" SG_ 2164101632 Engine_Operating_State 3543;
BA_ "SPN" SG_ 2164101632 Fuel_Pump_Primer_Control 4082;
BA_ "SPN" SG_ 2164101632 Time_Remaining_in_Engine_Operati 3544;
BA_ "SystemSignalLongSymbol" SG_ 2164101632 Time_Remaining_in_Engine_Operati "Time Remaining in Engine Operating State";
BA_ "SPN" SG_ 2164101632 Engine_Fuel_Shutoff_Vent_Control 3608;
BA_ "SPN" SG_ 2164101632 Engine_Fuel_Shutoff_1_Control 632;
BA_ "SPN" SG_ 2164101632 Engine_Fuel_Shutoff_2_Control 2807;
BA_ "SPN" SG_ 2164101632 Engine_Fuel_Shutoff_Valve_Leak_T 3601;
BA_ "SystemSignalLongSymbol" SG_ 2164101632 Engine_Fuel_Shutoff_Valve_Leak_T "Engine Fuel Shutoff Valve Leak Test Control";
BA_ "SPN" SG_ 2164101632 Engine_Oil_Priming_Pump_Control 3589;
BA_ "SPN" SG_ 2164101632 Engine_Oil_Pre_heater_Control 3602;
BA_ "SPN" SG_ 2164101632 Engine_Electrical_System_Power_C 3603;
BA_ "SystemSignalLongSymbol" SG_ 2164101632 Engine_Electrical_System_Power_C "Engine Electrical System Power Conservation Control";
BA_ "SPN" SG_ 2164101632 Engine_Block___Coolant_Pre_heate 3604;
BA_ "SystemSignalLongSymbol" SG_ 2164101632 Engine_Block___Coolant_Pre_heate "Engine Block / Coolant Pre-heater Control";
BA_ "SPN" SG_ 2164101632 Engine_Coolant_Circulating_Pump_ 3605;
BA_ "SystemSignalLongSymbol" SG_ 2164101632 Engine_Coolant_Circulating_Pump_ "Engine Coolant Circulating Pump Control";
BA_ "SPN" SG_ 2164101632 Engine_Controlled_Shutdown_Reque 3606;
BA_ "SystemSignalLongSymbol" SG_ 2164101632 Engine_Controlled_Shutdown_Reque "Engine Controlled Shutdown Request";
BA_ "SPN" SG_ 2164101632 Engine_Emergency__Immediate__Shu 3607;
BA_ "SystemSignalLongSymbol" SG_ 2164101632 Engine_Emergency__Immediate__Shu "Engine Emergency (Immediate) Shutdown Indication";
BA_ "SPN" SG_ 2164101632 Engine_Derate_Request 3644;
BA_ "SPN" SG_ 2164102144 Engine_Exhaust_Gas_Recirculation0 27;
BA_ "SystemSignalLongSymbol" SG_ 2164102144 Engine_Exhaust_Gas_Recirculation0 "Engine Exhaust Gas Recirculation Valve Position";
BA_ "SPN" SG_ 2164102144 Engine_Exhaust_Gas_Recirculation1 3822;
BA_ "SystemSignalLongSymbol" SG_ 2164102144 Engine_Exhaust_Gas_Recirculation1 "Engine Exhaust Gas Recirculation Valve 2 Position";
BA_ "SPN" SG_ 2164102400 Transmission_Oil_Filter_Restrict 3359;
BA_ "SystemSignalLongSymbol" SG_ 2164102400 Transmission_Oil_Filter_Restrict "Transmission Oil Filter Restriction Switch";
BA_ "SPN" SG_ 2164102400 Transmission_Oil_Level_Switch 3533;
BA_ "SPN" SG_ 2164102400 Transmission_Torque_Converter_Oi 3823;
BA_ "SystemSignalLongSymbol" SG_ 2164102400 Transmission_Torque_Converter_Oi "Transmission Torque Converter Oil Outlet Temperature";
BA_ "SPN" SG_ 2164102400 Transmission_Oil_Life_Remaining 4177;
BA_ "SPN" SG_ 2164103168 Aftertreatment_1_Total_Fuel_Used 3522;
BA_ "SPN" SG_ 2164103168 Aftertreatment_1_Total_Regenerat 3523;
BA_ "SystemSignalLongSymbol" SG_ 2164103168 Aftertreatment_1_Total_Regenerat "Aftertreatment 1 Total Regeneration Time";
BA_ "SPN" SG_ 2164103168 Aftertreatment_1_Total_Disabled_ 3524;
BA_ "SystemSignalLongSymbol" SG_ 2164103168 Aftertreatment_1_Total_Disabled_ "Aftertreatment 1 Total Disabled Time";
BA_ "SPN" SG_ 2164103168 Aftertreatment_1_Total_Number_of0 3525;
BA_ "SystemSignalLongSymbol" SG_ 2164103168 Aftertreatment_1_Total_Number_of0 "Aftertreatment 1 Total Number of Active Regenerations";
BA_ "SPN" SG_ 2164103168 Aftertreatment_1_Total_Passive_R 3725;
BA_ "SystemSignalLongSymbol" SG_ 2164103168 Aftertreatment_1_Total_Passive_R "Aftertreatment 1 Total Passive Regeneration Time";
BA_ "SPN" SG_ 2164103168 Aftertreatment_1_Total_Number_of1 3726;
BA_ "SystemSignalLongSymbol" SG_ 2164103168 Aftertreatment_1_Total_Number_of1 "Aftertreatment 1 Total Number of Passive Regenerations";
BA_ "SPN" SG_ 2164103168 Aftertreatment_1_Total_Number_of2 3727;
BA_ "SystemSignalLongSymbol" SG_ 2164103168 Aftertreatment_1_Total_Number_of2 "Aftertreatment 1 Total Number of Active Regeneration Inhibit Requests";
BA_ "SPN" SG_ 2164103168 Aftertreatment_1_Total_Number_of3 3728;
BA_ "SystemSignalLongSymbol" SG_ 2164103168 Aftertreatment_1_Total_Number_of3 "Aftertreatment 1 Total Number of Active Regeneration Manual Requests";
BA_ "SPN" SG_ 2164103424 Aftertreatment_2_Total_Fuel_Used 3526;
BA_ "SPN" SG_ 2164103424 Aftertreatment_2_Total_Regenerat 3527;
BA_ "SystemSignalLongSymbol" SG_ 2164103424 Aftertreatment_2_Total_Regenerat "Aftertreatment 2 Total Regeneration Time";
BA_ "SPN" SG_ 2164103424 Aftertreatment_2_Total_Disabled_ 3528;
BA_ "SystemSignalLongSymbol" SG_ 2164103424 Aftertreatment_2_Total_Disabled_ "Aftertreatment 2 Total Disabled Time";
BA_ "SPN" SG_ 2164103424 Aftertreatment_2_Total_Number_of0 3529;
BA_ "SystemSignalLongSymbol" SG_ 2164103424 Aftertreatment_2_Total_Number_of0 "Aftertreatment 2 Total Number of Active Regenerations";
BA_ "SPN" SG_ 2164103424 Aftertreatment_2_Total_Passive_R 3729;
BA_ "SystemSignalLongSymbol" SG_ 2164103424 Aftertreatment_2_Total_Passive_R "Aftertreatment 2 Total Passive Regeneration Time";
BA_ "SPN" SG_ 2164103424 Aftertreatment_2_Total_Number_of1 3730;
BA_ "SystemSignalLongSymbol" SG_ 2164103424 Aftertreatment_2_Total_Number_of1 "Aftertreatment 2 Total Number of Passive Regenerations";
BA_ "SPN" SG_ 2164103424 Aftertreatment_2_Total_Number_of2 3731;
BA_ "SystemSignalLongSymbol" SG_ 2164103424 Aftertreatment_2_Total_Number_of2 "Aftertreatment 2 Total Number of Active Regeneration Inhibit Requests";
BA_ "SPN" SG_ 2164103424 Aftertreatment_2_Total_Number_of3 3732;
BA_ "SystemSignalLongSymbol" SG_ 2164103424 Aftertreatment_2_Total_Number_of3 "Aftertreatment 2 Total Number of Active Regeneration Manual Requests";
BA_ "SPN" SG_ 2164103936 Aftertreatment_1_SCR_Catalyst_Re0 3515;
BA_ "SystemSignalLongSymbol" SG_ 2164103936 Aftertreatment_1_SCR_Catalyst_Re0 "Aftertreatment 1 SCR Catalyst Reagent Temperature 2";
BA_ "SPN" SG_ 2164103936 Aftertreatment_1_SCR_Catalyst_Re1 3516;
BA_ "SystemSignalLongSymbol" SG_ 2164103936 Aftertreatment_1_SCR_Catalyst_Re1 "Aftertreatment 1 SCR Catalyst Reagent Concentration";
BA_ "SPN" SG_ 2164103936 Aftertreatment_1_SCR_Catalyst_Re2 3518;
BA_ "SystemSignalLongSymbol" SG_ 2164103936 Aftertreatment_1_SCR_Catalyst_Re2 "Aftertreatment 1 SCR Catalyst Reagent Conductivity";
BA_ "SPN" SG_ 2164103936 Aftertreatment_1_SCR_Catalyst_Re3 3519;
BA_ "SystemSignalLongSymbol" SG_ 2164103936 Aftertreatment_1_SCR_Catalyst_Re3 "Aftertreatment 1 SCR Catalyst Reagent Temperature 2 Preliminary FMI";
BA_ "SPN" SG_ 2164103936 Aftertreatment_1_SCR_Catalyst_Re4 3520;
BA_ "SystemSignalLongSymbol" SG_ 2164103936 Aftertreatment_1_SCR_Catalyst_Re4 "Aftertreatment 1 SCR Catalyst Reagent Properties Preliminary FMI";
BA_ "SPN" SG_ 2164103936 Aftertreatment_1_SCR_Catalyst_Re5 3521;
BA_ "SystemSignalLongSymbol" SG_ 2164103936 Aftertreatment_1_SCR_Catalyst_Re5 "Aftertreatment 1 SCR Catalyst Reagent Type";
BA_ "SPN" SG_ 2164104192 Sensor_supply_voltage_5 3513;
BA_ "SPN" SG_ 2164104192 Sensor_supply_voltage_6 3514;
BA_ "SPN" SG_ 2164104448 Sensor_supply_voltage_1 3509;
BA_ "SPN" SG_ 2164104448 Sensor_supply_voltage_2 3510;
BA_ "SPN" SG_ 2164104448 Sensor_supply_voltage_3 3511;
BA_ "SPN" SG_ 2164104448 Sensor_supply_voltage_4 3512;
BA_ "SPN" SG_ 2164104704 Aftertreatment_2_Supply_Air_Pres 3499;
BA_ "SystemSignalLongSymbol" SG_ 2164104704 Aftertreatment_2_Supply_Air_Pres "Aftertreatment 2 Supply Air Pressure";
BA_ "SPN" SG_ 2164104704 Aftertreatment_2_Purge_Air_Press 3500;
BA_ "SystemSignalLongSymbol" SG_ 2164104704 Aftertreatment_2_Purge_Air_Press "Aftertreatment 2 Purge Air Pressure";
BA_ "SPN" SG_ 2164104704 Aftertreatment_2_Air_Pressure_Co 3501;
BA_ "SystemSignalLongSymbol" SG_ 2164104704 Aftertreatment_2_Air_Pressure_Co "Aftertreatment 2 Air Pressure Control";
BA_ "SPN" SG_ 2164104704 Aftertreatment_2_Air_Pressure_Ac 3502;
BA_ "SystemSignalLongSymbol" SG_ 2164104704 Aftertreatment_2_Air_Pressure_Ac "Aftertreatment 2 Air Pressure Actuator Position";
BA_ "SPN" SG_ 2164104704 Aftertreatment_2_Air_System_Rela 3506;
BA_ "SystemSignalLongSymbol" SG_ 2164104704 Aftertreatment_2_Air_System_Rela "Aftertreatment 2 Air System Relay";
BA_ "SPN" SG_ 2164104704 Aftertreatment_2_Atomization_Air 3505;
BA_ "SystemSignalLongSymbol" SG_ 2164104704 Aftertreatment_2_Atomization_Air "Aftertreatment 2 Atomization Air Actuator";
BA_ "SPN" SG_ 2164104704 Aftertreatment_2_Purge_Air_Actua 3504;
BA_ "SystemSignalLongSymbol" SG_ 2164104704 Aftertreatment_2_Purge_Air_Actua "Aftertreatment 2 Purge Air Actuator";
BA_ "SPN" SG_ 2164104704 Aftertreatment_2_Air_Enable_Actu 3503;
BA_ "SystemSignalLongSymbol" SG_ 2164104704 Aftertreatment_2_Air_Enable_Actu "Aftertreatment 2 Air Enable Actuator";
BA_ "SPN" SG_ 2164104960 Aftertreatment_1_Supply_Air_Pres 3485;
BA_ "SystemSignalLongSymbol" SG_ 2164104960 Aftertreatment_1_Supply_Air_Pres "Aftertreatment 1 Supply Air Pressure";
BA_ "SPN" SG_ 2164104960 Aftertreatment_1_Purge_Air_Press 3486;
BA_ "SystemSignalLongSymbol" SG_ 2164104960 Aftertreatment_1_Purge_Air_Press "Aftertreatment 1 Purge Air Pressure";
BA_ "SPN" SG_ 2164104960 Aftertreatment_1_Air_Pressure_Co 3487;
BA_ "SystemSignalLongSymbol" SG_ 2164104960 Aftertreatment_1_Air_Pressure_Co "Aftertreatment 1 Air Pressure Control";
BA_ "SPN" SG_ 2164104960 Aftertreatment_1_Air_Pressure_Ac 3488;
BA_ "SystemSignalLongSymbol" SG_ 2164104960 Aftertreatment_1_Air_Pressure_Ac "Aftertreatment 1 Air Pressure Actuator Position";
BA_ "SPN" SG_ 2164104960 Aftertreatment_1_Air_System_Rela 3492;
BA_ "SystemSignalLongSymbol" SG_ 2164104960 Aftertreatment_1_Air_System_Rela "Aftertreatment 1 Air System Relay";
BA_ "SPN" SG_ 2164104960 Aftertreatment_1_Atomization_Air 3491;
BA_ "SystemSignalLongSymbol" SG_ 2164104960 Aftertreatment_1_Atomization_Air "Aftertreatment 1 Atomization Air Actuator";
BA_ "SPN" SG_ 2164104960 Aftertreatment_1_Purge_Air_Actua 3490;
BA_ "SystemSignalLongSymbol" SG_ 2164104960 Aftertreatment_1_Purge_Air_Actua "Aftertreatment 1 Purge Air Actuator";
BA_ "SPN" SG_ 2164104960 Aftertreatment_1_Air_Enable_Actu 3489;
BA_ "SystemSignalLongSymbol" SG_ 2164104960 Aftertreatment_1_Air_Enable_Actu "Aftertreatment 1 Air Enable Actuator";
BA_ "SPN" SG_ 2164105216 Aftertreatment_2_Fuel_Pressure_1 3494;
BA_ "SPN" SG_ 2164105216 Aftertreatment_2_Fuel_Rate 3495;
BA_ "SPN" SG_ 2164105216 Aftertreatment_2_Fuel_Pressure_C 3493;
BA_ "SystemSignalLongSymbol" SG_ 2164105216 Aftertreatment_2_Fuel_Pressure_C "Aftertreatment 2 Fuel Pressure Control";
BA_ "SPN" SG_ 2164105216 Aftertreatment_2_Fuel_Drain_Actu 4098;
BA_ "SystemSignalLongSymbol" SG_ 2164105216 Aftertreatment_2_Fuel_Drain_Actu "Aftertreatment 2 Fuel Drain Actuator";
BA_ "SPN" SG_ 2164105216 Aftertreatment_2_Ignition 3498;
BA_ "SPN" SG_ 2164105216 Aftertreatment_2_Regeneration_St 3497;
BA_ "SystemSignalLongSymbol" SG_ 2164105216 Aftertreatment_2_Regeneration_St "Aftertreatment 2 Regeneration Status";
BA_ "SPN" SG_ 2164105216 Aftertreatment_2_Fuel_Enable_Act 3496;
BA_ "SystemSignalLongSymbol" SG_ 2164105216 Aftertreatment_2_Fuel_Enable_Act "Aftertreatment 2 Fuel Enable Actuator";
BA_ "SPN" SG_ 2164105216 Aftertreatment_2_Fuel_Injector_1 4302;
BA_ "SystemSignalLongSymbol" SG_ 2164105216 Aftertreatment_2_Fuel_Injector_1 "Aftertreatment 2 Fuel Injector 1 Heater Control";
BA_ "SPN" SG_ 2164105472 Aftertreatment_1_Fuel_Pressure_1 3480;
BA_ "SPN" SG_ 2164105472 Aftertreatment_1_Fuel_Rate 3481;
BA_ "SPN" SG_ 2164105472 Aftertreatment_1_Fuel_Pressure_C 3479;
BA_ "SystemSignalLongSymbol" SG_ 2164105472 Aftertreatment_1_Fuel_Pressure_C "Aftertreatment 1 Fuel Pressure Control";
BA_ "SPN" SG_ 2164105472 Aftertreatment_1_Fuel_Drain_Actu 4097;
BA_ "SystemSignalLongSymbol" SG_ 2164105472 Aftertreatment_1_Fuel_Drain_Actu "Aftertreatment 1 Fuel Drain Actuator";
BA_ "SPN" SG_ 2164105472 Aftertreatment_1_Ignition 3484;
BA_ "SPN" SG_ 2164105472 Aftertreatment_1_Regeneration_St 3483;
BA_ "SystemSignalLongSymbol" SG_ 2164105472 Aftertreatment_1_Regeneration_St "Aftertreatment 1 Regeneration Status";
BA_ "SPN" SG_ 2164105472 Aftertreatment_1_Fuel_Enable_Act 3482;
BA_ "SystemSignalLongSymbol" SG_ 2164105472 Aftertreatment_1_Fuel_Enable_Act "Aftertreatment 1 Fuel Enable Actuator";
BA_ "SPN" SG_ 2164105472 Aftertreatment_1_Fuel_Injector_1 4301;
BA_ "SystemSignalLongSymbol" SG_ 2164105472 Aftertreatment_1_Fuel_Injector_1 "Aftertreatment 1 Fuel Injector 1 Heater Control";
BA_ "SPN" SG_ 2164105728 Engine_Fuel_Valve_2_Inlet_Absolu 3466;
BA_ "SystemSignalLongSymbol" SG_ 2164105728 Engine_Fuel_Valve_2_Inlet_Absolu "Engine Fuel Valve 2 Inlet Absolute Pressure";
BA_ "SPN" SG_ 2164105728 Engine_Gas_2_Mass_Flow_Rate 3467;
BA_ "SPN" SG_ 2164105728 Engine_Fuel_Temperature_2 3468;
BA_ "SPN" SG_ 2164105728 Engine_Fuel_Valve_2_Outlet_Abso 3469;
BA_ "SystemSignalLongSymbol" SG_ 2164105728 Engine_Fuel_Valve_2_Outlet_Abso "Engine Fuel  Valve 2 Outlet Absolute Pressure";
BA_ "SPN" SG_ 2164105984 Engine_Turbocharger_Compressor_C 3470;
BA_ "SystemSignalLongSymbol" SG_ 2164105984 Engine_Turbocharger_Compressor_C "Engine Turbocharger Compressor Control";
BA_ "SPN" SG_ 2164105984 Engine_Variable_Geometry_Turboch 641;
BA_ "SystemSignalLongSymbol" SG_ 2164105984 Engine_Variable_Geometry_Turboch "Engine Variable Geometry Turbocharger Actuator #1";
BA_ "SPN" SG_ 2164105984 Engine_Turbocharger_Compressor_B 3675;
BA_ "SystemSignalLongSymbol" SG_ 2164105984 Engine_Turbocharger_Compressor_B "Engine Turbocharger Compressor Bypass Actuator Position";
BA_ "SPN" SG_ 2164106240 Enable_Switch___Transfer_case_ou 3455;
BA_ "SystemSignalLongSymbol" SG_ 2164106240 Enable_Switch___Transfer_case_ou "Enable Switch – Transfer case output shaft PTO";
BA_ "SPN" SG_ 2164106240 Enable_Switch___Transmission_out 3454;
BA_ "SystemSignalLongSymbol" SG_ 2164106240 Enable_Switch___Transmission_out "Enable Switch – Transmission output shaft PTO";
BA_ "SPN" SG_ 2164106240 Enable_Switch___Transmission_inp 3452;
BA_ "SystemSignalLongSymbol" SG_ 2164106240 Enable_Switch___Transmission_inp "Enable Switch – Transmission input shaft PTO 1";
BA_ "SPN" SG_ 2164106240 Enable_Switch___PTO_Engine_Flywh 3939;
BA_ "SystemSignalLongSymbol" SG_ 2164106240 Enable_Switch___PTO_Engine_Flywh "Enable Switch - PTO Engine Flywheel";
BA_ "SPN" SG_ 2164106240 Enable_Switch___PTO_Engine_Acces 3945;
BA_ "SystemSignalLongSymbol" SG_ 2164106240 Enable_Switch___PTO_Engine_Acces "Enable Switch - PTO Engine Accessory Drive 2";
BA_ "SPN" SG_ 2164106240 Engagement_Consent___Transfer_ca 3459;
BA_ "SystemSignalLongSymbol" SG_ 2164106240 Engagement_Consent___Transfer_ca "Engagement Consent – Transfer case output shaft PTO";
BA_ "SPN" SG_ 2164106240 Engagement_Consent___Transmissio0 3456;
BA_ "SystemSignalLongSymbol" SG_ 2164106240 Engagement_Consent___Transmissio0 "Engagement Consent – Transmission input shaft PTO 1";
BA_ "SPN" SG_ 2164106240 Engagement_Consent___PTO_Engine_0 3946;
BA_ "SystemSignalLongSymbol" SG_ 2164106240 Engagement_Consent___PTO_Engine_0 "Engagement Consent - PTO Engine Accessory Drive 2";
BA_ "SPN" SG_ 2164106240 Engagement_Status___Transfer_cas 3463;
BA_ "SystemSignalLongSymbol" SG_ 2164106240 Engagement_Status___Transfer_cas "Engagement Status – Transfer case output shaft PTO";
BA_ "SPN" SG_ 2164106240 Engagement_Status___Transmission0 3460;
BA_ "SystemSignalLongSymbol" SG_ 2164106240 Engagement_Status___Transmission0 "Engagement Status – Transmission input shaft PTO 1";
BA_ "SPN" SG_ 2164106240 Engagement_Status___PTO_Engine_F 3941;
BA_ "SystemSignalLongSymbol" SG_ 2164106240 Engagement_Status___PTO_Engine_F "Engagement Status - PTO Engine Flywheel";
BA_ "SPN" SG_ 2164106240 Engagement_Status___PTO_Engine_A 3947;
BA_ "SystemSignalLongSymbol" SG_ 2164106240 Engagement_Status___PTO_Engine_A "Engagement Status - PTO Engine Accessory Drive 2";
BA_ "SPN" SG_ 2164106240 At_least_one_PTO_engaged 3948;
BA_ "SPN" SG_ 2164106496 Lock_Status_of_Door_1 3412;
BA_ "SPN" SG_ 2164106496 Open_Status_of_Door_1 3413;
BA_ "SPN" SG_ 2164106496 Enable_Status_of_Door_1 3414;
BA_ "SPN" SG_ 2164106496 Lock_Status_of_Door_2 3415;
BA_ "SPN" SG_ 2164106496 Open_Status_of_Door_2 3416;
BA_ "SPN" SG_ 2164106496 Enable_Status_of_Door_2 3417;
BA_ "SPN" SG_ 2164106496 Lock_Status_of_Door_3 3418;
BA_ "SPN" SG_ 2164106496 Open_Status_of_Door_3 3419;
BA_ "SPN" SG_ 2164106496 Enable_Status_of_Door_3 3420;
BA_ "SPN" SG_ 2164106496 Lock_Status_of_Door_4 3421;
BA_ "SPN" SG_ 2164106496 Open_Status_of_Door_4 3422;
BA_ "SPN" SG_ 2164106496 Enable_Status_of_Door_4 3423;
BA_ "SPN" SG_ 2164106496 Lock_Status_of_Door_5 3424;
BA_ "SPN" SG_ 2164106496 Open_Status_of_Door_5 3425;
BA_ "SPN" SG_ 2164106496 Enable_Status_of_Door_5 3426;
BA_ "SPN" SG_ 2164106496 Lock_Status_of_Door_6 3427;
BA_ "SPN" SG_ 2164106496 Open_Status_of_Door_6 3428;
BA_ "SPN" SG_ 2164106496 Enable_Status_of_Door_6 3429;
BA_ "SPN" SG_ 2164106496 Lock_Status_of_Door_7 3430;
BA_ "SPN" SG_ 2164106496 Open_Status_of_Door_7 3431;
BA_ "SPN" SG_ 2164106496 Enable_Status_of_Door_7 3432;
BA_ "SPN" SG_ 2164106496 Lock_Status_of_Door_8 3433;
BA_ "SPN" SG_ 2164106496 Open_Status_of_Door_8 3434;
BA_ "SPN" SG_ 2164106496 Enable_Status_of_Door_8 3435;
BA_ "SPN" SG_ 2164106496 Lock_Status_of_Door_9 3436;
BA_ "SPN" SG_ 2164106496 Open_Status_of_Door_9 3437;
BA_ "SPN" SG_ 2164106496 Enable_Status_of_Door_9 3438;
BA_ "SPN" SG_ 2164106496 Lock_Status_of_Door_10 3439;
BA_ "SPN" SG_ 2164106496 Open_Status_of_Door_10 3440;
BA_ "SPN" SG_ 2164106496 Enable_Status_of_Door_10 3441;
BA_ "SPN" SG_ 2164107264 Network_Transceiver_Status_2 3442;
BA_ "SPN" SG_ 2164107264 Network_Service_Status_2 3443;
BA_ "SPN" SG_ 2164107264 Network_Antenna_Status_2 3444;
BA_ "SPN" SG_ 2164107264 Network_Signal_Strength_2 3445;
BA_ "SPN" SG_ 2164107264 Wireless_Communication_Network_T 3446;
BA_ "SystemSignalLongSymbol" SG_ 2164107264 Wireless_Communication_Network_T "Wireless Communication Network Type 2";
BA_ "SPN" SG_ 2164107520 Network_Transceiver_Status_1 3368;
BA_ "SPN" SG_ 2164107520 Network_Service_Status_1 3369;
BA_ "SPN" SG_ 2164107520 Network_Antenna_Status_1 3370;
BA_ "SPN" SG_ 2164107520 Network_Signal_Strength_1 3371;
BA_ "SPN" SG_ 2164107520 Wireless_Communication_Network_T 3372;
BA_ "SystemSignalLongSymbol" SG_ 2164107520 Wireless_Communication_Network_T "Wireless Communication Network Type 1";
BA_ "SPN" SG_ 2164107776 Engine_Charge_Air_Cooler_1_Inlet 3340;
BA_ "SystemSignalLongSymbol" SG_ 2164107776 Engine_Charge_Air_Cooler_1_Inlet "Engine Charge Air Cooler 1 Inlet Pressure";
BA_ "SPN" SG_ 2164107776 Engine_Charge_Air_Cooler_2_Inlet 3341;
BA_ "SystemSignalLongSymbol" SG_ 2164107776 Engine_Charge_Air_Cooler_2_Inlet "Engine Charge Air Cooler 2 Inlet Pressure";
BA_ "SPN" SG_ 2164107776 Engine_Coolant_Pump_Differential 3342;
BA_ "SystemSignalLongSymbol" SG_ 2164107776 Engine_Coolant_Pump_Differential "Engine Coolant Pump Differential Pressure";
BA_ "SPN" SG_ 2164107776 Engine_Centrifugal_Oil_Filter_sp 3343;
BA_ "SystemSignalLongSymbol" SG_ 2164107776 Engine_Centrifugal_Oil_Filter_sp "Engine Centrifugal Oil Filter speed";
BA_ "SPN" SG_ 2164107776 Engine_Intercooler_Coolant_Level 3668;
BA_ "SPN" SG_ 2164107776 Engine_Aftercooler_Coolant_Level 3676;
BA_ "SPN" SG_ 2164107776 Engine_Charge_Air_Cooler_Outlet_ 2631;
BA_ "SystemSignalLongSymbol" SG_ 2164107776 Engine_Charge_Air_Cooler_Outlet_ "Engine Charge Air Cooler Outlet Pressure";
BA_ "SPN" SG_ 2164108800 Fifth_Wheel_Error_Status 3307;
BA_ "SPN" SG_ 2164108800 Fifth_Wheel_Lock_Ready_to_Couple 3312;
BA_ "SystemSignalLongSymbol" SG_ 2164108800 Fifth_Wheel_Lock_Ready_to_Couple "Fifth Wheel Lock Ready to Couple Indicator";
BA_ "SPN" SG_ 2164108800 Fifth_Wheel_Lock_Couple_Status_I 3313;
BA_ "SystemSignalLongSymbol" SG_ 2164108800 Fifth_Wheel_Lock_Couple_Status_I "Fifth Wheel Lock Couple Status Indicator";
BA_ "SPN" SG_ 2164108800 Fifth_Wheel_Slider_Position 3311;
BA_ "SPN" SG_ 2164108800 Fifth_Wheel_Slider_Lock_Indicato 3316;
BA_ "SystemSignalLongSymbol" SG_ 2164108800 Fifth_Wheel_Slider_Lock_Indicato "Fifth Wheel Slider Lock Indicator";
BA_ "SPN" SG_ 2164109056 Aftertreatment_2_Exhaust_Gas_Tem0 3283;
BA_ "SystemSignalLongSymbol" SG_ 2164109056 Aftertreatment_2_Exhaust_Gas_Tem0 "Aftertreatment 2 Exhaust Gas Temperature 2";
BA_ "SPN" SG_ 2164109056 Aftertreatment_2_Diesel_Particul0 3284;
BA_ "SystemSignalLongSymbol" SG_ 2164109056 Aftertreatment_2_Diesel_Particul0 "Aftertreatment 2 Diesel Particulate Filter Intermediate Gas Temperature";
BA_ "SPN" SG_ 2164109056 Aftertreatment_2_Diesel_Particul1 3285;
BA_ "SystemSignalLongSymbol" SG_ 2164109056 Aftertreatment_2_Diesel_Particul1 "Aftertreatment 2 Diesel Particulate Filter Differential Pressure";
BA_ "SPN" SG_ 2164109056 Aftertreatment_2_Exhaust_Gas_Tem1 3286;
BA_ "SystemSignalLongSymbol" SG_ 2164109056 Aftertreatment_2_Exhaust_Gas_Tem1 "Aftertreatment 2 Exhaust Gas Temperature 2 Preliminary FMI";
BA_ "SPN" SG_ 2164109056 Aftertreatment_2_Diesel_Particul2 3287;
BA_ "SystemSignalLongSymbol" SG_ 2164109056 Aftertreatment_2_Diesel_Particul2 "Aftertreatment 2 Diesel Particulate Filter Delta Pressure Preliminary FMI";
BA_ "SPN" SG_ 2164109056 Aftertreatment_2_Diesel_Particul3 3288;
BA_ "SystemSignalLongSymbol" SG_ 2164109056 Aftertreatment_2_Diesel_Particul3 "Aftertreatment 2 Diesel Particulate Filter Intermediate Gas Temperature Preliminary FMI";
BA_ "SPN" SG_ 2164109312 Aftertreatment_2_Exhaust_Gas_Tem0 3279;
BA_ "SystemSignalLongSymbol" SG_ 2164109312 Aftertreatment_2_Exhaust_Gas_Tem0 "Aftertreatment 2 Exhaust Gas Temperature 3";
BA_ "SPN" SG_ 2164109312 Aftertreatment_2_Diesel_Particul0 3280;
BA_ "SystemSignalLongSymbol" SG_ 2164109312 Aftertreatment_2_Diesel_Particul0 "Aftertreatment 2 Diesel Particulate Filter Outlet Gas Temperature";
BA_ "SPN" SG_ 2164109312 Aftertreatment_2_Exhaust_Gas_Tem1 3281;
BA_ "SystemSignalLongSymbol" SG_ 2164109312 Aftertreatment_2_Exhaust_Gas_Tem1 "Aftertreatment 2 Exhaust Gas Temperature 3 Preliminary FMI";
BA_ "SPN" SG_ 2164109312 Aftertreatment_2_Diesel_Particul1 3282;
BA_ "SystemSignalLongSymbol" SG_ 2164109312 Aftertreatment_2_Diesel_Particul1 "Aftertreatment 2 Diesel Particulate Filter Exhaust Gas Temperature  Preliminary FMI";
BA_ "SPN" SG_ 2164109568 Aftertreatment_2_Exhaust_Gas_Tem0 3275;
BA_ "SystemSignalLongSymbol" SG_ 2164109568 Aftertreatment_2_Exhaust_Gas_Tem0 "Aftertreatment 2 Exhaust Gas Temperature 1";
BA_ "SPN" SG_ 2164109568 Aftertreatment_2_Diesel_Particul0 3276;
BA_ "SystemSignalLongSymbol" SG_ 2164109568 Aftertreatment_2_Diesel_Particul0 "Aftertreatment 2 Diesel Particulate Filter Intake Gas Temperature";
BA_ "SPN" SG_ 2164109568 Aftertreatment_2_Exhaust_Gas_Tem1 3277;
BA_ "SystemSignalLongSymbol" SG_ 2164109568 Aftertreatment_2_Exhaust_Gas_Tem1 "Aftertreatment 2 Exhaust Gas Temperature 1 Preliminary FMI";
BA_ "SPN" SG_ 2164109568 Aftertreatment_2_Diesel_Particul1 3278;
BA_ "SystemSignalLongSymbol" SG_ 2164109568 Aftertreatment_2_Diesel_Particul1 "Aftertreatment 2 Diesel Particulate Filter Intake Gas Temperature Preliminary FMI";
BA_ "SPN" SG_ 2164109824 Aftertreatment_1_Exhaust_Gas_Tem0 3249;
BA_ "SystemSignalLongSymbol" SG_ 2164109824 Aftertreatment_1_Exhaust_Gas_Tem0 "Aftertreatment 1 Exhaust Gas Temperature 2";
BA_ "SPN" SG_ 2164109824 Aftertreatment_1_Diesel_Particul0 3250;
BA_ "SystemSignalLongSymbol" SG_ 2164109824 Aftertreatment_1_Diesel_Particul0 "Aftertreatment 1 Diesel Particulate Filter Intermediate Gas Temperature";
BA_ "SPN" SG_ 2164109824 Aftertreatment_1_Diesel_Particul1 3251;
BA_ "SystemSignalLongSymbol" SG_ 2164109824 Aftertreatment_1_Diesel_Particul1 "Aftertreatment 1 Diesel Particulate Filter Differential Pressure";
BA_ "SPN" SG_ 2164109824 Aftertreatment_1_Exhaust_Gas_Tem1 3252;
BA_ "SystemSignalLongSymbol" SG_ 2164109824 Aftertreatment_1_Exhaust_Gas_Tem1 "Aftertreatment 1 Exhaust Gas Temperature 2 Preliminary FMI";
BA_ "SPN" SG_ 2164109824 Aftertreatment_1_Diesel_Particul2 3253;
BA_ "SystemSignalLongSymbol" SG_ 2164109824 Aftertreatment_1_Diesel_Particul2 "Aftertreatment 1 Diesel Particulate Filter Delta Pressure Preliminary FMI";
BA_ "SPN" SG_ 2164109824 Aftertreatment_1_Diesel_Particul3 3254;
BA_ "SystemSignalLongSymbol" SG_ 2164109824 Aftertreatment_1_Diesel_Particul3 "Aftertreatment 1 Diesel Particulate Filter Intermediate Gas Temperature Preliminary FMI";
BA_ "SPN" SG_ 2164110080 Aftertreatment_1_Exhaust_Gas_Tem0 3245;
BA_ "SystemSignalLongSymbol" SG_ 2164110080 Aftertreatment_1_Exhaust_Gas_Tem0 "Aftertreatment 1 Exhaust Gas Temperature 3";
BA_ "SPN" SG_ 2164110080 Aftertreatment_1_Diesel_Particul0 3246;
BA_ "SystemSignalLongSymbol" SG_ 2164110080 Aftertreatment_1_Diesel_Particul0 "Aftertreatment 1 Diesel Particulate Filter Outlet Gas Temperature";
BA_ "SPN" SG_ 2164110080 Aftertreatment_1_Exhaust_Gas_Tem1 3247;
BA_ "SystemSignalLongSymbol" SG_ 2164110080 Aftertreatment_1_Exhaust_Gas_Tem1 "Aftertreatment 1 Exhaust Gas Temperature 3 Preliminary FMI";
BA_ "SPN" SG_ 2164110080 Aftertreatment_1_Diesel_Particul1 3248;
BA_ "SystemSignalLongSymbol" SG_ 2164110080 Aftertreatment_1_Diesel_Particul1 "Aftertreatment 1 Diesel Particulate Filter Outlet Exhaust Gas Temperature  Preliminary FMI";
BA_ "SPN" SG_ 2164110336 Aftertreatment_1_Exhaust_Gas_Tem0 3241;
BA_ "SystemSignalLongSymbol" SG_ 2164110336 Aftertreatment_1_Exhaust_Gas_Tem0 "Aftertreatment 1 Exhaust Gas Temperature 1";
BA_ "SPN" SG_ 2164110336 Aftertreatment_1_Diesel_Particul0 3242;
BA_ "SystemSignalLongSymbol" SG_ 2164110336 Aftertreatment_1_Diesel_Particul0 "Aftertreatment 1 Diesel Particulate Filter Intake Gas Temperature";
BA_ "SPN" SG_ 2164110336 Aftertreatment_1_Exhaust_Gas_Tem1 3243;
BA_ "SystemSignalLongSymbol" SG_ 2164110336 Aftertreatment_1_Exhaust_Gas_Tem1 "Aftertreatment 1 Exhaust Gas Temperature 1 Preliminary FMI";
BA_ "SPN" SG_ 2164110336 Aftertreatment_1_Diesel_Particul1 3244;
BA_ "SystemSignalLongSymbol" SG_ 2164110336 Aftertreatment_1_Diesel_Particul1 "Aftertreatment 1 Diesel Particulate Filter Intake Gas Temperature Preliminary FMI";
BA_ "SPN" SG_ 2164111616 Tire_Location 3190;
BA_ "SPN" SG_ 2164111616 Reference_Tire_Pressure 3191;
BA_ "SPN" SG_ 2164111872 Farebox_Emergency_Status 3179;
BA_ "SPN" SG_ 2164111872 Farebox_Alarm_Identifier 3181;
BA_ "SPN" SG_ 2164112128 Transaction_Type 3170;
BA_ "SPN" SG_ 2164112128 Passenger_Type 3171;
BA_ "SPN" SG_ 2164112128 Type_of_Fare 3176;
BA_ "SPN" SG_ 2164112128 Payment_Details 3177;
BA_ "SPN" SG_ 2164112128 Fare_Validity 3165;
BA_ "SPN" SG_ 2164112128 Pass_Category 3166;
BA_ "SPN" SG_ 2164112128 Initial_Fare_Agency 3167;
BA_ "SPN" SG_ 2164112128 Type_of_Service 3172;
BA_ "SPN" SG_ 2164112128 Transfer_Type 3173;
BA_ "SPN" SG_ 2164112128 Route_Number 3169;
BA_ "SPN" SG_ 2164112128 Transfer_Sold 3168;
BA_ "SPN" SG_ 2164112384 Farebox_Service_Status 3178;
BA_ "SPN" SG_ 2164112384 Trip_Status 3180;
BA_ "SPN" SG_ 2164112384 Trip_Direction 3174;
BA_ "SPN" SG_ 2164112384 Fare_Presets 3175;
BA_ "SPN" SG_ 2164112384 Trip_Number 3159;
BA_ "SPN" SG_ 2164112384 Pattern_Number_ 3161;
BA_ "SPN" SG_ 2164112384 Assigned_Route 3160;
BA_ "SPN" SG_ 2164112384 Assigned_Run 3162;
BA_ "SPN" SG_ 2164112384 Assigned_Block 3163;
BA_ "SPN" SG_ 2164112384 Driver_s_farebox_security_code 3164;
BA_ "SPN" SG_ 2164112640 Range_Code_Enable 3081;
BA_ "SPN" SG_ 2164112640 Transit_Route_ID_Usage 3080;
BA_ "SPN" SG_ 2164112640 Intersection_Preemption_Request_ 3079;
BA_ "SystemSignalLongSymbol" SG_ 2164112640 Intersection_Preemption_Request_ "Intersection Preemption Request/Response";
BA_ "SPN" SG_ 2164112640 Priority_of_Response_Sent_by_Emi 3084;
BA_ "SystemSignalLongSymbol" SG_ 2164112640 Priority_of_Response_Sent_by_Emi "Priority of Response Sent by Emitter";
BA_ "SPN" SG_ 2164112640 Transit_Door_Enable 3083;
BA_ "SPN" SG_ 2164112640 Strobe_Activation_Control_Status 3082;
BA_ "SPN" SG_ 2164112640 Vehicle_ID 3085;
BA_ "SPN" SG_ 2164112896 Agency 3078;
BA_ "SPN" SG_ 2164112896 Number_of_bytes_in_the_Transit_A0 3071;
BA_ "SystemSignalLongSymbol" SG_ 2164112896 Number_of_bytes_in_the_Transit_A0 "Number of bytes in the Transit Assigned Route Identity";
BA_ "SPN" SG_ 2164112896 Number_of_bytes_in_the_Transit_A1 3072;
BA_ "SystemSignalLongSymbol" SG_ 2164112896 Number_of_bytes_in_the_Transit_A1 "Number of bytes in the Transit Assigned Run Identity";
BA_ "SPN" SG_ 2164112896 Number_of_bytes_in_the_Transit_A2 3073;
BA_ "SystemSignalLongSymbol" SG_ 2164112896 Number_of_bytes_in_the_Transit_A2 "Number of bytes in the Transit Assigned Block Identity";
BA_ "SPN" SG_ 2164112896 Transit_Assigned_Route_Identity 3074;
BA_ "SPN" SG_ 2164112896 Transit_Assigned_Run_Identity 3075;
BA_ "SPN" SG_ 2164112896 Transit_Assigned_Block_Identity 3076;
BA_ "SPN" SG_ 2164113152 Number_of_bytes_in_the_Milepost_ 3070;
BA_ "SystemSignalLongSymbol" SG_ 2164113152 Number_of_bytes_in_the_Milepost_ "Number of bytes in the Milepost Identification";
BA_ "SPN" SG_ 2164113152 Milepost_Identification 509;
BA_ "SPN" SG_ 2164113408 Type_of_Passenger_Count 3043;
BA_ "SPN" SG_ 2164113408 Patron_Count 3047;
BA_ "SPN" SG_ 2164113408 Silent_Alarm_Status 3044;
BA_ "SPN" SG_ 2164113408 Vehicle_Use_Status 3045;
BA_ "SPN" SG_ 2164113408 Transit_Run_Status 3046;
BA_ "SPN" SG_ 2164113664 Engine_Intake_Valve_Actuation_Sy 2948;
BA_ "SystemSignalLongSymbol" SG_ 2164113664 Engine_Intake_Valve_Actuation_Sy "Engine Intake Valve Actuation System Oil Pressure";
BA_ "SPN" SG_ 2164113664 Engine_Exhaust_Gas_Recirculation 3358;
BA_ "SystemSignalLongSymbol" SG_ 2164113664 Engine_Exhaust_Gas_Recirculation "Engine Exhaust Gas Recirculation Inlet Pressure";
BA_ "SPN" SG_ 2164113664 Engine_Exhaust_Valve_Actuation_S 4287;
BA_ "SystemSignalLongSymbol" SG_ 2164113664 Engine_Exhaust_Valve_Actuation_S "Engine Exhaust Valve Actuation System Oil Pressure";
BA_ "SPN" SG_ 2164114432 Brake_Temperature_Warning 3839;
BA_ "SPN" SG_ 2164114432 Halt_brake_mode 2913;
BA_ "SPN" SG_ 2164114432 Hill_holder_mode 2912;
BA_ "SPN" SG_ 2164114432 Foundation_Brake_Use 2919;
BA_ "SPN" SG_ 2164114432 XBR_System_State 2917;
BA_ "SPN" SG_ 2164114432 XBR_Active_Control_Mode 2918;
BA_ "SPN" SG_ 2164114432 XBR_Acceleration_Limit 2921;
BA_ "SPN" SG_ 2164114688 ECU_Part_Number 2901;
BA_ "SPN" SG_ 2164114688 ECU_Serial_Number 2902;
BA_ "SPN" SG_ 2164114688 ECU_Location 2903;
BA_ "SPN" SG_ 2164114688 ECU_Type 2904;
BA_ "SPN" SG_ 2164114688 ECU_Manufacturer_Name 4304;
BA_ "SPN" SG_ 2164114944 Engine_Start_Enable_Device_1 626;
BA_ "SPN" SG_ 2164114944 Engine_Start_Enable_Device_2 1804;
BA_ "SPN" SG_ 2164114944 Engine_Start_Enable_Device_1_Con 2899;
BA_ "SystemSignalLongSymbol" SG_ 2164114944 Engine_Start_Enable_Device_1_Con "Engine Start Enable Device 1 Configuration";
BA_ "SPN" SG_ 2164114944 Engine_Start_Enable_Device_2_Con 2898;
BA_ "SystemSignalLongSymbol" SG_ 2164114944 Engine_Start_Enable_Device_2_Con "Engine Start Enable Device 2 Configuration";
BA_ "SPN" SG_ 2164115200 Engine_Auxiliary_Governor_State 2896;
BA_ "SPN" SG_ 2164115200 Engine_Multi_Unit_Sync_State 2890;
BA_ "SPN" SG_ 2164115200 Engine_Alternate_Low_Idle_Select 2891;
BA_ "SystemSignalLongSymbol" SG_ 2164115200 Engine_Alternate_Low_Idle_Select "Engine Alternate Low Idle Select State";
BA_ "SPN" SG_ 2164115200 Engine_Alternate_Rating_Select_S 2888;
BA_ "SystemSignalLongSymbol" SG_ 2164115200 Engine_Alternate_Rating_Select_S "Engine Alternate Rating Select State";
BA_ "SPN" SG_ 2164115200 Engine_Alternate_Droop_Accelerat0 2889;
BA_ "SystemSignalLongSymbol" SG_ 2164115200 Engine_Alternate_Droop_Accelerat0 "Engine Alternate Droop Accelerator 1 Select State";
BA_ "SPN" SG_ 2164115200 Engine_Alternate_Droop_Accelerat1 2893;
BA_ "SystemSignalLongSymbol" SG_ 2164115200 Engine_Alternate_Droop_Accelerat1 "Engine Alternate Droop Accelerator 2 Select State";
BA_ "SPN" SG_ 2164115200 Engine_Alternate_Droop_Remote_Ac 2894;
BA_ "SystemSignalLongSymbol" SG_ 2164115200 Engine_Alternate_Droop_Remote_Ac "Engine Alternate Droop Remote Accelerator Select State";
BA_ "SPN" SG_ 2164115200 Engine_Alternate_Droop_Auxiliary 2895;
BA_ "SystemSignalLongSymbol" SG_ 2164115200 Engine_Alternate_Droop_Auxiliary "Engine Alternate Droop Auxiliary Input Select State";
BA_ "SPN" SG_ 2164115456 Engine_Operator_Primary_Intermed 2892;
BA_ "SystemSignalLongSymbol" SG_ 2164115456 Engine_Operator_Primary_Intermed "Engine Operator Primary Intermediate Speed Select State";
BA_ "SPN" SG_ 2164115712 Total_Count_of_Configuration_Cha 2887;
BA_ "SystemSignalLongSymbol" SG_ 2164115712 Total_Count_of_Configuration_Cha "Total Count of Configuration Changes Made";
BA_ "SPN" SG_ 2164115968 Engine_Operator_Primary_Intermed 2880;
BA_ "SystemSignalLongSymbol" SG_ 2164115968 Engine_Operator_Primary_Intermed "Engine Operator Primary Intermediate Speed Select";
BA_ "SPN" SG_ 2164116224 Engine_Auxiliary_Governor_Switch 2884;
BA_ "SPN" SG_ 2164116224 Engine_Synchronization_Switch 1377;
BA_ "SPN" SG_ 2164116224 Engine_Alternate_Low_Idle_Switch 2883;
BA_ "SPN" SG_ 2164116224 Engine_Alternate_Rating_Select 2882;
BA_ "SPN" SG_ 2164116224 Engine_Alternate_Droop_Accelerat0 2881;
BA_ "SystemSignalLongSymbol" SG_ 2164116224 Engine_Alternate_Droop_Accelerat0 "Engine Alternate Droop Accelerator 1 Select";
BA_ "SPN" SG_ 2164116224 Engine_Alternate_Droop_Accelerat1 2879;
BA_ "SystemSignalLongSymbol" SG_ 2164116224 Engine_Alternate_Droop_Accelerat1 "Engine Alternate Droop Accelerator 2 Select";
BA_ "SPN" SG_ 2164116224 Engine_Alternate_Droop_Remote_Ac 2886;
BA_ "SystemSignalLongSymbol" SG_ 2164116224 Engine_Alternate_Droop_Remote_Ac "Engine Alternate Droop Remote Accelerator Select";
BA_ "SPN" SG_ 2164116224 Engine_Alternate_Droop_Auxiliary 2885;
BA_ "SystemSignalLongSymbol" SG_ 2164116224 Engine_Alternate_Droop_Auxiliary "Engine Alternate Droop Auxiliary Input Select";
BA_ "SPN" SG_ 2164116480 Work_Light_Switch 2873;
BA_ "SPN" SG_ 2164116480 Main_Light_Switch 2872;
BA_ "SPN" SG_ 2164116480 Turn_Signal_Switch 2876;
BA_ "SPN" SG_ 2164116480 Hazard_Light_Switch 2875;
BA_ "SPN" SG_ 2164116480 High_Low_Beam_Switch 2874;
BA_ "SPN" SG_ 2164116480 Operators_Desired_Back_light 2878;
BA_ "SPN" SG_ 2164116480 Operators_Desired___Delayed_Lamp 2877;
BA_ "SystemSignalLongSymbol" SG_ 2164116480 Operators_Desired___Delayed_Lamp "Operators Desired - Delayed Lamp Off Time";
BA_ "SPN" SG_ 2164116736 Front_Non_operator_Wiper_Switch 2864;
BA_ "SPN" SG_ 2164116736 Front_Operator_Wiper_Switch 2863;
BA_ "SPN" SG_ 2164116736 Rear_Wiper_Switch 2865;
BA_ "SPN" SG_ 2164116736 Front_Operator_Wiper_Delay_Contr 2869;
BA_ "SystemSignalLongSymbol" SG_ 2164116736 Front_Operator_Wiper_Delay_Contr "Front Operator Wiper Delay Control";
BA_ "SPN" SG_ 2164116736 Front_Non_operator_Wiper_Delay_C 2870;
BA_ "SystemSignalLongSymbol" SG_ 2164116736 Front_Non_operator_Wiper_Delay_C "Front Non-operator Wiper Delay Control";
BA_ "SPN" SG_ 2164116736 Rear_Wiper_Delay_Control 2871;
BA_ "SPN" SG_ 2164116736 Front_Non_operator_Washer_Switch 2867;
BA_ "SPN" SG_ 2164116736 Front_Operator_Washer_Switch 2866;
BA_ "SPN" SG_ 2164116736 Rear_Washer_Function 2868;
BA_ "SPN" SG_ 2164117504 Engine_Air_Filter_2_Differential 2809;
BA_ "SystemSignalLongSymbol" SG_ 2164117504 Engine_Air_Filter_2_Differential "Engine Air Filter 2 Differential Pressure";
BA_ "SPN" SG_ 2164117504 Engine_Air_Filter_3_Differential 2810;
BA_ "SystemSignalLongSymbol" SG_ 2164117504 Engine_Air_Filter_3_Differential "Engine Air Filter 3 Differential Pressure";
BA_ "SPN" SG_ 2164117504 Engine_Air_Filter_4_Differential 2811;
BA_ "SystemSignalLongSymbol" SG_ 2164117504 Engine_Air_Filter_4_Differential "Engine Air Filter 4 Differential Pressure";
BA_ "SPN" SG_ 2164117504 Engine_Intake_Manifold__2_Pressu 3562;
BA_ "SystemSignalLongSymbol" SG_ 2164117504 Engine_Intake_Manifold__2_Pressu "Engine Intake Manifold #2 Pressure";
BA_ "SPN" SG_ 2164117504 Engine_Intake_Manifold__1_Absolu 3563;
BA_ "SystemSignalLongSymbol" SG_ 2164117504 Engine_Intake_Manifold__1_Absolu "Engine Intake Manifold #1 Absolute Pressure";
BA_ "SPN" SG_ 2164117760 FMS_standard_Diagnostics_Support 2804;
BA_ "SystemSignalLongSymbol" SG_ 2164117760 FMS_standard_Diagnostics_Support "FMS-standard Diagnostics Supported";
BA_ "SPN" SG_ 2164117760 FMS_standard_Requests_Supported 2805;
BA_ "SPN" SG_ 2164117760 FMS_standard_SW_version_supporte 2806;
BA_ "SystemSignalLongSymbol" SG_ 2164117760 FMS_standard_SW_version_supporte "FMS-standard SW-version supported.";
BA_ "SPN" SG_ 2164118016 Keep_Alive_Battery_Consumption 2803;
BA_ "SPN" SG_ 2164118016 Data_Memory_Usage 2802;
BA_ "SPN" SG_ 2164118272 Engine_Turbocharger_1_Compressor 2629;
BA_ "SystemSignalLongSymbol" SG_ 2164118272 Engine_Turbocharger_1_Compressor "Engine Turbocharger 1 Compressor Outlet Temperature";
BA_ "SPN" SG_ 2164118272 Engine_Turbocharger_2_Compressor 2799;
BA_ "SystemSignalLongSymbol" SG_ 2164118272 Engine_Turbocharger_2_Compressor "Engine Turbocharger 2 Compressor Outlet Temperature";
BA_ "SPN" SG_ 2164118272 Engine_Turbocharger_3_Compressor 2800;
BA_ "SystemSignalLongSymbol" SG_ 2164118272 Engine_Turbocharger_3_Compressor "Engine Turbocharger 3 Compressor Outlet Temperature";
BA_ "SPN" SG_ 2164118272 Engine_Turbocharger_4_Compressor 2801;
BA_ "SystemSignalLongSymbol" SG_ 2164118272 Engine_Turbocharger_4_Compressor "Engine Turbocharger 4 Compressor Outlet Temperature";
BA_ "SPN" SG_ 2164118528 Transfer_Case_Selector_Switch 2796;
BA_ "SPN" SG_ 2164118528 Fifth_Wheel_Release_Control 3314;
BA_ "SPN" SG_ 2164118528 Fifth_Wheel_Release_Control_Secu 3315;
BA_ "SystemSignalLongSymbol" SG_ 2164118528 Fifth_Wheel_Release_Control_Secu "Fifth Wheel Release Control Security Lockout";
BA_ "SPN" SG_ 2164118528 Transmission_Oil_Level_Request 3809;
BA_ "SPN" SG_ 2164118784 Engine_Turbocharger_1_Calculated0 2789;
BA_ "SystemSignalLongSymbol" SG_ 2164118784 Engine_Turbocharger_1_Calculated0 "Engine Turbocharger 1 Calculated Turbine Inlet Temperature";
BA_ "SPN" SG_ 2164118784 Engine_Turbocharger_1_Calculated1 2790;
BA_ "SystemSignalLongSymbol" SG_ 2164118784 Engine_Turbocharger_1_Calculated1 "Engine Turbocharger 1 Calculated Turbine Outlet Temperature";
BA_ "SPN" SG_ 2164118784 Engine_Exhaust_Gas_Recirculation 2791;
BA_ "SystemSignalLongSymbol" SG_ 2164118784 Engine_Exhaust_Gas_Recirculation "Engine Exhaust Gas Recirculation (EGR) Valve Control";
BA_ "SPN" SG_ 2164118784 Engine_Variable_Geometry_Turboch0 2792;
BA_ "SystemSignalLongSymbol" SG_ 2164118784 Engine_Variable_Geometry_Turboch0 "Engine Variable Geometry Turbocharger (VGT) Air Control Shutoff Valve";
BA_ "SPN" SG_ 2164118784 Engine_Variable_Geometry_Turboch1 2795;
BA_ "SystemSignalLongSymbol" SG_ 2164118784 Engine_Variable_Geometry_Turboch1 "Engine Variable Geometry Turbocharger (VGT) 1 Actuator Position";
BA_ "SPN" SG_ 2164119040 Joystick_1_X_Axis_Neutral_Positi 2675;
BA_ "SystemSignalLongSymbol" SG_ 2164119040 Joystick_1_X_Axis_Neutral_Positi "Joystick 1 X-Axis Neutral Position Status";
BA_ "SPN" SG_ 2164119040 Joystick_1_X_Axis_Lever_Left_Neg 2670;
BA_ "SystemSignalLongSymbol" SG_ 2164119040 Joystick_1_X_Axis_Lever_Left_Neg "Joystick 1 X-Axis Lever Left Negative Position Status";
BA_ "SPN" SG_ 2164119040 Joystick_1_X_Axis_Lever_Right_Po 2665;
BA_ "SystemSignalLongSymbol" SG_ 2164119040 Joystick_1_X_Axis_Lever_Right_Po "Joystick 1 X-Axis Lever Right Positive Position Status";
BA_ "SPN" SG_ 2164119040 Joystick_1_X_Axis_Position 2660;
BA_ "SPN" SG_ 2164119040 Joystick_1_Y_Axis_Neutral_Positi 2676;
BA_ "SystemSignalLongSymbol" SG_ 2164119040 Joystick_1_Y_Axis_Neutral_Positi "Joystick 1 Y-Axis Neutral Position Status";
BA_ "SPN" SG_ 2164119040 Joystick_1_Y_Axis_Lever_Back_Neg 2671;
BA_ "SystemSignalLongSymbol" SG_ 2164119040 Joystick_1_Y_Axis_Lever_Back_Neg "Joystick 1 Y-Axis Lever Back Negative Position Status";
BA_ "SPN" SG_ 2164119040 Joystick_1_Y_Axis_Lever_Forward_ 2666;
BA_ "SystemSignalLongSymbol" SG_ 2164119040 Joystick_1_Y_Axis_Lever_Forward_ "Joystick 1 Y-Axis Lever Forward Positive Position Status";
BA_ "SPN" SG_ 2164119040 Joystick_1_Y_Axis_Position 2661;
BA_ "SPN" SG_ 2164119040 Joystick_1_Y_Axis_Detent_Positio 2681;
BA_ "SystemSignalLongSymbol" SG_ 2164119040 Joystick_1_Y_Axis_Detent_Positio "Joystick 1 Y-Axis Detent Position Status";
BA_ "SPN" SG_ 2164119040 Joystick_1_X_Axis_Detent_Positio 2680;
BA_ "SystemSignalLongSymbol" SG_ 2164119040 Joystick_1_X_Axis_Detent_Positio "Joystick 1 X-Axis Detent Position Status";
BA_ "SPN" SG_ 2164119040 Joystick_1_Button_4_Pressed_Stat 2688;
BA_ "SystemSignalLongSymbol" SG_ 2164119040 Joystick_1_Button_4_Pressed_Stat "Joystick 1 Button 4 Pressed Status";
BA_ "SPN" SG_ 2164119040 Joystick_1_Button_3_Pressed_Stat 2687;
BA_ "SystemSignalLongSymbol" SG_ 2164119040 Joystick_1_Button_3_Pressed_Stat "Joystick 1 Button 3 Pressed Status";
BA_ "SPN" SG_ 2164119040 Joystick_1_Button_2_Pressed_Stat 2686;
BA_ "SystemSignalLongSymbol" SG_ 2164119040 Joystick_1_Button_2_Pressed_Stat "Joystick 1 Button 2 Pressed Status";
BA_ "SPN" SG_ 2164119040 Joystick_1_Button_1_Pressed_Stat 2685;
BA_ "SystemSignalLongSymbol" SG_ 2164119040 Joystick_1_Button_1_Pressed_Stat "Joystick 1 Button 1 Pressed Status";
BA_ "SPN" SG_ 2164119040 Joystick_1_Button_8_Pressed_Stat 2692;
BA_ "SystemSignalLongSymbol" SG_ 2164119040 Joystick_1_Button_8_Pressed_Stat "Joystick 1 Button 8 Pressed Status";
BA_ "SPN" SG_ 2164119040 Joystick_1_Button_7_Pressed_Stat 2691;
BA_ "SystemSignalLongSymbol" SG_ 2164119040 Joystick_1_Button_7_Pressed_Stat "Joystick 1 Button 7 Pressed Status";
BA_ "SPN" SG_ 2164119040 Joystick_1_Button_6_Pressed_Stat 2690;
BA_ "SystemSignalLongSymbol" SG_ 2164119040 Joystick_1_Button_6_Pressed_Stat "Joystick 1 Button 6 Pressed Status";
BA_ "SPN" SG_ 2164119040 Joystick_1_Button_5_Pressed_Stat 2689;
BA_ "SystemSignalLongSymbol" SG_ 2164119040 Joystick_1_Button_5_Pressed_Stat "Joystick 1 Button 5 Pressed Status";
BA_ "SPN" SG_ 2164119040 Joystick_1_Button_12_Pressed_Sta 2696;
BA_ "SystemSignalLongSymbol" SG_ 2164119040 Joystick_1_Button_12_Pressed_Sta "Joystick 1 Button 12 Pressed Status";
BA_ "SPN" SG_ 2164119040 Joystick_1_Button_11_Pressed_Sta 2695;
BA_ "SystemSignalLongSymbol" SG_ 2164119040 Joystick_1_Button_11_Pressed_Sta "Joystick 1 Button 11 Pressed Status";
BA_ "SPN" SG_ 2164119040 Joystick_1_Button_10_Pressed_Sta 2694;
BA_ "SystemSignalLongSymbol" SG_ 2164119040 Joystick_1_Button_10_Pressed_Sta "Joystick 1 Button 10 Pressed Status";
BA_ "SPN" SG_ 2164119040 Joystick_1_Button_9_Pressed_Stat 2693;
BA_ "SystemSignalLongSymbol" SG_ 2164119040 Joystick_1_Button_9_Pressed_Stat "Joystick 1 Button 9 Pressed Status";
BA_ "SPN" SG_ 2164119296 Joystick_1_Grip_X_Axis_Neutral_P 2677;
BA_ "SystemSignalLongSymbol" SG_ 2164119296 Joystick_1_Grip_X_Axis_Neutral_P "Joystick 1 Grip X-Axis Neutral Position Status";
BA_ "SPN" SG_ 2164119296 Joystick_1_Grip_X_Axis_Lever_Lef 2672;
BA_ "SystemSignalLongSymbol" SG_ 2164119296 Joystick_1_Grip_X_Axis_Lever_Lef "Joystick 1 Grip X-Axis Lever Left Negative Position Status";
BA_ "SPN" SG_ 2164119296 Joystick_1_Grip_X_Axis_Lever_Rig 2667;
BA_ "SystemSignalLongSymbol" SG_ 2164119296 Joystick_1_Grip_X_Axis_Lever_Rig "Joystick 1 Grip X-Axis Lever Right Positive Position Status";
BA_ "SPN" SG_ 2164119296 Joystick_1_Grip_X_Axis_Position 2662;
BA_ "SPN" SG_ 2164119296 Joystick_1_Grip_Y_Axis_Neutral_P 2678;
BA_ "SystemSignalLongSymbol" SG_ 2164119296 Joystick_1_Grip_Y_Axis_Neutral_P "Joystick 1 Grip Y-Axis Neutral Position Status";
BA_ "SPN" SG_ 2164119296 Joystick_1_Grip_Y_Axis_Lever_Bac 2673;
BA_ "SystemSignalLongSymbol" SG_ 2164119296 Joystick_1_Grip_Y_Axis_Lever_Bac "Joystick 1 Grip Y-Axis Lever Back Negative Position Status";
BA_ "SPN" SG_ 2164119296 Joystick_1_Grip_Y_Axis_Lever_For 2668;
BA_ "SystemSignalLongSymbol" SG_ 2164119296 Joystick_1_Grip_Y_Axis_Lever_For "Joystick 1 Grip Y-Axis Lever Forward Positive Position Status";
BA_ "SPN" SG_ 2164119296 Joystick_1_Grip_Y_Axis_Position 2663;
BA_ "SPN" SG_ 2164119296 Joystick_1_Theta_Axis_Neutral_Po 2679;
BA_ "SystemSignalLongSymbol" SG_ 2164119296 Joystick_1_Theta_Axis_Neutral_Po "Joystick 1 Theta-Axis Neutral Position Status";
BA_ "SPN" SG_ 2164119296 Joystick_1_Theta_Axis_Counter_Cl 2674;
BA_ "SystemSignalLongSymbol" SG_ 2164119296 Joystick_1_Theta_Axis_Counter_Cl "Joystick 1 Theta-Axis Counter Clockwise Negative Position Status";
BA_ "SPN" SG_ 2164119296 Joystick_1_Theta_Axis_Clockwise_ 2669;
BA_ "SystemSignalLongSymbol" SG_ 2164119296 Joystick_1_Theta_Axis_Clockwise_ "Joystick 1 Theta-Axis Clockwise Positive Position Status";
BA_ "SPN" SG_ 2164119296 Joystick_1_Theta_Axis_Position 2664;
BA_ "SPN" SG_ 2164119296 Joystick_1_Theta_Axis_Detent_Pos 2684;
BA_ "SystemSignalLongSymbol" SG_ 2164119296 Joystick_1_Theta_Axis_Detent_Pos "Joystick 1 Theta-Axis Detent Position Status";
BA_ "SPN" SG_ 2164119296 Joystick_1_Grip_Y_Axis_Detent_Po 2683;
BA_ "SystemSignalLongSymbol" SG_ 2164119296 Joystick_1_Grip_Y_Axis_Detent_Po "Joystick 1 Grip Y-Axis Detent Position Status";
BA_ "SPN" SG_ 2164119296 Joystick_1_Grip_X_Axis_Detent_Po 2682;
BA_ "SystemSignalLongSymbol" SG_ 2164119296 Joystick_1_Grip_X_Axis_Detent_Po "Joystick 1 Grip X-Axis Detent Position Status";
BA_ "SPN" SG_ 2164119552 Joystick_2_X_Axis_Neutral_Positi 2712;
BA_ "SystemSignalLongSymbol" SG_ 2164119552 Joystick_2_X_Axis_Neutral_Positi "Joystick 2 X-Axis Neutral Position Status";
BA_ "SPN" SG_ 2164119552 Joystick_2_X_Axis_Lever_Left_Neg 2707;
BA_ "SystemSignalLongSymbol" SG_ 2164119552 Joystick_2_X_Axis_Lever_Left_Neg "Joystick 2 X-Axis Lever Left Negative Position Status";
BA_ "SPN" SG_ 2164119552 Joystick_2_X_Axis_Lever_Right_Po 2702;
BA_ "SystemSignalLongSymbol" SG_ 2164119552 Joystick_2_X_Axis_Lever_Right_Po "Joystick 2 X-Axis Lever Right Positive Position Status";
BA_ "SPN" SG_ 2164119552 Joystick_2_X_Axis_Position 2697;
BA_ "SPN" SG_ 2164119552 Joystick_2_Y_Axis_Neutral_Positi 2713;
BA_ "SystemSignalLongSymbol" SG_ 2164119552 Joystick_2_Y_Axis_Neutral_Positi "Joystick 2 Y-Axis Neutral Position Status";
BA_ "SPN" SG_ 2164119552 Joystick_2_Y_Axis_Lever_Back_Neg 2708;
BA_ "SystemSignalLongSymbol" SG_ 2164119552 Joystick_2_Y_Axis_Lever_Back_Neg "Joystick 2 Y-Axis Lever Back Negative Position Status";
BA_ "SPN" SG_ 2164119552 Joystick_2_Y_Axis_Lever_Forward_ 2703;
BA_ "SystemSignalLongSymbol" SG_ 2164119552 Joystick_2_Y_Axis_Lever_Forward_ "Joystick 2 Y-Axis Lever Forward Positive Position Status";
BA_ "SPN" SG_ 2164119552 Joystick_2_Y_Axis_Position 2698;
BA_ "SPN" SG_ 2164119552 Joystick_2_Y_Axis_Detent_Positio 2718;
BA_ "SystemSignalLongSymbol" SG_ 2164119552 Joystick_2_Y_Axis_Detent_Positio "Joystick 2 Y-Axis Detent Position Status";
BA_ "SPN" SG_ 2164119552 Joystick_2_X_Axis_Detent_Positio 2717;
BA_ "SystemSignalLongSymbol" SG_ 2164119552 Joystick_2_X_Axis_Detent_Positio "Joystick 2 X-Axis Detent Position Status";
BA_ "SPN" SG_ 2164119552 Joystick_2_Button_4_Pressed_Stat 2725;
BA_ "SystemSignalLongSymbol" SG_ 2164119552 Joystick_2_Button_4_Pressed_Stat "Joystick 2 Button 4 Pressed Status";
BA_ "SPN" SG_ 2164119552 Joystick_2_Button_3_Pressed_Stat 2724;
BA_ "SystemSignalLongSymbol" SG_ 2164119552 Joystick_2_Button_3_Pressed_Stat "Joystick 2 Button 3 Pressed Status";
BA_ "SPN" SG_ 2164119552 Joystick_2_Button_2_Pressed_Stat 2723;
BA_ "SystemSignalLongSymbol" SG_ 2164119552 Joystick_2_Button_2_Pressed_Stat "Joystick 2 Button 2 Pressed Status";
BA_ "SPN" SG_ 2164119552 Joystick_2_Button_1_Pressed_Stat 2722;
BA_ "SystemSignalLongSymbol" SG_ 2164119552 Joystick_2_Button_1_Pressed_Stat "Joystick 2 Button 1 Pressed Status";
BA_ "SPN" SG_ 2164119552 Joystick_2_Button_8_Pressed_Stat 2729;
BA_ "SystemSignalLongSymbol" SG_ 2164119552 Joystick_2_Button_8_Pressed_Stat "Joystick 2 Button 8 Pressed Status";
BA_ "SPN" SG_ 2164119552 Joystick_2_Button_7_Pressed_Stat 2728;
BA_ "SystemSignalLongSymbol" SG_ 2164119552 Joystick_2_Button_7_Pressed_Stat "Joystick 2 Button 7 Pressed Status";
BA_ "SPN" SG_ 2164119552 Joystick_2_Button_6_Pressed_Stat 2727;
BA_ "SystemSignalLongSymbol" SG_ 2164119552 Joystick_2_Button_6_Pressed_Stat "Joystick 2 Button 6 Pressed Status";
BA_ "SPN" SG_ 2164119552 Joystick_2_Button_5_Pressed_Stat 2726;
BA_ "SystemSignalLongSymbol" SG_ 2164119552 Joystick_2_Button_5_Pressed_Stat "Joystick 2 Button 5 Pressed Status";
BA_ "SPN" SG_ 2164119552 Joystick_2_Button_12_Pressed_Sta 2733;
BA_ "SystemSignalLongSymbol" SG_ 2164119552 Joystick_2_Button_12_Pressed_Sta "Joystick 2 Button 12 Pressed Status";
BA_ "SPN" SG_ 2164119552 Joystick_2_Button_11_Pressed_Sta 2732;
BA_ "SystemSignalLongSymbol" SG_ 2164119552 Joystick_2_Button_11_Pressed_Sta "Joystick 2 Button 11 Pressed Status";
BA_ "SPN" SG_ 2164119552 Joystick_2_Button_10_Pressed_Sta 2731;
BA_ "SystemSignalLongSymbol" SG_ 2164119552 Joystick_2_Button_10_Pressed_Sta "Joystick 2 Button 10 Pressed Status";
BA_ "SPN" SG_ 2164119552 Joystick_2_Button_9_Pressed_Stat 2730;
BA_ "SystemSignalLongSymbol" SG_ 2164119552 Joystick_2_Button_9_Pressed_Stat "Joystick 2 Button 9 Pressed Status";
BA_ "SPN" SG_ 2164119808 Joystick_2_Grip_X_Axis_Neutral_P 2714;
BA_ "SystemSignalLongSymbol" SG_ 2164119808 Joystick_2_Grip_X_Axis_Neutral_P "Joystick 2 Grip X-Axis Neutral Position Status";
BA_ "SPN" SG_ 2164119808 Joystick_2_Grip_X_Axis_Lever_Lef 2709;
BA_ "SystemSignalLongSymbol" SG_ 2164119808 Joystick_2_Grip_X_Axis_Lever_Lef "Joystick 2 Grip X-Axis Lever Left Negative Position Status";
BA_ "SPN" SG_ 2164119808 Joystick_2_Grip_X_Axis_Lever_Rig 2704;
BA_ "SystemSignalLongSymbol" SG_ 2164119808 Joystick_2_Grip_X_Axis_Lever_Rig "Joystick 2 Grip X-Axis Lever Right Positive Position Status";
BA_ "SPN" SG_ 2164119808 Joystick_2_Grip_X_Axis_Position 2699;
BA_ "SPN" SG_ 2164119808 Joystick_2_Grip_Y_Axis_Neutral_P 2715;
BA_ "SystemSignalLongSymbol" SG_ 2164119808 Joystick_2_Grip_Y_Axis_Neutral_P "Joystick 2 Grip Y-Axis Neutral Position Status";
BA_ "SPN" SG_ 2164119808 Joystick_2_Grip_Y_Axis_Lever_Bac 2710;
BA_ "SystemSignalLongSymbol" SG_ 2164119808 Joystick_2_Grip_Y_Axis_Lever_Bac "Joystick 2 Grip Y-Axis Lever Back Negative Position Status";
BA_ "SPN" SG_ 2164119808 Joystick_2_Grip_Y_Axis_Lever_For 2705;
BA_ "SystemSignalLongSymbol" SG_ 2164119808 Joystick_2_Grip_Y_Axis_Lever_For "Joystick 2 Grip Y-Axis Lever Forward Positive Position Status";
BA_ "SPN" SG_ 2164119808 Joystick_2_Grip_Y_Axis_Position 2700;
BA_ "SPN" SG_ 2164119808 Joystick_2_Theta_Axis_Neutral_Po 2716;
BA_ "SystemSignalLongSymbol" SG_ 2164119808 Joystick_2_Theta_Axis_Neutral_Po "Joystick 2 Theta-Axis Neutral Position Status";
BA_ "SPN" SG_ 2164119808 Joystick_2_Theta_Axis_Counter_Cl 2711;
BA_ "SystemSignalLongSymbol" SG_ 2164119808 Joystick_2_Theta_Axis_Counter_Cl "Joystick 2 Theta-Axis Counter Clockwise Negative Position Status";
BA_ "SPN" SG_ 2164119808 Joystick_2_Theta_Axis_Clockwise_ 2706;
BA_ "SystemSignalLongSymbol" SG_ 2164119808 Joystick_2_Theta_Axis_Clockwise_ "Joystick 2 Theta-Axis Clockwise Positive Position Status";
BA_ "SPN" SG_ 2164119808 Joystick_2_Theta_Axis_Position 2701;
BA_ "SPN" SG_ 2164119808 Joystick_2_Theta_Axis_Detent_Pos 2721;
BA_ "SystemSignalLongSymbol" SG_ 2164119808 Joystick_2_Theta_Axis_Detent_Pos "Joystick 2 Theta-Axis Detent Position Status";
BA_ "SPN" SG_ 2164119808 Joystick_2_Grip_Y_Axis_Detent_Po 2720;
BA_ "SystemSignalLongSymbol" SG_ 2164119808 Joystick_2_Grip_Y_Axis_Detent_Po "Joystick 2 Grip Y-Axis Detent Position Status";
BA_ "SPN" SG_ 2164119808 Joystick_2_Grip_X_Axis_Detent_Po 2719;
BA_ "SystemSignalLongSymbol" SG_ 2164119808 Joystick_2_Grip_X_Axis_Detent_Po "Joystick 2 Grip X-Axis Detent Position Status";
BA_ "SPN" SG_ 2164120064 Joystick_3_X_Axis_Neutral_Positi 2749;
BA_ "SystemSignalLongSymbol" SG_ 2164120064 Joystick_3_X_Axis_Neutral_Positi "Joystick 3 X-Axis Neutral Position Status";
BA_ "SPN" SG_ 2164120064 Joystick_3_X_Axis_Lever_Left_Neg 2744;
BA_ "SystemSignalLongSymbol" SG_ 2164120064 Joystick_3_X_Axis_Lever_Left_Neg "Joystick 3 X-Axis Lever Left Negative Position Status";
BA_ "SPN" SG_ 2164120064 Joystick_3_X_Axis_Lever_Right_Po 2739;
BA_ "SystemSignalLongSymbol" SG_ 2164120064 Joystick_3_X_Axis_Lever_Right_Po "Joystick 3 X-Axis Lever Right Positive Position Status";
BA_ "SPN" SG_ 2164120064 Joystick_3_X_Axis_Position 2734;
BA_ "SPN" SG_ 2164120064 Joystick_3_Y_Axis_Neutral_Positi 2750;
BA_ "SystemSignalLongSymbol" SG_ 2164120064 Joystick_3_Y_Axis_Neutral_Positi "Joystick 3 Y-Axis Neutral Position Status";
BA_ "SPN" SG_ 2164120064 Joystick_3_Y_Axis_Lever_Back_Neg 2745;
BA_ "SystemSignalLongSymbol" SG_ 2164120064 Joystick_3_Y_Axis_Lever_Back_Neg "Joystick 3 Y-Axis Lever Back Negative Position Status";
BA_ "SPN" SG_ 2164120064 Joystick_3_Y_Axis_Lever_Forward_ 2740;
BA_ "SystemSignalLongSymbol" SG_ 2164120064 Joystick_3_Y_Axis_Lever_Forward_ "Joystick 3 Y-Axis Lever Forward Positive Position Status";
BA_ "SPN" SG_ 2164120064 Joystick_3_Y_Axis_Position 2735;
BA_ "SPN" SG_ 2164120064 Joystick_3_Y_Axis_Detent_Positio 2755;
BA_ "SystemSignalLongSymbol" SG_ 2164120064 Joystick_3_Y_Axis_Detent_Positio "Joystick 3 Y-Axis Detent Position Status";
BA_ "SPN" SG_ 2164120064 Joystick_3_X_Axis_Detent_Positio 2754;
BA_ "SystemSignalLongSymbol" SG_ 2164120064 Joystick_3_X_Axis_Detent_Positio "Joystick 3 X-Axis Detent Position Status";
BA_ "SPN" SG_ 2164120064 Joystick_3_Button_4_Pressed_Stat 2762;
BA_ "SystemSignalLongSymbol" SG_ 2164120064 Joystick_3_Button_4_Pressed_Stat "Joystick 3 Button 4 Pressed Status";
BA_ "SPN" SG_ 2164120064 Joystick_3_Button_3_Pressed_Stat 2761;
BA_ "SystemSignalLongSymbol" SG_ 2164120064 Joystick_3_Button_3_Pressed_Stat "Joystick 3 Button 3 Pressed Status";
BA_ "SPN" SG_ 2164120064 Joystick_3_Button_2_Pressed_Stat 2760;
BA_ "SystemSignalLongSymbol" SG_ 2164120064 Joystick_3_Button_2_Pressed_Stat "Joystick 3 Button 2 Pressed Status";
BA_ "SPN" SG_ 2164120064 Joystick_3_Button_1_Pressed_Stat 2759;
BA_ "SystemSignalLongSymbol" SG_ 2164120064 Joystick_3_Button_1_Pressed_Stat "Joystick 3 Button 1 Pressed Status";
BA_ "SPN" SG_ 2164120064 Joystick_3_Button_8_Pressed_Stat 2766;
BA_ "SystemSignalLongSymbol" SG_ 2164120064 Joystick_3_Button_8_Pressed_Stat "Joystick 3 Button 8 Pressed Status";
BA_ "SPN" SG_ 2164120064 Joystick_3_Button_7_Pressed_Stat 2765;
BA_ "SystemSignalLongSymbol" SG_ 2164120064 Joystick_3_Button_7_Pressed_Stat "Joystick 3 Button 7 Pressed Status";
BA_ "SPN" SG_ 2164120064 Joystick_3_Button_6_Pressed_Stat 2764;
BA_ "SystemSignalLongSymbol" SG_ 2164120064 Joystick_3_Button_6_Pressed_Stat "Joystick 3 Button 6 Pressed Status";
BA_ "SPN" SG_ 2164120064 Joystick_3_Button_5_Pressed_Stat 2763;
BA_ "SystemSignalLongSymbol" SG_ 2164120064 Joystick_3_Button_5_Pressed_Stat "Joystick 3 Button 5 Pressed Status";
BA_ "SPN" SG_ 2164120064 Joystick_3_Button_12_Pressed_Sta 2770;
BA_ "SystemSignalLongSymbol" SG_ 2164120064 Joystick_3_Button_12_Pressed_Sta "Joystick 3 Button 12 Pressed Status";
BA_ "SPN" SG_ 2164120064 Joystick_3_Button_11_Pressed_Sta 2769;
BA_ "SystemSignalLongSymbol" SG_ 2164120064 Joystick_3_Button_11_Pressed_Sta "Joystick 3 Button 11 Pressed Status";
BA_ "SPN" SG_ 2164120064 Joystick_3_Button_10_Pressed_Sta 2768;
BA_ "SystemSignalLongSymbol" SG_ 2164120064 Joystick_3_Button_10_Pressed_Sta "Joystick 3 Button 10 Pressed Status";
BA_ "SPN" SG_ 2164120064 Joystick_3_Button_9_Pressed_Stat 2767;
BA_ "SystemSignalLongSymbol" SG_ 2164120064 Joystick_3_Button_9_Pressed_Stat "Joystick 3 Button 9 Pressed Status";
BA_ "SPN" SG_ 2164120320 Joystick_3_Grip_X_Axis_Neutral_P 2751;
BA_ "SystemSignalLongSymbol" SG_ 2164120320 Joystick_3_Grip_X_Axis_Neutral_P "Joystick 3 Grip X-Axis Neutral Position Status";
BA_ "SPN" SG_ 2164120320 Joystick_3_Grip_X_Axis_Lever_Lef 2746;
BA_ "SystemSignalLongSymbol" SG_ 2164120320 Joystick_3_Grip_X_Axis_Lever_Lef "Joystick 3 Grip X-Axis Lever Left Negative Position Status";
BA_ "SPN" SG_ 2164120320 Joystick_3_Grip_X_Axis_Lever_Rig 2741;
BA_ "SystemSignalLongSymbol" SG_ 2164120320 Joystick_3_Grip_X_Axis_Lever_Rig "Joystick 3 Grip X-Axis Lever Right Positive Position Status";
BA_ "SPN" SG_ 2164120320 Joystick_3_Grip_X_Axis_Position 2736;
BA_ "SPN" SG_ 2164120320 Joystick_3_Grip_Y_Axis_Neutral_P 2752;
BA_ "SystemSignalLongSymbol" SG_ 2164120320 Joystick_3_Grip_Y_Axis_Neutral_P "Joystick 3 Grip Y-Axis Neutral Position Status";
BA_ "SPN" SG_ 2164120320 Joystick_3_Grip_Y_Axis_Lever_Bac 2747;
BA_ "SystemSignalLongSymbol" SG_ 2164120320 Joystick_3_Grip_Y_Axis_Lever_Bac "Joystick 3 Grip Y-Axis Lever Back Negative Position Status";
BA_ "SPN" SG_ 2164120320 Joystick_3_Grip_Y_Axis_Lever_For 2742;
BA_ "SystemSignalLongSymbol" SG_ 2164120320 Joystick_3_Grip_Y_Axis_Lever_For "Joystick 3 Grip Y-Axis Lever Forward Positive Position Status";
BA_ "SPN" SG_ 2164120320 Joystick_3_Grip_Y_Axis_Position 2737;
BA_ "SPN" SG_ 2164120320 Joystick_3_Theta_Axis_Neutral_Po 2753;
BA_ "SystemSignalLongSymbol" SG_ 2164120320 Joystick_3_Theta_Axis_Neutral_Po "Joystick 3 Theta-Axis Neutral Position Status";
BA_ "SPN" SG_ 2164120320 Joystick_3_Theta_Axis_Counter_Cl 2748;
BA_ "SystemSignalLongSymbol" SG_ 2164120320 Joystick_3_Theta_Axis_Counter_Cl "Joystick 3 Theta-Axis Counter Clockwise Negative Position Status";
BA_ "SPN" SG_ 2164120320 Joystick_3_Theta_Axis_Clockwise_ 2743;
BA_ "SystemSignalLongSymbol" SG_ 2164120320 Joystick_3_Theta_Axis_Clockwise_ "Joystick 3 Theta-Axis Clockwise Positive Position Status";
BA_ "SPN" SG_ 2164120320 Joystick_3_Theta_Axis_Position 2738;
BA_ "SPN" SG_ 2164120320 Joystick_3_Theta_Axis_Detent_Pos 2758;
BA_ "SystemSignalLongSymbol" SG_ 2164120320 Joystick_3_Theta_Axis_Detent_Pos "Joystick 3 Theta-Axis Detent Position Status";
BA_ "SPN" SG_ 2164120320 Joystick_3_Grip_Y_Axis_Detent_Po 2757;
BA_ "SystemSignalLongSymbol" SG_ 2164120320 Joystick_3_Grip_Y_Axis_Detent_Po "Joystick 3 Grip Y-Axis Detent Position Status";
BA_ "SPN" SG_ 2164120320 Joystick_3_Grip_X_Axis_Detent_Po 2756;
BA_ "SystemSignalLongSymbol" SG_ 2164120320 Joystick_3_Grip_X_Axis_Detent_Po "Joystick 3 Grip X-Axis Detent Position Status";
BA_ "SPN" SG_ 2164120576 Engine_Throttle_Synchronization_ 2615;
BA_ "SystemSignalLongSymbol" SG_ 2164120576 Engine_Throttle_Synchronization_ "Engine Throttle Synchronization Mode Status";
BA_ "SPN" SG_ 2164120576 Trolling_Mode_Status 2616;
BA_ "SPN" SG_ 2164120576 Slow_Vessel_Mode_Status 2617;
BA_ "SPN" SG_ 2164121344 Front_Wheel_Drive_Actuator_Statu 2612;
BA_ "SystemSignalLongSymbol" SG_ 2164121344 Front_Wheel_Drive_Actuator_Statu "Front Wheel Drive Actuator Status";
BA_ "SPN" SG_ 2164121600 Solar_Intensity_Percent 2610;
BA_ "SPN" SG_ 2164121600 Solar_Sensor_Maximum 2611;
BA_ "SPN" SG_ 2164121600 Specific_Humidity 4490;
BA_ "SPN" SG_ 2164121856 Cab_A_C_Refrigerant_Compressor_O 2609;
BA_ "SystemSignalLongSymbol" SG_ 2164121856 Cab_A_C_Refrigerant_Compressor_O "Cab A/C Refrigerant Compressor Outlet Pressure";
BA_ "SPN" SG_ 2164122112 Pneumatic_Supply_Pressure_Reques 2603;
BA_ "SystemSignalLongSymbol" SG_ 2164122112 Pneumatic_Supply_Pressure_Reques "Pneumatic Supply Pressure Request";
BA_ "SPN" SG_ 2164122112 Parking_and_or_Trailer_Air_Press 2604;
BA_ "SystemSignalLongSymbol" SG_ 2164122112 Parking_and_or_Trailer_Air_Press "Parking and/or Trailer Air Pressure Request";
BA_ "SPN" SG_ 2164122112 Service_Brake_Air_Pressure_Reque0 2605;
BA_ "SystemSignalLongSymbol" SG_ 2164122112 Service_Brake_Air_Pressure_Reque0 "Service Brake Air Pressure Request, Circuit #1";
BA_ "SPN" SG_ 2164122112 Service_Brake_Air_Pressure_Reque1 2606;
BA_ "SystemSignalLongSymbol" SG_ 2164122112 Service_Brake_Air_Pressure_Reque1 "Service Brake Air Pressure Request, Circuit #2";
BA_ "SPN" SG_ 2164122112 Auxiliary_Equipment_Supply_Press 2607;
BA_ "SystemSignalLongSymbol" SG_ 2164122112 Auxiliary_Equipment_Supply_Press "Auxiliary Equipment Supply Pressure Request";
BA_ "SPN" SG_ 2164122112 Air_Suspension_Supply_Pressure_R 2608;
BA_ "SystemSignalLongSymbol" SG_ 2164122112 Air_Suspension_Supply_Pressure_R "Air Suspension Supply Pressure Request";
BA_ "SPN" SG_ 2164122368 Travel_Velocity_Control_Position 2601;
BA_ "SPN" SG_ 2164122624 Payload_Percentage 2600;
BA_ "SPN" SG_ 2164122880 Maximum_Vehicle_Speed_Limit_1 2588;
BA_ "SPN" SG_ 2164122880 Maximum_Vehicle_Speed_Limit_2 2589;
BA_ "SPN" SG_ 2164122880 Maximum_Vehicle_Speed_Limit_3 2590;
BA_ "SPN" SG_ 2164122880 Maximum_Vehicle_Speed_Limit_4 2591;
BA_ "SPN" SG_ 2164122880 Maximum_Vehicle_Speed_Limit_5 2592;
BA_ "SPN" SG_ 2164122880 Maximum_Vehicle_Speed_Limit_6 2593;
BA_ "SPN" SG_ 2164122880 Maximum_Vehicle_Speed_Limit_7 2594;
BA_ "SPN" SG_ 2164122880 Applied_Vehicle_Speed_Limit 2595;
BA_ "SPN" SG_ 2164123136 Hydraulic_Brake_Pressure_Circuit0 2580;
BA_ "SystemSignalLongSymbol" SG_ 2164123136 Hydraulic_Brake_Pressure_Circuit0 "Hydraulic Brake Pressure Circuit 1";
BA_ "SPN" SG_ 2164123136 Hydraulic_Brake_Pressure_Circuit1 2581;
BA_ "SystemSignalLongSymbol" SG_ 2164123136 Hydraulic_Brake_Pressure_Circuit1 "Hydraulic Brake Pressure Circuit 2";
BA_ "SPN" SG_ 2164123136 Hydraulic_Brake_Pressure_Warning0 2584;
BA_ "SystemSignalLongSymbol" SG_ 2164123136 Hydraulic_Brake_Pressure_Warning0 "Hydraulic Brake Pressure Warning State Circuit 1";
BA_ "SPN" SG_ 2164123136 Hydraulic_Brake_Pressure_Warning1 2585;
BA_ "SystemSignalLongSymbol" SG_ 2164123136 Hydraulic_Brake_Pressure_Warning1 "Hydraulic Brake Pressure Warning State Circuit 2";
BA_ "SPN" SG_ 2164123136 Hydraulic_Brake_Pressure_Supply_0 2582;
BA_ "SystemSignalLongSymbol" SG_ 2164123136 Hydraulic_Brake_Pressure_Supply_0 "Hydraulic Brake Pressure Supply State Circuit 1";
BA_ "SPN" SG_ 2164123136 Hydraulic_Brake_Pressure_Supply_1 2583;
BA_ "SystemSignalLongSymbol" SG_ 2164123136 Hydraulic_Brake_Pressure_Supply_1 "Hydraulic Brake Pressure Supply State Circuit 2";
BA_ "SPN" SG_ 2164123136 Hydraulic_Brake_System_Audible_W 2930;
BA_ "SystemSignalLongSymbol" SG_ 2164123136 Hydraulic_Brake_System_Audible_W "Hydraulic Brake System Audible Warning Command";
BA_ "SPN" SG_ 2164123136 Hydraulic_Brake_Fluid_Level_Swit 2931;
BA_ "SystemSignalLongSymbol" SG_ 2164123136 Hydraulic_Brake_Fluid_Level_Swit "Hydraulic Brake Fluid Level Switch";
BA_ "SPN" SG_ 2164131584 Engine_Exhaust_Gas_Temperature__ 2434;
BA_ "SystemSignalLongSymbol" SG_ 2164131584 Engine_Exhaust_Gas_Temperature__ "Engine Exhaust Gas Temperature - Left Manifold";
BA_ "SPN" SG_ 2164146176 Running_Light 2404;
BA_ "SPN" SG_ 2164146176 Alternate_Beam_Head_Light_Data 2352;
BA_ "SPN" SG_ 2164146176 Low_Beam_Head_Light_Data 2350;
BA_ "SPN" SG_ 2164146176 High_Beam_Head_Light_Data 2348;
BA_ "SPN" SG_ 2164146176 Tractor_Front_Fog_Lights 2388;
BA_ "SPN" SG_ 2164146176 Rotating_Beacon_Light 2386;
BA_ "SPN" SG_ 2164146176 Right_Turn_Signal_Lights 2370;
BA_ "SPN" SG_ 2164146176 Left_Turn_Signal_Lights 2368;
BA_ "SPN" SG_ 2164146176 Back_Up_Light_and_Alarm_Horn 2392;
BA_ "SPN" SG_ 2164146176 Center_Stop_Light 2376;
BA_ "SPN" SG_ 2164146176 Right_Stop_Light 2374;
BA_ "SPN" SG_ 2164146176 Left_Stop_Light 2372;
BA_ "SPN" SG_ 2164146176 Implement_Clearance_Light 2384;
BA_ "SPN" SG_ 2164146176 Tractor_Clearance_Light 2382;
BA_ "SPN" SG_ 2164146176 Implement_Marker_Light 2380;
BA_ "SPN" SG_ 2164146176 Tractor_Marker_Light 2378;
BA_ "SPN" SG_ 2164146176 Rear_Fog_Lights 2390;
BA_ "SPN" SG_ 2164146176 Tractor_Underside_Mounted_Work_L 2358;
BA_ "SystemSignalLongSymbol" SG_ 2164146176 Tractor_Underside_Mounted_Work_L "Tractor Underside Mounted Work Lights";
BA_ "SPN" SG_ 2164146176 Tractor_Rear_Low_Mounted_Work_Li 2360;
BA_ "SystemSignalLongSymbol" SG_ 2164146176 Tractor_Rear_Low_Mounted_Work_Li "Tractor Rear Low Mounted Work Lights";
BA_ "SPN" SG_ 2164146176 Tractor_Rear_High_Mounted_Work_L 2362;
BA_ "SystemSignalLongSymbol" SG_ 2164146176 Tractor_Rear_High_Mounted_Work_L "Tractor Rear High Mounted Work Lights";
BA_ "SPN" SG_ 2164146176 Tractor_Side_Low_Mounted_Work_Li 2364;
BA_ "SystemSignalLongSymbol" SG_ 2164146176 Tractor_Side_Low_Mounted_Work_Li "Tractor Side Low Mounted Work Lights";
BA_ "SPN" SG_ 2164146176 Tractor_Side_High_Mounted_Work_L 2366;
BA_ "SystemSignalLongSymbol" SG_ 2164146176 Tractor_Side_High_Mounted_Work_L "Tractor Side High Mounted Work Lights";
BA_ "SPN" SG_ 2164146176 Tractor_Front_Low_Mounted_Work_L 2354;
BA_ "SystemSignalLongSymbol" SG_ 2164146176 Tractor_Front_Low_Mounted_Work_L "Tractor Front Low Mounted Work Lights";
BA_ "SPN" SG_ 2164146176 Tractor_Front_High_Mounted_Work_ 2356;
BA_ "SystemSignalLongSymbol" SG_ 2164146176 Tractor_Front_High_Mounted_Work_ "Tractor Front High Mounted Work Lights";
BA_ "SPN" SG_ 2164146176 Implement_OEM_Option_2_Light 2398;
BA_ "SPN" SG_ 2164146176 Implement_OEM_Option_1_Light 2396;
BA_ "SPN" SG_ 2164146176 Implement_Right_Facing_Work_Ligh 2407;
BA_ "SystemSignalLongSymbol" SG_ 2164146176 Implement_Right_Facing_Work_Ligh "Implement Right Facing Work Light";
BA_ "SPN" SG_ 2164146176 Implement_Left_Facing_Work_Light 2598;
BA_ "SPN" SG_ 2164146176 Implement_Right_Forward_Work_Lig 2402;
BA_ "SystemSignalLongSymbol" SG_ 2164146176 Implement_Right_Forward_Work_Lig "Implement Right Forward Work Light";
BA_ "SPN" SG_ 2164146176 Implement_Left_Forward_Work_Ligh 2400;
BA_ "SystemSignalLongSymbol" SG_ 2164146176 Implement_Left_Forward_Work_Ligh "Implement Left Forward Work Light";
BA_ "SPN" SG_ 2164146176 Implement_Rear_Work_Light 2394;
